VERSION ""

NS_ :

BS_:

BU_: IHU

BO_ 1177 IHU_26: 8 IHU
 SG_ IHU_26_RRWinCmd : 62|7@0+ (1,0) [0|127] "" Vector__XXX
 SG_ IHU_26_Reserved2 : 48|2@0+ (1,0) [0|0] "" Vector__XXX
 SG_ IHU_26_WiprSnvty : 51|3@0+ (1,0) [0|7] "" Vector__XXX
 SG_ IHU_26_SeatLegSpprtPosnCmd : 55|4@0+ (1,0) [0|15] "" Vector__XXX
 SG_ IHU_26_RLWinCmd : 46|7@0+ (1,0) [0|127] "" Vector__XXX
 SG_ IHU_26_FRWinCmd : 37|7@0+ (1,0) [0|127] "" Vector__XXX
 SG_ IHU_26_FLWinCmd : 28|7@0+ (1,0) [0|127] "" Vector__XXX
 SG_ IHU_26_Reserved1 : 29|1@0+ (1,0) [0|0] "" Vector__XXX
 SG_ IHU_26_CenterLockSwt : 31|2@0+ (1,0) [0|3] "" Vector__XXX
 SG_ IHU_26_SeatLvlPosnCmd : 23|4@0+ (1,0) [0|15] "" Vector__XXX
 SG_ IHU_26_SeatHdrestHeiAdjmtCmd : 19|4@0+ (1,0) [0|15] "" Vector__XXX
 SG_ IHU_26_WinInhbSwt : 15|1@0+ (1,0) [0|1] "" Vector__XXX
 SG_ IHU_26_ReWinDefrstSwt : 14|1@0+ (1,0) [0|1] "" Vector__XXX
 SG_ IHU_26_SteerWhlHeatgSwt : 13|1@0+ (1,0) [0|1] "" Vector__XXX
 SG_ IHU_26_BackrAgPosnCmd : 12|5@0+ (1,0) [0|31] "" Vector__XXX
 SG_ IHU_26_SeatCushPosnCmd : 7|4@0+ (1,0) [0|15] "" Vector__XXX
 SG_ IHU_26_SeatHeiPosnCmd : 3|4@0+ (1,0) [0|15] "" Vector__XXX

BO_ 643 IHU_25: 8 IHU
 SG_ IHU_25__Resd2 : 63|1@0+ (1,0) [0|0] "" Vector__XXX
 SG_ IHU_25_APPsts : 62|1@0+ (1,0) [0|1] "" Vector__XXX
 SG_ IHU_25_AmbLigFlngModSel : 58|3@0+ (1,0) [0|7] "" Vector__XXX
 SG_ IHU_25_AmbLig14FlngEna : 55|1@0+ (1,0) [0|1] "" Vector__XXX
 SG_ IHU_25_AmbLig13FlngEna : 47|1@0+ (1,0) [0|1] "" Vector__XXX
 SG_ IHU_25_AmbLig12FlngEna : 46|1@0+ (1,0) [0|1] "" Vector__XXX
 SG_ IHU_25_AmbLigFadeINOUTStepTi : 54|7@0+ (1,0) [0|127] "" Vector__XXX
 SG_ IHU_25_AmbLig14FadeEna : 45|1@0+ (1,0) [0|1] "" Vector__XXX
 SG_ IHU_25_AmbLig13FadeEna : 44|1@0+ (1,0) [0|1] "" Vector__XXX
 SG_ IHU_25_AmbLig12FadeEna : 43|1@0+ (1,0) [0|1] "" Vector__XXX
 SG_ IHU_25_AmbLig11FadeEna : 42|1@0+ (1,0) [0|1] "" Vector__XXX
 SG_ IHU_25_AmbLig10FadeEna : 41|1@0+ (1,0) [0|1] "" Vector__XXX
 SG_ IHU_25_AmbLig09FadeEna : 40|1@0+ (1,0) [0|1] "" Vector__XXX
 SG_ IHU_25_AmbLig08FadeEna : 39|1@0+ (1,0) [0|1] "" Vector__XXX
 SG_ IHU_25_AmbLig07FadeEna : 38|1@0+ (1,0) [0|1] "" Vector__XXX
 SG_ IHU_25_AmbLig06FadeEna : 37|1@0+ (1,0) [0|1] "" Vector__XXX
 SG_ IHU_25_AmbLig05FadeEna : 36|1@0+ (1,0) [0|1] "" Vector__XXX
 SG_ IHU_25_AmbLig04FadeEna : 35|1@0+ (1,0) [0|1] "" Vector__XXX
 SG_ IHU_25_AmbLig03FadeEna : 34|1@0+ (1,0) [0|1] "" Vector__XXX
 SG_ IHU_25_AmbLig02FadeEna : 33|1@0+ (1,0) [0|1] "" Vector__XXX
 SG_ IHU_25_AmbLig01FadeEna : 32|1@0+ (1,0) [0|1] "" Vector__XXX
 SG_ IHU_25_AmbLigColorAdj : 31|8@0+ (1,0) [0|255] "" Vector__XXX
 SG_ IHU_25_AmbLigBriAdj : 23|8@0+ (1,0) [0|100] "%" Vector__XXX
 SG_ IHU_25__Resd1 : 15|2@0+ (1,0) [0|0] "" Vector__XXX
 SG_ IHU_25_AmbLig14Authn : 13|1@0+ (1,0) [0|1] "" Vector__XXX
 SG_ IHU_25_AmbLig13Authn : 12|1@0+ (1,0) [0|1] "" Vector__XXX
 SG_ IHU_25_AmbLig12Authn : 11|1@0+ (1,0) [0|1] "" Vector__XXX
 SG_ IHU_25_AmbLig11Authn : 10|1@0+ (1,0) [0|1] "" Vector__XXX
 SG_ IHU_25_AmbLig10Authn : 9|1@0+ (1,0) [0|1] "" Vector__XXX
 SG_ IHU_25_AmbLig09Authn : 8|1@0+ (1,0) [0|1] "" Vector__XXX
 SG_ IHU_25_AmbLig08Authn : 7|1@0+ (1,0) [0|1] "" Vector__XXX
 SG_ IHU_25_AmbLig07Authn : 6|1@0+ (1,0) [0|1] "" Vector__XXX
 SG_ IHU_25_AmbLig06Authn : 5|1@0+ (1,0) [0|1] "" Vector__XXX
 SG_ IHU_25_AmbLig05Authn : 4|1@0+ (1,0) [0|1] "" Vector__XXX
 SG_ IHU_25_AmbLig04Authn : 3|1@0+ (1,0) [0|1] "" Vector__XXX
 SG_ IHU_25_AmbLig03Authn : 2|1@0+ (1,0) [0|1] "" Vector__XXX
 SG_ IHU_25_AmbLig02Authn : 1|1@0+ (1,0) [0|1] "" Vector__XXX
 SG_ IHU_25_AmbLig01Authn : 0|1@0+ (1,0) [0|1] "" Vector__XXX

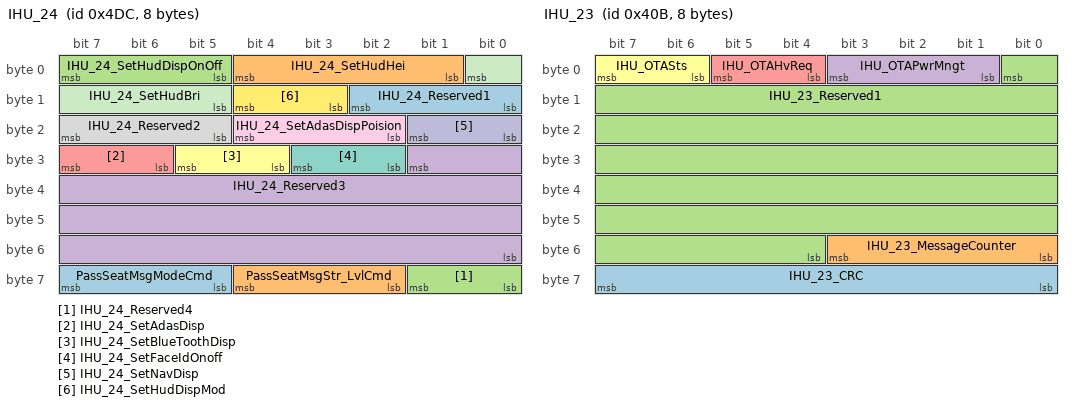
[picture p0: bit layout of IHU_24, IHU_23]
BO_ 1244 IHU_24: 8 IHU
 SG_ PassSeatMsgModeCmd : 63|3@0+ (1,0) [0|7] "" Vector__XXX
 SG_ PassSeatMsgStr_LvlCmd : 60|3@0+ (1,0) [0|7] "" Vector__XXX
 SG_ IHU_24_Reserved4 : 57|2@0+ (1,0) [0|0] "" Vector__XXX
 SG_ IHU_24_Reserved3 : 25|26@0+ (1,0) [0|0] "" Vector__XXX
 SG_ IHU_24_SetAdasDisp : 31|2@0+ (1,0) [0|3] "" Vector__XXX
 SG_ IHU_24_SetBlueToothDisp : 29|2@0+ (1,0) [0|3] "" Vector__XXX
 SG_ IHU_24_SetFaceIdOnoff : 27|2@0+ (1,0) [0|3] "" Vector__XXX
 SG_ IHU_24_Reserved2 : 23|3@0+ (1,0) [0|0] "" Vector__XXX
 SG_ IHU_24_SetAdasDispPoision : 20|3@0+ (1,0) [0|7] "" Vector__XXX
 SG_ IHU_24_SetNavDisp : 17|2@0+ (1,0) [0|3] "" Vector__XXX
 SG_ IHU_24_SetHudBri : 0|4@0+ (1,0) [0|15] "" Vector__XXX
 SG_ IHU_24_SetHudDispMod : 12|2@0+ (1,0) [0|3] "" Vector__XXX
 SG_ IHU_24_Reserved1 : 10|3@0+ (1,0) [0|0] "" Vector__XXX
 SG_ IHU_24_SetHudHei : 4|4@0+ (1,0) [0|15] "" Vector__XXX
 SG_ IHU_24_SetHudDispOnOff : 7|3@0+ (1,0) [0|7] "" Vector__XXX

BO_ 1035 IHU_23: 8 IHU
 SG_ IHU_23_CRC : 63|8@0+ (1,0) [0|255] "" Vector__XXX
 SG_ IHU_23_MessageCounter : 51|4@0+ (1,0) [0|15] "" Vector__XXX
 SG_ IHU_23_Reserved1 : 0|45@0+ (1,0) [0|0] "" Vector__XXX
 SG_ IHU_OTAPwrMngt : 3|3@0+ (1,0) [0|7] "" Vector__XXX
 SG_ IHU_OTAHvReq : 5|2@0+ (1,0) [0|3] "" Vector__XXX
 SG_ IHU_OTASts : 7|2@0+ (1,0) [0|3] "" Vector__XXX

BO_ 1278 IHU_22: 8 IHU
 SG_ IHU_22_Reserved1 : 53|14@0+ (1,0) [0|0] "" Vector__XXX
 SG_ IHU_SHU1RSeatAutVentnCmd : 55|2@0+ (1,0) [0|3] "" Vector__XXX
 SG_ IHU_SHU1LSeatAutVentnCmd : 41|2@0+ (1,0) [0|3] "" Vector__XXX
 SG_ IHU_SHU1RSeatAutHeatCmd : 45|2@0+ (1,0) [0|3] "" Vector__XXX
 SG_ IHU_SHU1LSeatAutHeatCmd : 43|2@0+ (1,0) [0|3] "" Vector__XXX
 SG_ SHU3RSeatVentilationCmd : 32|3@0+ (1,0) [0|7] "" Vector__XXX
 SG_ SHU3LSeatVentilationCmd : 35|3@0+ (1,0) [0|7] "" Vector__XXX
 SG_ SHU3RSeatHeatLevelCmd : 38|3@0+ (1,0) [0|7] "" Vector__XXX
 SG_ SHU3LSeatHeatLevelCmd : 25|3@0+ (1,0) [0|7] "" Vector__XXX
 SG_ SHU2RSeatVentilationCmd : 28|3@0+ (1,0) [0|7] "" Vector__XXX
 SG_ SHU2MSeatVentilationCmd : 31|3@0+ (1,0) [0|7] "" Vector__XXX
 SG_ SHU2LSeatVentilationCmd : 18|3@0+ (1,0) [0|7] "" Vector__XXX
 SG_ SHU2RSeatHeatLevelCmd : 21|3@0+ (1,0) [0|7] "" Vector__XXX
 SG_ SHU2MSeatHeatLevelCmd : 8|3@0+ (1,0) [0|7] "" Vector__XXX
 SG_ SHU2LSeatHeatLevelCmd : 11|3@0+ (1,0) [0|7] "" Vector__XXX
 SG_ SHU1RSeatVentilationCmd : 14|3@0+ (1,0) [0|7] "" Vector__XXX
 SG_ SHU1LSeatVentilationCmd : 1|3@0+ (1,0) [0|7] "" Vector__XXX
 SG_ SHU1RSeatHeatLevelCmd : 4|3@0+ (1,0) [0|7] "" Vector__XXX
 SG_ SHU1LSeatHeatLevelCmd : 7|3@0+ (1,0) [0|7] "" Vector__XXX

BO_ 1119 IHU_19: 8 IHU
 SG_ IHU_19_Reserved_1 : 53|14@0+ (1,0) [0|0] "" Vector__XXX
 SG_ IHU_19_Set_HdrestSpkrMod : 40|3@0+ (1,0) [0|7] "" Vector__XXX
 SG_ IHU_19_Set_AMPESEVol : 46|6@0+ (1,0) [0|63] "" Vector__XXX
 SG_ IHU_19_Set_AMPWelVol : 36|6@0+ (1,0) [0|63] "" Vector__XXX
 SG_ IHU_19_Set_AMPBTMediVol : 26|6@0+ (1,0) [0|63] "" Vector__XXX
 SG_ IHU_19_REQ_AMPA2BMediSound : 29|3@0+ (1,0) [0|7] "" Vector__XXX
 SG_ IHU_19_REQ_AMPA2BESESound : 31|2@0+ (1,0) [0|3] "" Vector__XXX
 SG_ IHU_19_PABSetCmd : 17|2@0+ (1,0) [0|3] "" Vector__XXX
 SG_ IHU_19_HwSet : 19|2@0+ (1,0) [0|3] "" Vector__XXX
 SG_ IHU_19_BSRBPASet : 21|2@0+ (1,0) [0|3] "" Vector__XXX
 SG_ REQ_AMPA2BKeyTone : 23|2@0+ (1,0) [0|3] "" Vector__XXX
 SG_ REQ_AMPA2BTTSSound : 15|2@0+ (1,0) [0|3] "" Vector__XXX
 SG_ REQ_AMPA2BVRSound : 13|2@0+ (1,0) [0|3] "" Vector__XXX
 SG_ REQ_AMPA2BNaviSound : 11|2@0+ (1,0) [0|3] "" Vector__XXX
 SG_ IHU_19_Reserved_2 : 9|2@0+ (1,0) [0|3] "" Vector__XXX
 SG_ Set_AMPMute : 7|2@0+ (1,0) [0|3] "" Vector__XXX
 SG_ Set_AMPSpeedVolume : 5|3@0+ (1,0) [0|7] "" Vector__XXX
 SG_ REQ_AMPA2BPhoneSound : 2|3@0+ (1,0) [0|7] "" Vector__XXX

BO_ 1100 IHU_18: 8 IHU
 SG_ Set_AMPAlarmVolume : 63|4@0+ (1,0) [1|15] "" Vector__XXX
 SG_ Set_AMPLoudness : 59|2@0+ (1,0) [0|3] "" Vector__XXX
 SG_ Set_AMPLiveAcoustics : 57|2@0+ (1,0) [0|3] "" Vector__XXX
 SG_ Set_AMPSoundFieldFader : 55|4@0+ (1,0) [0|15] "" Vector__XXX
 SG_ Set_AMPSoundFieldBalance : 51|4@0+ (1,0) [0|15] "" Vector__XXX
 SG_ Set_AMPSoundEffectTreble : 47|4@0+ (1,0) [0|15] "" Vector__XXX
 SG_ Set_AMPSoundEffectMidrange : 43|4@0+ (1,0) [0|15] "" Vector__XXX
 SG_ Set_AMPSoundEffectBass : 39|4@0+ (1,0) [0|15] "" Vector__XXX
 SG_ Set_AMPSoundEffect : 35|4@0+ (1,0) [0|15] "" Vector__XXX
 SG_ Set_AMPRestoreDefaults : 31|2@0+ (1,0) [0|3] "" Vector__XXX
 SG_ Set_AMPDefaultVolume : 29|6@0+ (1,0) [0|63] "" Vector__XXX
 SG_ Set_AMPSoundFocus : 23|3@0+ (1,0) [0|7] "" Vector__XXX
 SG_ Set_AMPPhoneVolume : 20|5@0+ (1,0) [0|31] "" Vector__XXX
 SG_ Set_AMPMediaVolume : 15|6@0+ (1,0) [0|63] "" Vector__XXX
 SG_ Set_AMPKeyTone : 9|2@0+ (1,0) [0|3] "" Vector__XXX
 SG_ Set_AMPVRVolume : 7|4@0+ (1,0) [0|15] "" Vector__XXX
 SG_ Set_AMPNaviVolume : 3|4@0+ (1,0) [0|15] "" Vector__XXX

BO_ 1065 IHU_16: 8 IHU
 SG_ IHU_16_Reserved3 : 42|19@0+ (1,0) [0|0] "" Vector__XXX
 SG_ IHU_16_SetReRowPwrKeyCmd : 43|1@0+ (1,0) [0|1] "" Vector__XXX
 SG_ IHU_16_SetReRowBlowSpdLvlCmd : 46|3@0+ (1,0) [0|7] "" Vector__XXX
 SG_ IHU_16_SetReRowWorkCmd : 47|1@0+ (1,0) [0|1] "" Vector__XXX
 SG_ IHU_FragranceDisplayReq : 33|2@0+ (1,0) [0|3] "" Vector__XXX
 SG_ IHU_PM2_5AutoRunSet : 35|2@0+ (1,0) [0|3] "" Vector__XXX
 SG_ IHU_ANIONSwitch : 37|2@0+ (1,0) [0|3] "" Vector__XXX
 SG_ IHU_RefreshFunction : 39|2@0+ (1,0) [0|3] "" Vector__XXX
 SG_ IHU_ACModeCustom : 31|3@0+ (1,0) [0|7] "" Vector__XXX
 SG_ IHU_FragranCeconsistenceLevel : 28|3@0+ (1,0) [0|7] "" Vector__XXX
 SG_ IHU_FragranceSW : 25|2@0+ (1,0) [0|3] "" Vector__XXX
 SG_ IHU_16_Reserved2 : 18|3@0+ (1,0) [0|0] "" Vector__XXX
 SG_ IHU_16_SetSeBlowSpdLvlDisp : 23|3@0+ (1,0) [0|7] "" Vector__XXX
 SG_ IHU_16_SetSeWorking : 20|1@0+ (1,0) [0|1] "" Vector__XXX
 SG_ IHU_16_SeIntelligentCustom : 19|1@0+ (1,0) [0|1] "" Vector__XXX
 SG_ IHU_16_SetPtcHeatg : 13|1@0+ (1,0) [0|1] "" Vector__XXX
 SG_ IHU_FragranceWelcomeMode : 15|2@0+ (1,0) [0|3] "" Vector__XXX
 SG_ IHU_FragrancePosition : 12|3@0+ (1,0) [0|7] "" Vector__XXX
 SG_ IHU_16_Reserved4 : 9|2@0+ (1,0) [0|0] "" Vector__XXX
 SG_ IHU_AutoBlueCallBlowSpeed : 7|2@0+ (1,0) [0|3] "" Vector__XXX
 SG_ IHU_AutoParkInnerCirculation : 5|2@0+ (1,0) [0|3] "" Vector__XXX
 SG_ IHU_16_Reserved1 : 3|4@0+ (1,0) [0|0] "" Vector__XXX

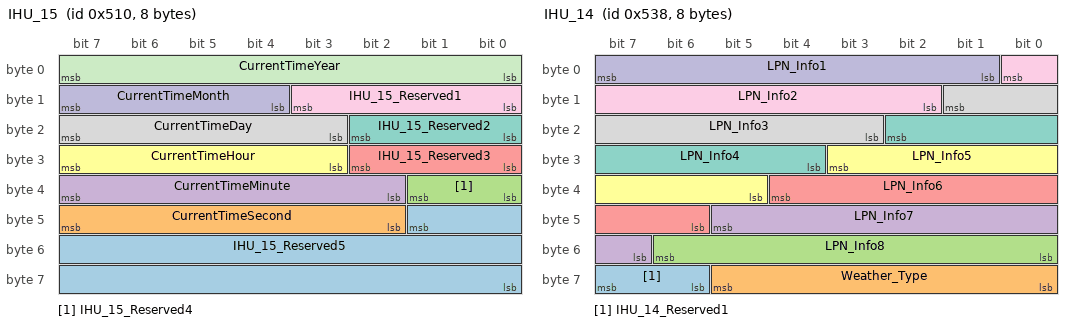
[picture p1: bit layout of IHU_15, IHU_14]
BO_ 1296 IHU_15: 8 IHU
 SG_ IHU_15_Reserved5 : 41|18@0+ (1,0) [0|0] "" Vector__XXX
 SG_ CurrentTimeSecond : 47|6@0+ (1,0) [0|59] "" Vector__XXX
 SG_ IHU_15_Reserved4 : 33|2@0+ (1,0) [0|0] "" Vector__XXX
 SG_ CurrentTimeMinute : 39|6@0+ (1,0) [0|59] "" Vector__XXX
 SG_ IHU_15_Reserved3 : 26|3@0+ (1,0) [0|0] "" Vector__XXX
 SG_ CurrentTimeHour : 31|5@0+ (1,0) [0|23] "" Vector__XXX
 SG_ IHU_15_Reserved2 : 18|3@0+ (1,0) [0|0] "" Vector__XXX
 SG_ CurrentTimeDay : 23|5@0+ (1,0) [1|31] "" Vector__XXX
 SG_ IHU_15_Reserved1 : 11|4@0+ (1,0) [0|0] "" Vector__XXX
 SG_ CurrentTimeMonth : 15|4@0+ (1,0) [1|12] "" Vector__XXX
 SG_ CurrentTimeYear : 7|8@0+ (1,2000) [2000|2255] "" Vector__XXX

BO_ 1336 IHU_14: 8 IHU
 SG_ IHU_14_Reserved1 : 63|2@0+ (1,0) [0|0] "" Vector__XXX
 SG_ Weather_Type : 61|6@0+ (1,0) [0|63] "" Vector__XXX
 SG_ LPN_Info8 : 54|7@0+ (1,0) [0|127] "" Vector__XXX
 SG_ LPN_Info7 : 45|7@0+ (1,0) [0|127] "" Vector__XXX
 SG_ LPN_Info6 : 36|7@0+ (1,0) [0|127] "" Vector__XXX
 SG_ LPN_Info5 : 27|7@0+ (1,0) [0|127] "" Vector__XXX
 SG_ LPN_Info4 : 18|7@0+ (1,0) [0|127] "" Vector__XXX
 SG_ LPN_Info3 : 9|7@0+ (1,0) [0|127] "" Vector__XXX
 SG_ LPN_Info2 : 0|7@0+ (1,0) [0|127] "" Vector__XXX
 SG_ LPN_Info1 : 7|7@0+ (1,0) [0|127] "" Vector__XXX

BO_ 1112 IHU_13: 8 IHU
 SG_ HU_13_Reserved8 : 63|8@0+ (1,0) [0|0] "" Vector__XXX
 SG_ IHU_13_Reserved7 : 55|3@0+ (1,0) [0|0] "" Vector__XXX
 SG_ MusicLoudness_6000HZ : 52|5@0+ (1,0) [0|31] "" Vector__XXX
 SG_ IHU_13_Reserved6 : 47|3@0+ (1,0) [0|0] "" Vector__XXX
 SG_ MusicLoudness_2000HZ : 44|5@0+ (1,0) [0|31] "" Vector__XXX
 SG_ IHU_13_Reserved5 : 39|3@0+ (1,0) [0|0] "" Vector__XXX
 SG_ MusicLoudness_1500HZ : 36|5@0+ (1,0) [0|31] "" Vector__XXX
 SG_ IHU_13_Reserved4 : 31|2@0+ (1,0) [0|0] "" Vector__XXX
 SG_ MusicShowCMD : 29|1@0+ (1,0) [0|1] "" Vector__XXX
 SG_ MusicLoudness_1000HZ : 28|5@0+ (1,0) [0|31] "" Vector__XXX
 SG_ IHU_13_Reserved3 : 23|3@0+ (1,0) [0|0] "" Vector__XXX
 SG_ MusicLoudness_500HZ : 20|5@0+ (1,0) [0|31] "" Vector__XXX
 SG_ LiShowMod : 15|3@0+ (1,0) [0|7] "" Vector__XXX
 SG_ MusicLoudness_250HZ : 12|5@0+ (1,0) [0|31] "" Vector__XXX
 SG_ ADBenable : 7|2@0+ (1,0) [0|3] "" Vector__XXX
 SG_ DVD_StandbyModeSts : 5|1@0+ (1,0) [0|1] "" Vector__XXX
 SG_ MusicLoudness_120HZ : 4|5@0+ (1,0) [0|31] "" Vector__XXX

BO_ 1114 IHU_12: 8 IHU
 SG_ MusicShowCMD : 57|2@0+ (1,0) [0|3] "" Vector__XXX
 SG_ IHU_12_Reserved8 : 63|3@0+ (1,0) [0|0] "" Vector__XXX
 SG_ LightShowCmd : 60|3@0+ (1,0) [0|7] "" Vector__XXX
 SG_ DVRSnapshot : 51|1@0+ (1,0) [0|1] "" Vector__XXX
 SG_ AVMSwt : 50|1@0+ (1,0) [0|1] "" Vector__XXX
 SG_ IHU_12_Reserved6 : 49|2@0+ (1,0) [0|0] "" Vector__XXX
 SG_ TouchEvt : 53|2@0+ (1,0) [0|3] "" Vector__XXX
 SG_ LDWSensitivitySetting : 55|2@0+ (1,0) [0|3] "" Vector__XXX
 SG_ IHU_APAKeySts : 40|1@0+ (1,0) [0|1] "" Vector__XXX
 SG_ IHU_12_Reserved4 : 43|3@0+ (1,0) [0|0] "" Vector__XXX
 SG_ LDWSwitchSts : 45|2@0+ (1,0) [0|3] "" Vector__XXX
 SG_ IHU_12_Reserved3 : 47|2@0+ (1,0) [0|0] "" Vector__XXX
 SG_ IHU_12_DMSSwtSet : 39|2@0+ (1,0) [0|3] "" Vector__XXX
 SG_ IHU_12_CarMdlSetColor : 37|4@0+ (1,0) [0|15] "" Vector__XXX
 SG_ CalibrationReq : 33|1@0+ (1,0) [0|1] "" Vector__XXX
 SG_ RRMDisplayAVMOff : 32|1@0+ (1,0) [0|1] "" Vector__XXX
 SG_ NaviBtnPressInputValueY : 23|16@0+ (1,0) [0|65534] "Pixel" Vector__XXX
 SG_ NaviBtnPressInputValueX : 7|16@0+ (1,0) [0|65534] "Pixel" Vector__XXX

BO_ 1276 IHU_11: 8 IHU
 SG_ IHU_11_Reserved3 : 59|4@0+ (1,0) [0|0] "" Vector__XXX
 SG_ IHU_11_ASUStyleSet : 61|2@0+ (1,0) [0|3] "" Vector__XXX
 SG_ IHU_11_ASUAssocWithDrvrModSet : 63|2@0+ (1,0) [0|3] "" Vector__XXX
 SG_ DVD_SET_EPS_Assistance_Style : 49|2@0+ (1,0) [0|3] "" Vector__XXX
 SG_ DVD_SET_EPS_AssociWithDriverMode : 51|2@0+ (1,0) [0|3] "" Vector__XXX
 SG_ IHU_11_ELKSwtSet : 53|2@0+ (1,0) [0|3] "" Vector__XXX
 SG_ IHU_11_LDWLDPSnvtySet : 55|2@0+ (1,0) [0|3] "" Vector__XXX
 SG_ IHU_11_LDPSwtSet : 41|2@0+ (1,0) [0|3] "" Vector__XXX
 SG_ IHU_11_WarnModSwtSet : 43|2@0+ (1,0) [0|3] "" Vector__XXX
 SG_ IHU_11_LDWSwtSet : 45|2@0+ (1,0) [0|3] "" Vector__XXX
 SG_ IHU_11_TLISwtSet : 47|2@0+ (1,0) [0|3] "" Vector__XXX
 SG_ IHU_11_TSISwtSet : 33|2@0+ (1,0) [0|3] "" Vector__XXX
 SG_ IHU_11_HMASwtSet : 35|2@0+ (1,0) [0|3] "" Vector__XXX
 SG_ IHU_11_IESSwtSet : 37|2@0+ (1,0) [0|3] "" Vector__XXX
 SG_ IHU_11_DAISwtSet : 39|2@0+ (1,0) [0|3] "" Vector__XXX
 SG_ IHU_11_Resd2 : 25|2@0+ (1,0) [0|3] "" Vector__XXX
 SG_ IHU_11_SCFSwtSet : 27|2@0+ (1,0) [0|3] "" Vector__XXX
 SG_ IHU_11_SLASwtSet : 29|2@0+ (1,0) [0|3] "" Vector__XXX
 SG_ IHU_11_TJAICAExitTextInfoSwtSet : 31|2@0+ (1,0) [0|3] "" Vector__XXX
 SG_ IHU_11_FCWSwtSet : 17|2@0+ (1,0) [0|3] "" Vector__XXX
 SG_ IHU_11_FCWSnvtySet : 19|2@0+ (1,0) [0|3] "" Vector__XXX
 SG_ IHU_11_AEBSwtSet : 21|2@0+ (1,0) [0|3] "" Vector__XXX
 SG_ IHU_11_RCTBSwtSet : 23|2@0+ (1,0) [0|3] "" Vector__XXX
 SG_ IHU_11_RAEBSwtSet : 9|2@0+ (1,0) [0|3] "" Vector__XXX
 SG_ IHU_11_BSDSwitchSts : 11|2@0+ (1,0) [0|3] "" Vector__XXX
 SG_ DVD_SET_RCW : 13|2@0+ (1,0) [0|3] "" Vector__XXX
 SG_ DVD_SET_DOW : 15|2@0+ (1,0) [0|3] "" Vector__XXX
 SG_ IHU_11_Reserved1 : 0|1@0+ (1,0) [0|0] "" Vector__XXX
 SG_ DVD_SET_CWC_PhoneforgottenFunSts : 2|2@0+ (1,0) [0|3] "" Vector__XXX
 SG_ ModeKeySts : 3|1@0+ (1,0) [0|1] "" Vector__XXX
 SG_ DVD_SET_ModeKeyFunctionType : 5|2@0+ (1,0) [0|3] "" Vector__XXX
 SG_ DVD_SET_CWC_WorkingSts : 7|2@0+ (1,0) [0|3] "" Vector__XXX

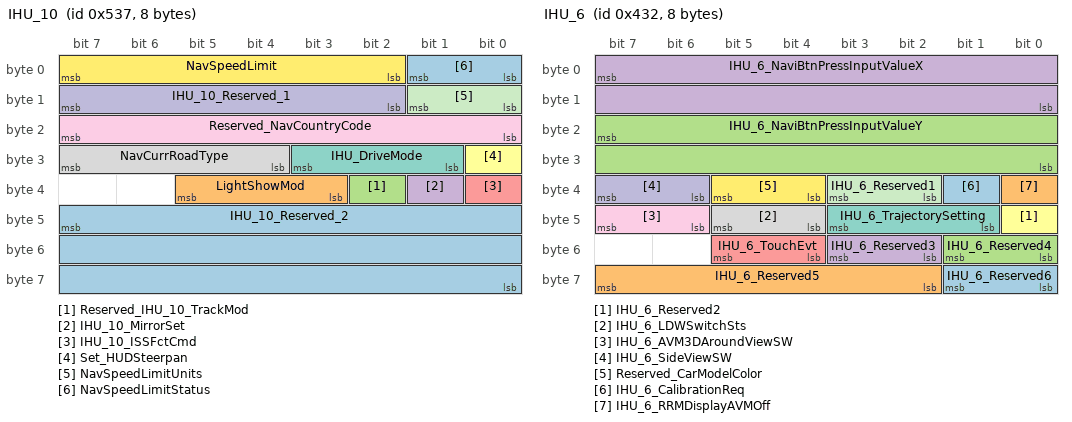
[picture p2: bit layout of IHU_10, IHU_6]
BO_ 1335 IHU_10: 8 IHU
 SG_ IHU_10_Reserved_2 : 47|24@0+ (1,0) [0|0] "" Vector__XXX
 SG_ LightShowMod : 37|3@0+ (1,0) [0|7] "" Vector__XXX
 SG_ Reserved_IHU_10_TrackMod : 34|1@0+ (1,0) [0|1] "" Vector__XXX
 SG_ IHU_10_MirrorSet : 33|1@0+ (1,0) [0|1] "" Vector__XXX
 SG_ IHU_10_ISSFctCmd : 32|1@0+ (1,0) [0|1] "" Vector__XXX
 SG_ Set_HUDSteerpan : 24|1@0+ (1,0) [0|1] "" Vector__XXX
 SG_ IHU_DriveMode : 27|3@0+ (1,0) [0|7] "" Vector__XXX
 SG_ NavCurrRoadType : 31|4@0+ (1,0) [0|15] "" Vector__XXX
 SG_ Reserved_NavCountryCode : 23|8@0+ (1,0) [0|255] "" Vector__XXX
 SG_ IHU_10_Reserved_1 : 15|6@0+ (1,0) [0|0] "" Vector__XXX
 SG_ NavSpeedLimitUnits : 9|2@0+ (1,0) [0|3] "" Vector__XXX
 SG_ NavSpeedLimit : 7|6@0+ (1,0) [0|59] "" Vector__XXX
 SG_ NavSpeedLimitStatus : 1|2@0+ (1,0) [0|3] "" Vector__XXX

BO_ 1273 IHU_9: 8 IHU
 SG_ IHU_SET_AIPMBrightnessLevel : 55|4@0+ (1,0) [0|15] "" Vector__XXX
 SG_ DVD_SetLightedRoofRackStatus : 47|2@0+ (1,0) [0|3] "" Vector__XXX
 SG_ DrvrDoorUnlckOnlyStsSet : 45|2@0+ (1,0) [0|3] "" Vector__XXX
 SG_ BlowSpeedLevelKeySts : 43|4@0+ (1,0) [0|15] "" Vector__XXX
 SG_ IHU_SetTheaterDimmingColor_64 : 39|8@0+ (1,0) [0|255] "" Vector__XXX
 SG_ IHU_9_FrntRadarSwt : 24|1@0+ (1,0) [0|1] "" Vector__XXX
 SG_ IHU_DriverSeatHeatLevelCmd : 63|2@0+ (1,0) [0|3] "" Vector__XXX
 SG_ DVD_SET_BLTKey_PESts : 61|2@0+ (1,0) [0|3] "" Vector__XXX
 SG_ FaceID : 29|3@0+ (1,0) [0|7] "" Vector__XXX
 SG_ Delete_ID_Info : 16|3@0+ (1,0) [0|7] "" Vector__XXX
 SG_ DVD_SET_AutoFoldSts : 59|2@0+ (1,0) [0|3] "" Vector__XXX
 SG_ IHU_DriverSeatVentilationKeySts : 57|2@0+ (1,0) [0|3] "" Vector__XXX
 SG_ DVD_SET_HeadlampHeightSts : 19|3@0+ (1,0) [0|7] "" Vector__XXX
 SG_ Reserved_SASSwitchStatus : 23|2@0+ (1,0) [0|3] "" Vector__XXX
 SG_ Reserved_DVD_SET_RemoteTrunkOnly : 21|2@0+ (1,0) [0|3] "" Vector__XXX
 SG_ Reserved_DVD_SET_UrgeBrakemode : 15|2@0+ (1,0) [0|3] "" Vector__XXX
 SG_ Reserved_DVD_SET_AidTurnIlumin : 13|2@0+ (1,0) [0|3] "" Vector__XXX
 SG_ DVD_SET_DRLModeSts : 11|2@0+ (1,0) [0|3] "" Vector__XXX
 SG_ DVD_SET_HeadlampDelayLightSts : 9|2@0+ (1,0) [0|3] "" Vector__XXX
 SG_ DVD_SET_RemoteLockFeedback : 7|3@0+ (1,0) [0|7] "" Vector__XXX
 SG_ IHU_ISS_Switch : 4|1@0+ (1,0) [0|1] "" Vector__XXX
 SG_ DVD_SET_AutolockSts : 3|2@0+ (1,0) [0|3] "" Vector__XXX
 SG_ Reserved_DVD_SET_AutoUnlockSts : 1|2@0+ (1,0) [0|3] "" Vector__XXX

BO_ 1272 IHU_8: 8 IHU
 SG_ DVD_Set_FGHeatSts : 57|2@0+ (1,0) [0|3] "" Vector__XXX
 SG_ IHU_WindowCmd : 62|5@0+ (1,0) [0|31] "" Vector__XXX
 SG_ IHU_8_Reserved_2 : 48|2@0+ (1,0) [0|0] "" Vector__XXX
 SG_ Set_Default : 44|3@0+ (1,0) [0|7] "" Vector__XXX
 SG_ Seat_ExtMirror_PosStoreReq_ID : 33|5@0+ (1,0) [0|31] "" Vector__XXX
 SG_ Seat_ExtMirror_PosRecall_ID : 38|5@0+ (1,0) [0|31] "" Vector__XXX
 SG_ DVD_Set_ReverseExtMirrorSts : 25|3@0+ (1,0) [0|7] "" Vector__XXX
 SG_ DVD_Set_EasyEntrySts : 27|2@0+ (1,0) [0|3] "" Vector__XXX
 SG_ DVD_SetSCURelateKeyOrFaceID : 41|2@0+ (1,0) [0|3] "" Vector__XXX
 SG_ DVD_SetAssociatedWithMusicMode : 29|2@0+ (1,0) [0|3] "" Vector__XXX
 SG_ DVD_SetAssociatedWithDriverMode : 31|2@0+ (1,0) [0|3] "" Vector__XXX
 SG_ DVD_SetTheaterDimmingBrightness : 18|3@0+ (1,0) [0|7] "" Vector__XXX
 SG_ SetTheaterDimmingColor : 21|3@0+ (1,0) [0|7] "" Vector__XXX
 SG_ DVD_SetTheaterDimmingStatus : 23|2@0+ (1,0) [0|3] "" Vector__XXX
 SG_ Reserved_Set_MFS_Stuck_Duration : 55|3@0+ (1,0) [0|7] "" Vector__XXX
 SG_ Set_WelLightPolling : 9|2@0+ (1,0) [0|3] "" Vector__XXX
 SG_ Set_PEPS_IntelligentOpen : 11|2@0+ (1,0) [0|3] "" Vector__XXX
 SG_ Set_PEPS_Polling : 13|2@0+ (1,0) [0|3] "" Vector__XXX
 SG_ IHU_8_Reserved_1 : 7|1@0+ (1,0) [0|0] "" Vector__XXX
 SG_ IHU_8_SunshadeCmd : 15|2@0+ (1,0) [0|3] "" Vector__XXX
 SG_ IHU_PSRFCmd : 6|4@0+ (1,0) [0|15] "" Vector__XXX
 SG_ IHU_SRFCmd : 2|3@0+ (1,0) [0|7] "" Vector__XXX

BO_ 1309 IHU_7: 8 IHU
 SG_ LDWOnOffReq : 54|2@0+ (1,0) [0|3] "" Vector__XXX
 SG_ IHU_7_Reserved_6 : 63|8@0+ (1,0) [0|0] "" Vector__XXX
 SG_ TimeGapLastSetReq : 49|2@0+ (1,0) [0|3] "" Vector__XXX
 SG_ IHU_7_Reserved_5 : 55|1@0+ (1,0) [0|0] "" Vector__XXX
 SG_ IHU_7_Reserved_4 : 52|1@0+ (1,0) [0|0] "" Vector__XXX
 SG_ LDW_LKA_SensitivityReq : 51|2@0+ (1,0) [0|3] "" Vector__XXX
 SG_ IHU_7_Reserved_3 : 47|2@0+ (1,0) [0|0] "" Vector__XXX
 SG_ IHU_7_DrvAssiStyle : 45|2@0+ (1,0) [0|3] "" Vector__XXX
 SG_ IHU_7_DCLCONOFF : 43|2@0+ (1,0) [0|3] "" Vector__XXX
 SG_ HMAOnOffReq : 41|2@0+ (1,0) [0|3] "" Vector__XXX
 SG_ IHU_AutHldSet : 39|2@0+ (1,0) [0|3] "" Vector__XXX
 SG_ IHU_7_Reserved_8 : 37|2@0+ (1,0) [0|0] "" Vector__XXX
 SG_ SCF_ON_OFF : 33|2@0+ (1,0) [0|3] "" Vector__XXX
 SG_ SLAOnOffReq : 35|2@0+ (1,0) [0|3] "" Vector__XXX
 SG_ IHU_7_Reserved_1 : 8|5@0+ (1,0) [0|0] "" Vector__XXX
 SG_ IHU_7_Reserved_7 : 19|2@0+ (1,0) [0|0] "" Vector__XXX
 SG_ Set_ESPFunctionSts : 17|2@0+ (1,0) [0|3] "" Vector__XXX
 SG_ TIHU_SetHDCOnOff : 31|2@0+ (1,0) [0|3] "" Vector__XXX
 SG_ CST_SensitivityReq : 29|2@0+ (1,0) [0|3] "" Vector__XXX
 SG_ BrakepedalfeelModeSetReq : 27|2@0+ (1,0) [0|3] "" Vector__XXX
 SG_ IHU_AssociateDriveModeSet : 25|2@0+ (1,0) [0|3] "" Vector__XXX
 SG_ Set_CSTFunctionSts : 10|2@0+ (1,0) [0|3] "" Vector__XXX
 SG_ DistanceWarning_on_off : 12|2@0+ (1,0) [0|3] "" Vector__XXX
 SG_ TJA_ICA_ON_OFF : 14|2@0+ (1,0) [0|3] "" Vector__XXX
 SG_ AEB_ON_OFF : 0|2@0+ (1,0) [0|3] "" Vector__XXX
 SG_ FCW_OPTION : 7|2@0+ (1,0) [0|3] "" Vector__XXX
 SG_ FCW_ON_OFF : 5|2@0+ (1,0) [0|3] "" Vector__XXX
 SG_ TimeGapSet1Req : 3|3@0+ (1,0) [0|7] "" Vector__XXX

BO_ 1074 IHU_6: 8 IHU
 SG_ IHU_6_Reserved6 : 57|2@0+ (1,0) [0|0] "" Vector__XXX
 SG_ IHU_6_Reserved5 : 63|6@0+ (1,0) [0|0] "" Vector__XXX
 SG_ IHU_6_Reserved4 : 49|2@0+ (1,0) [0|0] "" Vector__XXX
 SG_ IHU_6_Reserved3 : 51|2@0+ (1,0) [0|0] "" Vector__XXX
 SG_ IHU_6_TouchEvt : 53|2@0+ (1,0) [0|3] "" Vector__XXX
 SG_ IHU_6_Reserved2 : 40|1@0+ (1,0) [0|0] "" Vector__XXX
 SG_ IHU_6_TrajectorySetting : 43|3@0+ (1,0) [0|7] "" Vector__XXX
 SG_ IHU_6_LDWSwitchSts : 45|2@0+ (1,0) [0|3] "" Vector__XXX
 SG_ IHU_6_AVM3DAroundViewSW : 47|2@0+ (1,0) [0|3] "" Vector__XXX
 SG_ IHU_6_SideViewSW : 39|2@0+ (1,0) [0|3] "" Vector__XXX
 SG_ IHU_6_Reserved1 : 35|2@0+ (1,0) [0|0] "" Vector__XXX
 SG_ Reserved_CarModelColor : 37|2@0+ (1,0) [0|0] "" Vector__XXX
 SG_ IHU_6_CalibrationReq : 33|1@0+ (1,0) [0|1] "" Vector__XXX
 SG_ IHU_6_RRMDisplayAVMOff : 32|1@0+ (1,0) [0|1] "" Vector__XXX
 SG_ IHU_6_NaviBtnPressInputValueY : 23|16@0+ (1,0) [0|65534] "Pixel" Vector__XXX
 SG_ IHU_6_NaviBtnPressInputValueX : 7|16@0+ (1,0) [0|65534] "Pixel" Vector__XXX

BO_ 1305 IHU_4: 8 IHU
 SG_ AUTODefrostOnKeySts : 61|2@0+ (1,0) [0|3] "" Vector__XXX
 SG_ PM2_5DisplayReq : 57|2@0+ (1,0) [0|3] "" Vector__XXX
 SG_ DVD_SET_PM2_5Sts : 55|2@0+ (1,0) [0|3] "" Vector__XXX
 SG_ BlowDelayOffKeySts : 47|2@0+ (1,0) [0|3] "" Vector__XXX
 SG_ BlowAdvanceOnKeySts : 45|2@0+ (1,0) [0|3] "" Vector__XXX
 SG_ IHU_4_Reserved1 : 37|1@0+ (1,0) [0|0] "" Vector__XXX
 SG_ ElecClimateSetTemp : 36|5@0+ (1,0) [0|31] "" Vector__XXX
 SG_ SetTemperature_R_F : 26|5@0+ (2,58) [58|90] "℉" Vector__XXX
 SG_ SetTemperature_L_F : 31|5@0+ (2,58) [58|90] "℉" Vector__XXX
 SG_ DVD_ZoneSelectionKeySts : 53|2@0+ (1,0) [0|3] "" Vector__XXX
 SG_ DVD_SetCirculationModeKeySts : 51|2@0+ (1,0) [0|3] "" Vector__XXX
 SG_ SetTemperature_R_C : 22|5@0+ (1,15) [15|31] "℃" Vector__XXX
 SG_ SetTemperature_L_C : 11|5@0+ (1,15) [15|31] "℃" Vector__XXX
 SG_ Set_TimeAMPM : 17|2@0+ (1,0) [0|3] "" Vector__XXX
 SG_ IHU_4_Reserved4 : 12|1@0+ (1,0) [0|0] "" Vector__XXX
 SG_ ModeAdjustKeySts : 15|3@0+ (1,0) [0|7] "" Vector__XXX
 SG_ Reserved_DVD_SetAC_MaxKeySts : 49|2@0+ (1,0) [0|3] "" Vector__XXX
 SG_ DVD_SetTemperatureUnit : 59|2@0+ (1,0) [0|3] "" Vector__XXX
 SG_ DVD_SetMaxFrontDeforestSts : 7|2@0+ (1,0) [0|3] "" Vector__XXX
 SG_ BlowSpeedLevelKeySts : 5|3@0+ (1,0) [0|7] "" Vector__XXX
 SG_ DVD_SetAutoKeySts : 63|2@0+ (1,0) [0|3] "" Vector__XXX
 SG_ DVD_SetACRequestKeySts : 43|2@0+ (1,0) [0|3] "" Vector__XXX
 SG_ DVD_SetCLMOn : 41|2@0+ (1,0) [0|3] "" Vector__XXX
 SG_ Set_Time24H12H : 2|2@0+ (1,0) [0|3] "" Vector__XXX
 SG_ IHU_4_CVBOXRstReq : 0|1@0+ (1,0) [0|1] "" Vector__XXX

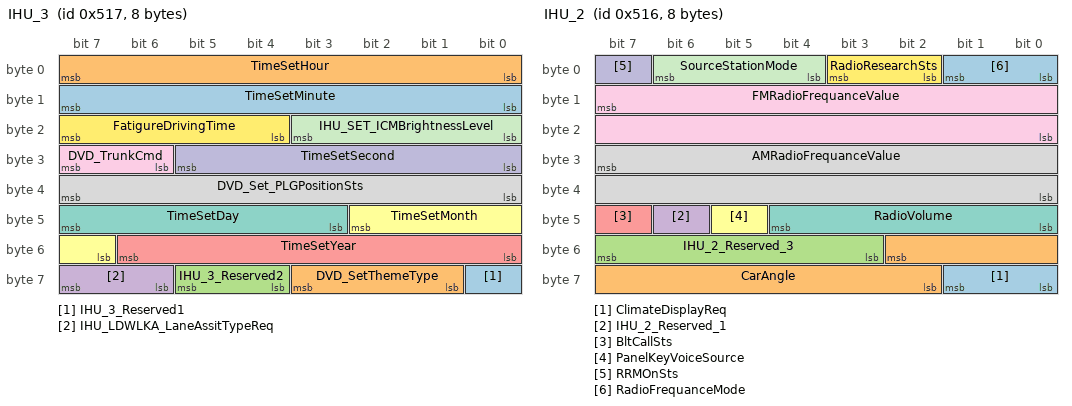
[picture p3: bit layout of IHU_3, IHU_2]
BO_ 1303 IHU_3: 8 IHU
 SG_ IHU_3_Reserved1 : 56|1@0+ (1,0) [0|0] "" Vector__XXX
 SG_ DVD_SetThemeType : 59|3@0+ (1,0) [0|7] "" Vector__XXX
 SG_ IHU_3_Reserved2 : 61|2@0+ (1,0) [0|0] "" Vector__XXX
 SG_ IHU_LDWLKA_LaneAssitTypeReq : 63|2@0+ (1,0) [0|3] "" Vector__XXX
 SG_ TimeSetYear : 54|7@0+ (1,2000) [2000|2127] "" Vector__XXX
 SG_ TimeSetMonth : 42|4@0+ (1,0) [1|12] "" Vector__XXX
 SG_ TimeSetDay : 47|5@0+ (1,0) [1|31] "" Vector__XXX
 SG_ DVD_Set_PLGPositionSts : 39|8@0+ (1,0) [0|100] "%" Vector__XXX
 SG_ DVD_TrunkCmd : 31|2@0+ (1,0) [0|3] "" Vector__XXX
 SG_ TimeSetSecond : 29|6@0+ (1,0) [0|59] "" Vector__XXX
 SG_ IHU_SET_ICMBrightnessLevel : 19|4@0+ (1,0) [0|15] "" Vector__XXX
 SG_ FatigureDrivingTime : 23|4@0+ (1,0) [0|15] "" Vector__XXX
 SG_ TimeSetMinute : 15|8@0+ (1,0) [0|59] "" Vector__XXX
 SG_ TimeSetHour : 7|8@0+ (1,0) [0|23] "" Vector__XXX

BO_ 1302 IHU_2: 8 IHU
 SG_ ClimateDisplayReq : 57|2@0+ (1,0) [0|3] "" Vector__XXX
 SG_ CarAngle : 50|9@0+ (1,0) [1|360] "deg" Vector__XXX
 SG_ IHU_2_Reserved_3 : 55|5@0+ (1,0) [0|0] "" Vector__XXX
 SG_ IHU_2_Reserved_1 : 46|1@0+ (1,0) [0|0] "" Vector__XXX
 SG_ BltCallSts : 47|1@0+ (1,0) [0|1] "" Vector__XXX
 SG_ PanelKeyVoiceSource : 45|1@0+ (1,0) [0|1] "" Vector__XXX
 SG_ RadioVolume : 44|5@0+ (1,0) [0|31] "" Vector__XXX
 SG_ AMRadioFrequanceValue : 31|16@0+ (1,0) [530|1710] "KHz" Vector__XXX
 SG_ FMRadioFrequanceValue : 15|16@0+ (0.005,0) [87.5|108] "MHz" Vector__XXX
 SG_ RRMOnSts : 7|1@0+ (1,0) [0|1] "" Vector__XXX
 SG_ SourceStationMode : 6|3@0+ (1,0) [0|7] "" Vector__XXX
 SG_ RadioResearchSts : 3|2@0+ (1,0) [0|3] "" Vector__XXX
 SG_ RadioFrequanceMode : 1|2@0+ (1,0) [0|3] "" Vector__XXX

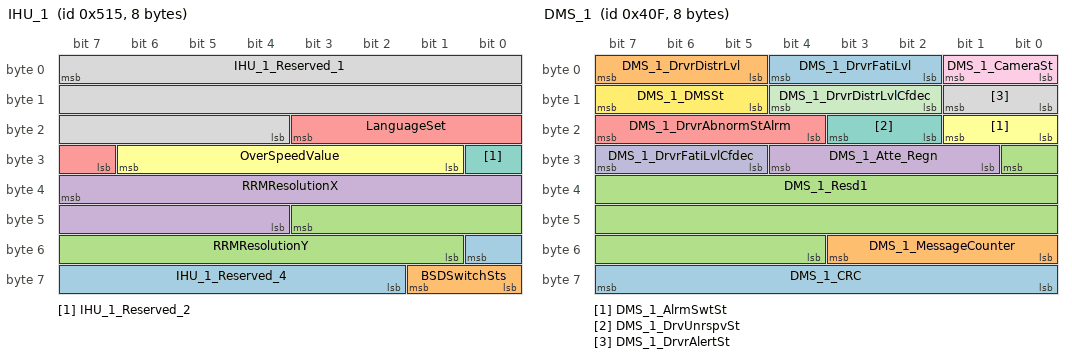
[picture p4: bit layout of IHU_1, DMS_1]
BO_ 1301 IHU_1: 8 IHU
 SG_ IHU_1_Reserved_4 : 48|7@0+ (1,0) [0|0] "" Vector__XXX
 SG_ BSDSwitchSts : 57|2@0+ (1,0) [0|3] "" Vector__XXX
 SG_ RRMResolutionY : 43|11@0+ (1,0) [0|1559] "Pixel" Vector__XXX
 SG_ RRMResolutionX : 39|12@0+ (1,0) [0|2559] "Pixel" Vector__XXX
 SG_ LanguageSet : 19|5@0+ (1,0) [0|31] "" Vector__XXX
 SG_ OverSpeedValue : 30|6@0+ (1,0) [0|63] "" Vector__XXX
 SG_ IHU_1_Reserved_2 : 24|1@0+ (1,0) [0|0] "" Vector__XXX
 SG_ IHU_1_Reserved_1 : 7|20@0+ (1,0) [0|0] "" Vector__XXX

BO_ 1039 DMS_1: 8 IHU
 SG_ DMS_1_CRC : 63|8@0+ (1,0) [0|255] "" Vector__XXX
 SG_ DMS_1_MessageCounter : 51|4@0+ (1,0) [0|15] "" Vector__XXX
 SG_ DMS_1_Resd1 : 24|21@0+ (1,0) [0|0] "" Vector__XXX
 SG_ DMS_1_Atte_Regn : 28|4@0+ (1,0) [0|15] "" Vector__XXX
 SG_ DMS_1_DrvrAbnormStAlrm : 23|4@0+ (1,0) [0|15] "" Vector__XXX
 SG_ DMS_1_AlrmSwtSt : 17|2@0+ (1,0) [0|3] "" Vector__XXX
 SG_ DMS_1_DrvUnrspvSt : 19|2@0+ (1,0) [0|3] "" Vector__XXX
 SG_ DMS_1_DrvrAlertSt : 9|2@0+ (1,0) [0|3] "" Vector__XXX
 SG_ DMS_1_CameraSt : 1|2@0+ (1,0) [0|3] "" Vector__XXX
 SG_ DMS_1_DrvrFatiLvlCfdec : 31|3@0+ (1,0) [0|7] "" Vector__XXX
 SG_ DMS_1_DrvrDistrLvlCfdec : 12|3@0+ (1,0) [0|7] "" Vector__XXX
 SG_ DMS_1_DMSSt : 15|3@0+ (1,0) [0|7] "" Vector__XXX
 SG_ DMS_1_DrvrFatiLvl : 4|3@0+ (1,0) [0|7] "" Vector__XXX
 SG_ DMS_1_DrvrDistrLvl : 7|3@0+ (1,0) [0|7] "" Vector__XXX

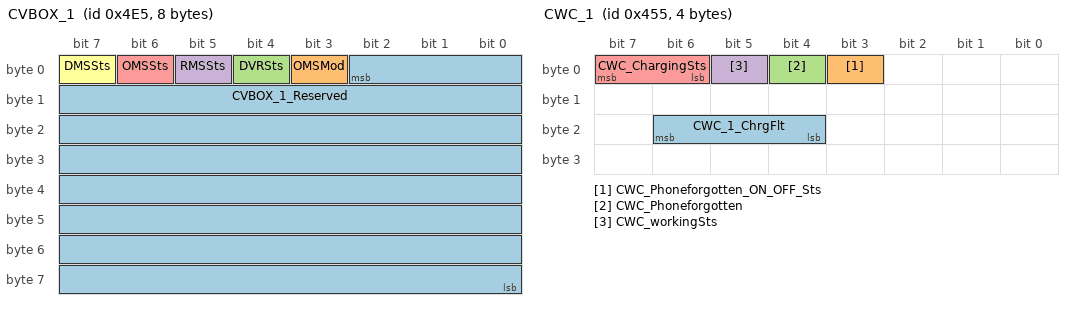
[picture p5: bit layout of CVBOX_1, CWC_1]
BO_ 1253 CVBOX_1: 8 Vector__XXX
 SG_ CVBOX_1_Reserved : 2|59@0+ (1,0) [0|0] ""  IHU
 SG_ OMSMod : 3|1@0+ (1,0) [0|1] ""  IHU
 SG_ DVRSts : 4|1@0+ (1,0) [0|1] ""  IHU
 SG_ RMSSts : 5|1@0+ (1,0) [0|1] ""  IHU
 SG_ OMSSts : 6|1@0+ (1,0) [0|1] ""  IHU
 SG_ DMSSts : 7|1@0+ (1,0) [0|1] ""  IHU

BO_ 1109 CWC_1: 4 Vector__XXX
 SG_ CWC_1_ChrgFlt : 22|3@0+ (1,0) [0|7] ""  IHU
 SG_ CWC_Phoneforgotten_ON_OFF_Sts : 3|1@0+ (1,0) [0|1] ""  IHU
 SG_ CWC_Phoneforgotten : 4|1@0+ (1,0) [0|1] ""  IHU
 SG_ CWC_workingSts : 5|1@0+ (1,0) [0|1] ""  IHU
 SG_ CWC_ChargingSts : 7|2@0+ (1,0) [0|3] ""  IHU

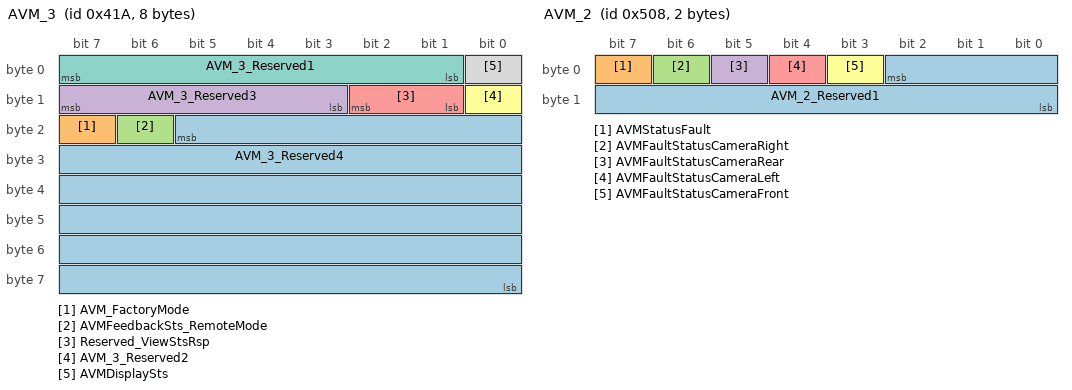
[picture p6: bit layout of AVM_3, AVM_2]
BO_ 1050 AVM_3: 8 IHU
 SG_ AVM_3_Reserved4 : 21|46@0+ (1,0) [0|0] "" Vector__XXX
 SG_ AVM_FactoryMode : 23|1@0+ (1,0) [0|1] "" Vector__XXX
 SG_ AVMFeedbackSts_RemoteMode : 22|1@0+ (1,0) [0|1] "" Vector__XXX
 SG_ AVM_3_Reserved3 : 15|5@0+ (1,0) [0|0] "" Vector__XXX
 SG_ Reserved_ViewStsRsp : 10|2@0+ (1,0) [0|3] "" Vector__XXX
 SG_ AVM_3_Reserved2 : 8|1@0+ (1,0) [0|0] "" Vector__XXX
 SG_ AVM_3_Reserved1 : 7|7@0+ (1,0) [0|0] "" Vector__XXX
 SG_ AVMDisplaySts : 0|1@0+ (1,0) [0|1] "" Vector__XXX

BO_ 1288 AVM_2: 2 IHU
 SG_ AVM_2_Reserved1 : 2|11@0+ (1,0) [0|0] "" Vector__XXX
 SG_ AVMStatusFault : 7|1@0+ (1,0) [0|1] "" Vector__XXX
 SG_ AVMFaultStatusCameraRight : 6|1@0+ (1,0) [0|1] "" Vector__XXX
 SG_ AVMFaultStatusCameraRear : 5|1@0+ (1,0) [0|1] "" Vector__XXX
 SG_ AVMFaultStatusCameraLeft : 4|1@0+ (1,0) [0|1] "" Vector__XXX
 SG_ AVMFaultStatusCameraFront : 3|1@0+ (1,0) [0|1] "" Vector__XXX

CM_ SG_ 1177 IHU_26_RRWinCmd "???????????У????、????????";
CM_ SG_ 1177 IHU_26_WiprSnvty "WiperSensitivity????????";
CM_ SG_ 1177 IHU_26_SeatLegSpprtPosnCmd "Seat leg support position command";
CM_ SG_ 1177 IHU_26_RLWinCmd "???????????У????、????????";
CM_ SG_ 1177 IHU_26_FRWinCmd "???????????У????、??????????";
CM_ SG_ 1177 IHU_26_FLWinCmd "???????????У????、??????????";
CM_ SG_ 1177 IHU_26_CenterLockSwt "CenterLock?п???????";
CM_ SG_ 1177 IHU_26_SeatLvlPosnCmd "Seat level position command";
CM_ SG_ 1177 IHU_26_SeatHdrestHeiAdjmtCmd "Seat headrest height adjustment command";
CM_ SG_ 1177 IHU_26_WinInhbSwt "Window Inhibit ???????????";
CM_ SG_ 1177 IHU_26_ReWinDefrstSwt "Rear window defrost??細????";
CM_ SG_ 1177 IHU_26_SteerWhlHeatgSwt "Steering Wheel heating?????????";
CM_ SG_ 1177 IHU_26_BackrAgPosnCmd "Seat back angle position command";
CM_ SG_ 1177 IHU_26_SeatCushPosnCmd "Seat cushion position command";
CM_ SG_ 1177 IHU_26_SeatHeiPosnCmd "Seat height position command";
CM_ SG_ 643 IHU_25_AmbLigFlngModSel "Ambient Lighting_Flowing_mode_select";
CM_ SG_ 643 IHU_25_AmbLig14FlngEna "Ambient Lighting14_Flowing_ENABLE";
CM_ SG_ 643 IHU_25_AmbLig13FlngEna "Ambient Lighting13_Flowing_ENABLE";
CM_ SG_ 643 IHU_25_AmbLig12FlngEna "Ambient Lighting12_Flowing_ENABLE";
CM_ SG_ 643 IHU_25_AmbLigFadeINOUTStepTi "Ambient Lighting_FADE_IN/OUT_STEP_TIME
T on = IHU_25_AmbLigFadeIN/OUTStepTi*50ms";
CM_ SG_ 643 IHU_25_AmbLig14FadeEna "Ambient Lighting14_FADE_ENABLE";
CM_ SG_ 643 IHU_25_AmbLig13FadeEna "Ambient Lighting13_FADE_ENABLE";
CM_ SG_ 643 IHU_25_AmbLig12FadeEna "Ambient Lighting12_FADE_ENABLE";
CM_ SG_ 643 IHU_25_AmbLig11FadeEna "Ambient Lighting11_FADE_ENABLE";
CM_ SG_ 643 IHU_25_AmbLig10FadeEna "Ambient Lighting10_FADE_ENABLE";
CM_ SG_ 643 IHU_25_AmbLig09FadeEna "Ambient Lighting9_FADE_ENABLE";
CM_ SG_ 643 IHU_25_AmbLig08FadeEna "Ambient Lighting8_FADE_ENABLE";
CM_ SG_ 643 IHU_25_AmbLig07FadeEna "Ambient Lighting7_FADE_ENABLE";
CM_ SG_ 643 IHU_25_AmbLig06FadeEna "Ambient Lighting6_FADE_ENABLE";
CM_ SG_ 643 IHU_25_AmbLig05FadeEna "Ambient Lighting5_FADE_ENABLE";
CM_ SG_ 643 IHU_25_AmbLig04FadeEna "Ambient Lighting4_FADE_ENABLE";
CM_ SG_ 643 IHU_25_AmbLig03FadeEna "Ambient Lighting3_FADE_ENABLE";
CM_ SG_ 643 IHU_25_AmbLig02FadeEna "Ambient Lighting2_FADE_ENABLE";
CM_ SG_ 643 IHU_25_AmbLig01FadeEna "Ambient Lighting1_FADE_ENABLE";
CM_ SG_ 643 IHU_25_AmbLigColorAdj "Ambient Lighting_Color_ADJUST";
CM_ SG_ 643 IHU_25_AmbLigBriAdj "Ambient Lighting_Brightness_ADJUST";
CM_ SG_ 643 IHU_25_AmbLig14Authn "Ambient Lighting14_Authorization";
CM_ SG_ 643 IHU_25_AmbLig13Authn "Ambient Lighting13_Authorization";
CM_ SG_ 643 IHU_25_AmbLig12Authn "Ambient Lighting12_Authorization";
CM_ SG_ 643 IHU_25_AmbLig11Authn "Ambient Lighting11_Authorization";
CM_ SG_ 643 IHU_25_AmbLig10Authn "Ambient Lighting10_Authorization";
CM_ SG_ 643 IHU_25_AmbLig09Authn "Ambient Lighting09_Authorization";
CM_ SG_ 643 IHU_25_AmbLig08Authn "Ambient Lighting08_Authorization";
CM_ SG_ 643 IHU_25_AmbLig07Authn "Ambient Lighting07_Authorization";
CM_ SG_ 643 IHU_25_AmbLig06Authn "Ambient Lighting06_Authorization";
CM_ SG_ 643 IHU_25_AmbLig05Authn "Ambient Lighting05_Authorization";
CM_ SG_ 643 IHU_25_AmbLig04Authn "Ambient Lighting04_Authorization";
CM_ SG_ 643 IHU_25_AmbLig03Authn "Ambient Lighting03_Authorization";
CM_ SG_ 643 IHU_25_AmbLig02Authn "Ambient Lighting02_Authorization";
CM_ SG_ 643 IHU_25_AmbLig01Authn "Ambient Lighting01_Authorization";
CM_ BO_ 1244 "????DVD?????????????????????Σ????????????????????Not Active.";
CM_ SG_ 1244 IHU_24_SetAdasDisp "Set_ADASDisplay";
CM_ SG_ 1244 IHU_24_SetBlueToothDisp "Set_BluetoothDisplay";
CM_ SG_ 1244 IHU_24_SetFaceIdOnoff "Set_FaceIDOnOFF";
CM_ SG_ 1244 IHU_24_SetAdasDispPoision "Set_ADASDisplayPoision";
CM_ SG_ 1244 IHU_24_SetNavDisp "Set_NavigationDisplay";
CM_ SG_ 1244 IHU_24_SetHudBri "Set_HUDBrightness";
CM_ SG_ 1244 IHU_24_SetHudDispMod "Set_HUDDisplayMode";
CM_ SG_ 1244 IHU_24_SetHudHei "Set_HUDHeight";
CM_ SG_ 1244 IHU_24_SetHudDispOnOff "Set_HUDDisplayOnOff";
CM_ SG_ 1035 IHU_23_CRC "SAE J1850 CRC-8";
CM_ SG_ 1035 IHU_23_MessageCounter "Alivecounter";
CM_ SG_ 1035 IHU_OTAPwrMngt "Power Management";
CM_ SG_ 1035 IHU_OTAHvReq "OTA high voltage power down request";
CM_ SG_ 1035 IHU_OTASts "OTA status";
CM_ SG_ 1278 IHU_22_Reserved1 "IHU_Backrest Angle adjustment";
CM_ SG_ 1278 IHU_SHU1RSeatAutVentnCmd "Passenger Seat Automatic Ventilation Command";
CM_ SG_ 1278 IHU_SHU1LSeatAutVentnCmd "Driver Seat Automatic Ventilation Command";
CM_ SG_ 1278 IHU_SHU1RSeatAutHeatCmd "Passenger Seat Automatic Heat Command";
CM_ SG_ 1278 IHU_SHU1LSeatAutHeatCmd "Driver Seat Automatic Heat Command";
CM_ SG_ 1278 SHU3RSeatVentilationCmd "?????????????????????";
CM_ SG_ 1278 SHU3LSeatVentilationCmd "?????????????????????";
CM_ SG_ 1278 SHU3RSeatHeatLevelCmd "??????????????μ??????";
CM_ SG_ 1278 SHU3LSeatHeatLevelCmd "??????????????μ??????";
CM_ SG_ 1278 SHU2RSeatVentilationCmd "?????????????????????";
CM_ SG_ 1278 SHU2MSeatVentilationCmd "?????????м???????????";
CM_ SG_ 1278 SHU2LSeatVentilationCmd "?????????????????????";
CM_ SG_ 1278 SHU2RSeatHeatLevelCmd "??????????????μ??????";
CM_ SG_ 1278 SHU2MSeatHeatLevelCmd "?????????м????μ??????";
CM_ SG_ 1278 SHU2LSeatHeatLevelCmd "??????????????μ??????";
CM_ SG_ 1278 SHU1RSeatVentilationCmd "????????????????????";
CM_ SG_ 1278 SHU1LSeatVentilationCmd "?????????????????????";
CM_ SG_ 1278 SHU1RSeatHeatLevelCmd "?????????????μ??????";
CM_ SG_ 1278 SHU1LSeatHeatLevelCmd "??????????????μ??????";
CM_ BO_ 1119 "??????????Σ???3?ε???";
CM_ SG_ 1119 IHU_19_Set_HdrestSpkrMod "Set the headrest speaker mode using the host softkey
???????????????????????????????
0x0!mao!??????
0x1: ??????
0x2: ??????
0x3:?????
0x4:???
0x5:???
0x6:???
0x8:???";
CM_ SG_ 1119 IHU_19_Set_AMPESEVol "Volume
????,???31??0-31??";
CM_ SG_ 1119 IHU_19_Set_AMPWelVol "Welcome Volume
??????,???31??0-31??";
CM_ SG_ 1119 IHU_19_Set_AMPBTMediVol "Media Volume
e????????,???31??0-31??";
CM_ SG_ 1119 IHU_19_REQ_AMPA2BMediSound "Type of multimedia playback
??y?岥???????";
CM_ SG_ 1119 IHU_19_PABSetCmd "IHU_19_PAB Set Command";
CM_ SG_ 1119 IHU_19_HwSet "Haptic Warning(HWA) /  ??????????";
CM_ SG_ 1119 IHU_19_BSRBPASet "Belt slack reduction(BSR) / ??????????
Belt parking assist(BPA) / ???????????";
CM_ SG_ 1119 Set_AMPMute "????????????????
????????????lin??????????DVD!dou!DVD???CAN????
????";
CM_ SG_ 1119 Set_AMPSpeedVolume "????????
????????????!mao!???!dun!??!dun!??!dun!??.
?????????????????!dou!??y???????Entertainment???????????????????????????????????????";
CM_ BO_ 1100 "??????????Σ???3?ε???";
CM_ SG_ 1100 Set_AMPAlarmVolume "??????，?????Χ?1~10";
CM_ SG_ 1100 Set_AMPLoudness "???：???????????????y???????Entertainment?????，??????????????????????";
CM_ SG_ 1100 Set_AMPLiveAcoustics "?????Ч?????????
EQ:equalizer";
CM_ SG_ 1100 Set_AMPSoundFieldFader "???????/???????????Y_axis??";
CM_ SG_ 1100 Set_AMPSoundFieldBalance "???????/??????????：???????????????????????X_axis??
?????????Χ?-7~+7";
CM_ SG_ 1100 Set_AMPSoundEffectTreble "??Ч?????????????????????????";
CM_ SG_ 1100 Set_AMPSoundEffectMidrange "??Ч??????????????????????????";
CM_ SG_ 1100 Set_AMPSoundEffectBass "??Ч?????????????????????????'-7~+7，";
CM_ SG_ 1100 Set_AMPSoundEffect "??Ч????
????!mao!?????!dun!???!dun!????!dun!???!dun!???!dun!???!dun!????!dun!???

0x1: Customer-defined mode?????
0x2: Standard mode ?????
0x3: Popular mode ??????
0x4: Jazz mode ?????
0x5: Classic mode ?????
0x6: Rock mode ?????
0x7: Vocals mode??????
0x8: Rural model(?????)";
CM_ SG_ 1100 Set_AMPRestoreDefaults "??????????，????：????、??Ч、?????????????";
CM_ SG_ 1100 Set_AMPDefaultVolume "???????????
0~ 31!dou!
?????y???????Entertainment???????????????????????!dou!
? ????????????????????A?!dou!??????y?????????С??A!dou!?????????????????????????????????????????y?????????????A!dou!??????????????????????A";
CM_ SG_ 1100 Set_AMPSoundFocus "???????
0x1!mao!Customized(???Balance/Fader)
0x2!mao!All(Passenger)
0x3!mao!Driver
0x4!mao!Front
0x5!mao!Rear
0x6!mao!Sleep(Baby Mode)
0x7!mao!VIP(Boss)";
CM_ SG_ 1100 Set_AMPPhoneVolume "?绰????,?????Χ?0~25";
CM_ SG_ 1100 Set_AMPMediaVolume "y????,???31??0-31??";
CM_ SG_ 1100 Set_AMPKeyTone "?????????";
CM_ SG_ 1100 Set_AMPVRVolume "???????????，0~10，
VR!dou!????!mao!С?????!dou!EAMP?????????????";
CM_ SG_ 1100 Set_AMPNaviVolume "??????,0~10";
CM_ BO_ 1065 "????DVD?????????????????????Σ????????????????????Not Active.";
CM_ SG_ 1065 IHU_16_SetReRowPwrKeyCmd "Set RearRowPowerKeyCommand";
CM_ SG_ 1065 IHU_16_SetReRowBlowSpdLvlCmd "Set Rear RowBlow speed level Command";
CM_ SG_ 1065 IHU_16_SetReRowWorkCmd "Set Rear Row Work Command";
CM_ SG_ 1065 IHU_PM2_5AutoRunSet "??????????????????????";
CM_ SG_ 1065 IHU_ANIONSwitch "??????????????????";
CM_ SG_ 1065 IHU_RefreshFunction "?????????????????
???ù?????!dou!?????????????????????????";
CM_ SG_ 1065 IHU_ACModeCustom "??????????
01??????
02??????
03?????
??AIPM!dou!??????????";
CM_ SG_ 1065 IHU_FragranCeconsistenceLevel "????????
??AIPM!dou!??????????";
CM_ SG_ 1065 IHU_FragranceSW "????????????
??AIPM!dou!??????????";
CM_ SG_ 1065 IHU_16_SetSeBlowSpdLvlDisp "SecondBlow speed level display status
?????????λ";
CM_ SG_ 1065 IHU_16_SetSeWorking "Second Working 
?????????";
CM_ SG_ 1065 IHU_16_SeIntelligentCustom "ON:?????????????
OFF!mao!????????????";
CM_ SG_ 1065 IHU_16_SetPtcHeatg "Ptc Heating Status
ON:??????????????
OFF!mao!?????????????";
CM_ SG_ 1065 IHU_FragranceWelcomeMode "????????";
CM_ SG_ 1065 IHU_FragrancePosition "???λ?????";
CM_ SG_ 1065 IHU_AutoBlueCallBlowSpeed "DVD?????????????????????
??AIPM!dou!??????????";
CM_ SG_ 1065 IHU_AutoParkInnerCirculation "DVD??????????????
??AIPM!dou!??????????";
CM_ BO_ 1296 "??GPS??????????????GPS????????????";
CM_ SG_ 1296 CurrentTimeSecond "GPS?????";
CM_ SG_ 1296 CurrentTimeMinute "GPS??????";
CM_ SG_ 1296 CurrentTimeHour "GPS??????";
CM_ SG_ 1296 CurrentTimeDay "GPS??????";
CM_ SG_ 1296 CurrentTimeMonth "GPS????￡?";
CM_ SG_ 1296 CurrentTimeYear "GPS?????";
CM_ SG_ 1336 Weather_Type "????????
0x1!mao!????
0x2!mao!????
0x3!mao!????
0x4!mao!????
0x5!mao!??????
0x6!mao!??????б???
0x7!mao!????
0x8!mao!С??
0x9!mao!????
0xA!mao!????
0xB!mao!??????
0xF!mao!С?
0x10!mao!???
0x11!mao!???
0x12!mao!?????
0x13!mao!????
0x15!mao!????
0x1E!mao!????
0x1F!mao!???
0x21!mao!????";
CM_ SG_ 1336 LPN_Info8 "???????λ???";
CM_ SG_ 1336 LPN_Info7 "????????λ???";
CM_ SG_ 1336 LPN_Info6 "????????λ???";
CM_ SG_ 1336 LPN_Info5 "????????λ???";
CM_ SG_ 1336 LPN_Info4 "????????λ???";
CM_ SG_ 1336 LPN_Info3 "????????λ???";
CM_ SG_ 1336 LPN_Info2 "???????λ???";
CM_ SG_ 1336 LPN_Info1 "???????λ???";
CM_ SG_ 1112 MusicLoudness_6000HZ "The corresponding audio loudness when the sampling point music frequency is 6000HZ
Note:
      1.When DVD don't display music , DVD send this signal value \"0x1F\"
       2.Within a cycle time, If DVD don't acquire this frequency, DVD send this signal value \"0x1F\"";
CM_ SG_ 1112 MusicLoudness_2000HZ "The corresponding audio loudness when the sampling point music frequency is 2000HZ
Note:
      1.When DVD don't display music , DVD send this signal value \"0x1F\"
       2.Within a cycle time, If DVD don't acquire this frequency, DVD send this signal value \"0x1F\"";
CM_ SG_ 1112 MusicLoudness_1500HZ "The corresponding audio loudness when the sampling point music frequency is 1500HZ
Note:
      1.When DVD don't display music , DVD send this signal value \"0x1F\"
       2.Within a cycle time, If DVD don't acquire this frequency, DVD send this signal value \"0x1F\"";
CM_ SG_ 1112 MusicLoudness_1000HZ "The corresponding audio loudness when the sampling point music frequency is 1000HZ
Note:
      1.When DVD don't display music , DVD send this signal value \"0x1F\"
       2.Within a cycle time, If DVD don't acquire this frequency, DVD send this signal value \"0x1F\"";
CM_ SG_ 1112 MusicLoudness_500HZ "The corresponding audio loudness when the sampling point music frequency is 500HZ
Note:
      1.When DVD don't display music , DVD send this signal value \"0x1F\"
       2.Within a cycle time, If DVD don't acquire this frequency, DVD send this signal value \"0x1F\"";
CM_ SG_ 1112 LiShowMod "LightShowMode";
CM_ SG_ 1112 MusicLoudness_250HZ "The corresponding audio loudness when the sampling point music frequency is 250HZ
Note:
      1.When DVD don't display music , DVD send this signal value \"0x1F\"
       2.Within a cycle time, If DVD don't acquire this frequency, DVD send this signal value \"0x1F\"";
CM_ SG_ 1112 DVD_StandbyModeSts "DVD????????????";
CM_ SG_ 1112 MusicLoudness_120HZ "The corresponding audio loudness when the sampling point music frequency is 120HZ
Note:
      1.When DVD don't display music , DVD send this signal value \"0x1F\"
       2.Within a cycle time, If DVD don't acquire this frequency, DVD send this signal value \"0x1F\"";
CM_ BO_ 1114 "???????????????????????Σ????????????????????Not Active.????AVM??";
CM_ SG_ 1114 MusicShowCMD "Music Show Command";
CM_ SG_ 1114 LightShowCmd "Light Show Cmmand";
CM_ SG_ 1114 DVRSnapshot "DVRSnapshot";
CM_ SG_ 1114 AVMSwt "AVMSwitch";
CM_ SG_ 1114 TouchEvt "??????
Not active!mao!??DVDδ???д????????????????
?????????·?1??01??00???????????2??????????????10?????????????1??11??00??";
CM_ SG_ 1114 LDWSensitivitySetting "LDW?????????
??????????!dou!???????????????not active";
CM_ SG_ 1114 IHU_APAKeySts "APA?????????";
CM_ SG_ 1114 LDWSwitchSts "LDW?????????
On!mao!??
Off!mao!???
??????????!dou!???????????????not active";
CM_ SG_ 1114 IHU_12_DMSSwtSet "DMS switch set";
CM_ SG_ 1114 IHU_12_CarMdlSetColor "Car Model Set Color";
CM_ SG_ 1114 CalibrationReq "???????????
???????????1-Active!dou!
??????????!dou!???????????????not active";
CM_ SG_ 1114 RRMDisplayAVMOff "IHU????AVM??????
????????????1-Active!dou!
??????????!dou!???????????????not active";
CM_ SG_ 1114 NaviBtnPressInputValueY "????Y??
Not active!mao!??IHUδ?????κ???????????????????????!dou!???????????????????";
CM_ SG_ 1114 NaviBtnPressInputValueX "????X??
Not active!mao!??IHUδ?????κ???????????????????????!dou!???????????????????";
CM_ SG_ 1276 IHU_11_ASUAssocWithDrvrModSet "???DVD????ASU?????????,??????????????????
0x0!mao!??????
0x1!mao!????????????
0x2!mao!???????????";
CM_ SG_ 1276 DVD_SET_EPS_AssociWithDriverMode "???DVD????EPS?????????
0x0!mao!??????
0x1!mao!????????????
0x2!mao!???????????";
CM_ SG_ 1276 IHU_11_ELKSwtSet "ELK switch set";
CM_ SG_ 1276 IHU_11_LDWLDPSnvtySet "LDWLDP Senstitivity set";
CM_ SG_ 1276 IHU_11_LDPSwtSet "LDP switch set";
CM_ SG_ 1276 IHU_11_WarnModSwtSet "warning mode switch set";
CM_ SG_ 1276 IHU_11_LDWSwtSet "LDW switch set";
CM_ SG_ 1276 IHU_11_TLISwtSet "TLI  switch set";
CM_ SG_ 1276 IHU_11_TSISwtSet "TSI  switch set";
CM_ SG_ 1276 IHU_11_HMASwtSet "HMA switch set";
CM_ SG_ 1276 IHU_11_IESSwtSet "IES switch set";
CM_ SG_ 1276 IHU_11_DAISwtSet "DAI switch set";
CM_ SG_ 1276 IHU_11_SCFSwtSet "SCF switch set";
CM_ SG_ 1276 IHU_11_SLASwtSet "SLA switch set";
CM_ SG_ 1276 IHU_11_TJAICAExitTextInfoSwtSet "TJAICA Exit Text Information switch set";
CM_ SG_ 1276 IHU_11_FCWSwtSet "FCW switch set";
CM_ SG_ 1276 IHU_11_FCWSnvtySet "FCW_Sensitivity_Set";
CM_ SG_ 1276 IHU_11_AEBSwtSet "AEB switch set";
CM_ SG_ 1276 IHU_11_RCTBSwtSet "RCTB switch set";
CM_ SG_ 1276 IHU_11_RAEBSwtSet "RAEB switch set";
CM_ SG_ 1276 IHU_11_BSDSwitchSts "???DVD????BSD???????";
CM_ SG_ 1276 DVD_SET_RCW "???DVD????RCW???????";
CM_ SG_ 1276 DVD_SET_CWC_PhoneforgottenFunSts "???DVD???????????????????????????????????
0x0!mao!??????
0x1: ????????????????
0x2: ???????????????
0x3!mao!??Ч
CWC???DVD??0x0!dun!0x3?????CWC??????????????????????";
CM_ SG_ 1276 DVD_SET_ModeKeyFunctionType "DVD????Mode????????????
0x0!mao!?????????
0x1: ????л?
0x2: ??????";
CM_ SG_ 1276 DVD_SET_CWC_WorkingSts "???DVD???????????????????????
0x0!mao!??????
0x1: ???????????
0x2: ??????????
0x3!mao!??Ч
CWC???DVD??0x0!dun!0x3?????CWC?????????";
CM_ SG_ 1335 LightShowMod "Light Show Mode";
CM_ SG_ 1335 Reserved_IHU_10_TrackMod "????T19C?????????????????????";
CM_ SG_ 1335 IHU_10_MirrorSet "????????????????
Steering wheel switches adjust the rearview mirror";
CM_ SG_ 1335 IHU_10_ISSFctCmd "Idle start stop shielding switch";
CM_ SG_ 1335 Set_HUDSteerpan "Set_HUDSteeringpanel";
CM_ SG_ 1335 NavSpeedLimitUnits "NavSpeedLimitUnits";
CM_ SG_ 1335 NavSpeedLimit "NavSpeedLimit";
CM_ SG_ 1335 NavSpeedLimitStatus "NavSpeedLimitStatus
0x0\"SL_UNKNOWN\";??????????
0x1\"SL_EXISTS\";??????
0x2\"SL_NOLIMIT\";??????
0x3\"SL_PLURAL\".?????";
CM_ SG_ 1273 IHU_SET_AIPMBrightnessLevel "IHU?????????????????";
CM_ SG_ 1273 DrvrDoorUnlckOnlyStsSet "???????????????????";
CM_ SG_ 1273 BlowSpeedLevelKeySts "??IHU?????????????????????
?綯IPM??!dou!???IPM????";
CM_ SG_ 1273 IHU_SetTheaterDimmingColor_64 "64???Χ?????????";
CM_ SG_ 1273 IHU_DriverSeatHeatLevelCmd "???????????μ??????
???!mao!????????!dou!?????0x4FE?е??????";
CM_ SG_ 1273 DVD_SET_BLTKey_PESts "???：????????????PE????ON/OFF??
0x0!mao!??????
0x1!mao!PE?????
0x2!mao!PE??????";
CM_ SG_ 1273 FaceID "????ID";
CM_ SG_ 1273 Delete_ID_Info "??????ID?μ???????????";
CM_ SG_ 1273 IHU_DriverSeatVentilationKeySts "??????????????????
???!mao!????????!dou!?????0x4FE?е??????";
CM_ SG_ 1273 DVD_SET_HeadlampHeightSts "???????????????";
CM_ SG_ 1273 Reserved_SASSwitchStatus "MSA??ISA???IHU???????";
CM_ SG_ 1273 Reserved_DVD_SET_RemoteTrunkOnly "???y?????????????????";
CM_ SG_ 1273 Reserved_DVD_SET_UrgeBrakemode "???y????????????????????";
CM_ SG_ 1273 Reserved_DVD_SET_AidTurnIlumin "Reserved_DVD_SET_AidTurnIluminate";
CM_ SG_ 1273 DVD_SET_DRLModeSts "????г????????";
CM_ SG_ 1273 DVD_SET_HeadlampDelayLightSts "?????????????????????????????????，???????";
CM_ SG_ 1273 DVD_SET_RemoteLockFeedback "?????????";
CM_ SG_ 1273 IHU_ISS_Switch "???????，???????????????????Not Active.";
CM_ SG_ 1273 DVD_SET_AutolockSts "?????????????";
CM_ SG_ 1273 Reserved_DVD_SET_AutoUnlockSts "?????????????";
CM_ BO_ 1272 "???????????????????????Σ????????????????????Not Active.";
CM_ SG_ 1272 DVD_Set_FGHeatSts "????????????";
CM_ SG_ 1272 IHU_WindowCmd "?????????????：
1!dun!?????????????!dun!???????!dun!?????!dun!?????!dun!??????!dun!???????!dun!????????????????
2!dun!???open??????!dun!close??????!dun!comfort????磩??????????!dou!?????????????????????comfort??䶮
3!dun!??д????!dou!?????????????????????!dou!????????Not active????";
CM_ SG_ 1272 Set_Default "????????
0x1:???????????????????
0x2!mao!????????й???
0x3!mao!?????HUD????";
CM_ SG_ 1272 Seat_ExtMirror_PosStoreReq_ID "????/??????λ??洢Request ID";
CM_ SG_ 1272 Seat_ExtMirror_PosRecall_ID "????/??????λ????Recall ID";
CM_ SG_ 1272 DVD_Set_ReverseExtMirrorSts "DVD??????????????·????????";
CM_ SG_ 1272 DVD_Set_EasyEntrySts "DVD????EasyEntry???????";
CM_ SG_ 1272 DVD_SetSCURelateKeyOrFaceID "DVD???????μ??书???????????ID??????
1.??????????????!mao!??????DVD???????μ??书??????????????
2.????????????????!mao!??????DVD???????μ??书???????????ID??";
CM_ SG_ 1272 DVD_SetAssociatedWithMusicMode "DVD Set Theater Dimming ON (Associated With Music Mode)";
CM_ SG_ 1272 DVD_SetAssociatedWithDriverMode "DVD Set Theater Dimming ON (Associated With Driver Mode)";
CM_ SG_ 1272 DVD_SetTheaterDimmingBrightness "DVD Set Theater Dimming Brightness";
CM_ SG_ 1272 SetTheaterDimmingColor "DVD Set Theater Dimming Color";
CM_ SG_ 1272 DVD_SetTheaterDimmingStatus "DVD Set Theater Dimming Status";
CM_ SG_ 1272 Set_WelLightPolling "?????????";
CM_ SG_ 1272 Set_PEPS_IntelligentOpen "????PEPS???????β??";
CM_ SG_ 1272 Set_PEPS_Polling "?????????????????";
CM_ SG_ 1272 IHU_PSRFCmd "????????????，??????綯??
?????????!dou!IHU??BCM??????忪??????????IHU_PSRFCmd(0/10%/20%....100%)??!dou! BCM???LIN??????????????!dou!?????????????ж??????????????????!dou!??????????????С?
NotActive!mao!??????
StartUp!mao!??????";
CM_ SG_ 1272 IHU_SRFCmd "??????????、?綯??
???????????????ON????IHU???????!dou!??????????????????????!dou!
??IHU????????????????!dou!IHU??BCM???????IHU_SRFCmd(open/close/tilt) ??
Open!mao!?????close!mao!????tilt!mao!?????
NotActive!mao!??????
StartUp!mao!??????";
CM_ SG_ 1309 LDW_LKA_SensitivityReq "LDW?????，????Needed for different operation modes for LDW and LKA functions, e.g. early and late";
CM_ SG_ 1309 IHU_7_DrvAssiStyle "DriveAsistStyle??????????????";
CM_ SG_ 1309 IHU_7_DCLCONOFF "Paddle controlled lane change?????????";
CM_ SG_ 1309 HMAOnOffReq "DVD???????HMA funtion switch signal";
CM_ SG_ 1309 IHU_AutHldSet "automatic hold set";
CM_ SG_ 1309 SCF_ON_OFF "SCF??????(For FRM FCM)

SCF??????????";
CM_ SG_ 1309 TIHU_SetHDCOnOff "???DVD????HDC???????";
CM_ SG_ 1309 IHU_AssociateDriveModeSet "???DVD????IPB?????????
0x0!mao!??????
0x1!mao!???????????
0x2!mao!????????????";
CM_ SG_ 1309 Set_CSTFunctionSts "CST:Comfortable stop
To switch on or off CST function.";
CM_ SG_ 1309 DistanceWarning_on_off "??????，??FCM?????";
CM_ SG_ 1309 AEB_ON_OFF "To switch on or off AEB braking function.";
CM_ SG_ 1309 FCW_OPTION "far/standard/near";
CM_ SG_ 1309 FCW_ON_OFF "To switch on or off AEB warning function.";
CM_ SG_ 1309 TimeGapSet1Req "????趨";
CM_ BO_ 1074 "????AVM??";
CM_ SG_ 1074 IHU_6_TouchEvt "??????
Not active!mao!??DVDδ???д????????????????
?????????·?1??01??00???????????2??????????????10?????????????1??11??00??";
CM_ SG_ 1074 IHU_6_TrajectorySetting "??????????????
Not active!mao!??IHU???????????????????????";
CM_ SG_ 1074 IHU_6_LDWSwitchSts "LDW?????????
Not active!mao!??IHU???????????????????????
On!mao!??
Off!mao!???";
CM_ SG_ 1074 IHU_6_AVM3DAroundViewSW "AVM3D????Ч??????
Not active!mao!??IHU???????????????????????
On!mao!??Ч??
Off!mao!???Ч??";
CM_ SG_ 1074 IHU_6_SideViewSW "???????AVM??????????
Not active!mao!??IHU??????????????????????? 
On!mao!?????
Off!mao!??????";
CM_ SG_ 1074 IHU_6_CalibrationReq "???????????
?????????0-Not Active;
???????????1-Active!dou!???δ???????0-Not Active;";
CM_ SG_ 1074 IHU_6_RRMDisplayAVMOff "HU????AVM??????
?????????0-Not Active;
????????????1-Active!dou!???δ???????0-Not Active;";
CM_ SG_ 1074 IHU_6_NaviBtnPressInputValueY "????Y??
Not active!mao!??IHUδ?????κ???????????????????????!dou!???????????????????";
CM_ SG_ 1074 IHU_6_NaviBtnPressInputValueX "????X??
Not active!mao!??IHUδ?????κ???????????????????????!dou!???????????????????";
CM_ BO_ 1305 "????DVD?????????????????????Σ????????????????????Not Active.";
CM_ SG_ 1305 AUTODefrostOnKeySts "?????????????????";
CM_ SG_ 1305 PM2_5DisplayReq "1.????IHU????????????? ?，IHU??????????????????? ?????????IHU ?，IHU ???dvd ?????????????л?，????????????С?IHU ?????CLM ??PM2.5Displaysts=1 ???，?????IHU ????，IHU ?????????10 ?????θ?CLM/IPM，CLM/IPM ?????，??PM2.5Displayst ??0，IHU ?????，?л??????????IHU???档
2.IHU ??????·?С????е?????????С????!dou!???????01 ?????θ?CLM/IPM!dou!???????IHU ??п???????????????";
CM_ SG_ 1305 DVD_SET_PM2_5Sts "PM2.5?????";
CM_ SG_ 1305 BlowDelayOffKeySts "Not active：??в???
On!mao!??????????????
Off!mao!???????????????";
CM_ SG_ 1305 BlowAdvanceOnKeySts "Not active：??в???
On!mao!???????????????
Off!mao!????????????????";
CM_ SG_ 1305 ElecClimateSetTemp "?綯??????????
???!mao! ??16?????
??????????????????????
?綯IPM??!dou!???IPM????";
CM_ SG_ 1305 SetTemperature_R_F "??IHU????????????????????
?綯???????????????????";
CM_ SG_ 1305 SetTemperature_L_F "??IHU????????????????????
?綯???????????????????";
CM_ SG_ 1305 DVD_ZoneSelectionKeySts "DVD???????????л?";
CM_ SG_ 1305 DVD_SetCirculationModeKeySts "DVD????????????л?";
CM_ SG_ 1305 SetTemperature_R_C "?????????，????????????????趨?????????????趨???????????，??????趨???????，??????趨????????
IHUδ????趨????!dou!???????趨????startup ??default?????1F?!dou!IHU???????????????????????
??IHU?????????????????????                                                                                                                                                         
?綯???????????????????";
CM_ SG_ 1305 SetTemperature_L_C "?????????，????????????????趨?????????????趨???????????，??????趨???????，??????趨????????
IHUδ????趨????!dou!???????趨????startup ??default?????1F?!dou!IHU???????????????????????
??IHU?????????????????????                                                                                                                                                         
?綯???????????????????";
CM_ SG_ 1305 ModeAdjustKeySts "??IHU?????????????????????
?綯IPM??!dou!???IPM????";
CM_ SG_ 1305 Reserved_DVD_SetAC_MaxKeySts "DVD???????AC MAX";
CM_ SG_ 1305 DVD_SetMaxFrontDeforestSts "DVD???????????????";
CM_ SG_ 1305 BlowSpeedLevelKeySts "??IHU?????????????????????
?綯IPM??!dou!???IPM????
???!mao!????????!dou!?????0x4F9?е??????";
CM_ SG_ 1305 DVD_SetAutoKeySts "DVD??????????????";
CM_ SG_ 1305 DVD_SetACRequestKeySts "DVD????AC??????";
CM_ SG_ 1305 DVD_SetCLMOn "DVD??????????";
CM_ SG_ 1305 IHU_4_CVBOXRstReq "CVBOX?Reset?Request";
CM_ BO_ 1303 "??????????????????????????
1.??DVD????????????????????????????????????????
2.?????????????￡?????????500ms??100ms????????????????????????????????????????
3.???????DVD??????????????????????????Σ??????????????500ms????????????????????????????????????
????????繤?????ж??????????GPS?????????????????GPS??????????????????????GPS????????????Ч????????????????Ч???????????RRM/IHU_3????GPS????????????????????????????á????????RRM/IHU_3??";
CM_ SG_ 1303 DVD_SetThemeType "DVD????ICM?????????DVD??????????????????";
CM_ SG_ 1303 IHU_LDWLKA_LaneAssitTypeReq "LDW/LKA??????";
CM_ SG_ 1303 TimeSetYear "?????????????";
CM_ SG_ 1303 TimeSetMonth "????????????￡?";
CM_ SG_ 1303 TimeSetDay "??????????????";
CM_ SG_ 1303 DVD_Set_PLGPositionSts "????β?????λ??";
CM_ SG_ 1303 DVD_TrunkCmd "???????綯????????";
CM_ SG_ 1303 TimeSetSecond "??????????(??";
CM_ SG_ 1303 IHU_SET_ICMBrightnessLevel "IHU???????????????";
CM_ SG_ 1303 FatigureDrivingTime "IHU???????????????ICM??ICM???????/???????????";
CM_ SG_ 1303 TimeSetMinute "????????????????";
CM_ SG_ 1303 TimeSetHour "???????????С???";
CM_ SG_ 1302 ClimateDisplayReq "1.????CLM/IPM?，IHU???CLM/IPM?????????IHU?，IHU???IHU?????????????л?，????????????С?
IHU?????CLM/IPM????DisplayActive=1???!dou!?????IHU????!dou!IHU?????????10?????θ?CLM/IPM?????η????00??!dou!CLM/IPM?????!dou!??DisplayActive??0!dou!IHU?????!dou!?л??????????IHU???档
2. IHU??????·?С????е?????????!dou!???????01?????θ?CLM/IPM?????η????00??!dou!???????IHU??п??????????
?綯IPM??!dou!???IPM????";
CM_ SG_ 1302 CarAngle "0x0:????????
0x1~0x168!mao!?????????????!dou!???????????
0x1FF:??????????????!dou!???????????";
CM_ SG_ 1302 BltCallSts "???????????????";
CM_ SG_ 1302 PanelKeyVoiceSource "????IPM?????????????????????????";
CM_ SG_ 1302 RadioVolume "???????????
If RRM is off or event of this signal isn??t happen, this signal value shall be 0 (Not active)";
CM_ SG_ 1302 AMRadioFrequanceValue "AM?????????
If RRM is off or event of this signal isn??t happen, this signal value shall be 0x0000 (Not active)
??530kHz-1710kHz?????????й???";
CM_ SG_ 1302 FMRadioFrequanceValue "FM?????????
If RRM is off or event of this signal isn??t happen, this signal value shall be 0x0000 (Not active)";
CM_ SG_ 1302 RRMOnSts "????????????????";
CM_ SG_ 1302 SourceStationMode "?????????
If RRM is off or event of this signal isn??t happen, this signal value shall be 000 (Not active)";
CM_ SG_ 1302 RadioResearchSts "??????
If RRM is off or event of this signal isn??t happen, this signal value shall be 0 (Not active)";
CM_ SG_ 1302 RadioFrequanceMode "????????????
If RRM is off or event of this signal isn??t happen, this signal value shall be 00 (Not active)";
CM_ SG_ 1301 BSDSwitchSts "BSD????
??????δ?????!dou!?????????????!dou!?????????Not Active
1.IGN ON???!dou!?????????μ??BSD?????????
2.????????????????????!dou!??Not Active??
3.Not Active?????????δ???!dou!?????в???!dou!BSD?????????!dou!?????????????";
CM_ SG_ 1301 RRMResolutionY "RRM????????Y??
???????????2560*1600";
CM_ SG_ 1301 RRMResolutionX "RRM????????X??
???????????2560*1600";
CM_ SG_ 1301 LanguageSet "???????????
If IHU is off or event of this signal isn??t happen, this signal value shall be 00000 (Not active)
T1A????!mao!??????????????????!dou!ICM??AVM?????????????!dou!???????κ??????Not active????ICM??????IHU??????!dou!ICM????????????????";
CM_ SG_ 1301 OverSpeedValue "??????????
1. IHU???!dou!??Not active;
2.δ???????!dou!IHU???ú?!dou!??????????????????!dou!?????not active??? ??
3.???????!dou!??Not active??
4.???????????????111111(Cancel)??
5.?????????????!dou!???????Not active??
6.??????????????!dou!???????Open!dou!????????μ???????";
CM_ SG_ 1039 DMS_1_CRC "CRC (SAE J1850 CRC-8)
Note: Details Please refer to specification??EE Standard Specification for CAN  Network Implementation??section 2.3.2";
CM_ SG_ 1039 DMS_1_MessageCounter "Rolling message counter(the maximum value of Alive counter is 15)
Note: Details Please refer to specification??EE Standard Specification for CAN  Network Implementation??section 2.3.1";
CM_ SG_ 1039 DMS_1_Atte_Regn "Driver Attentional Region";
CM_ SG_ 1039 DMS_1_DrvrAbnormStAlrm "Driver Abnormal State Alarm";
CM_ SG_ 1039 DMS_1_AlrmSwtSt "DMS Alarm Switch State";
CM_ SG_ 1039 DMS_1_DrvUnrspvSt "Driver Unresponsive State";
CM_ SG_ 1039 DMS_1_DrvrAlertSt "Driver Alert State";
CM_ SG_ 1039 DMS_1_CameraSt "Camera State";
CM_ SG_ 1039 DMS_1_DrvrFatiLvlCfdec "Confidence of the signal Driver Fatigue Level";
CM_ SG_ 1039 DMS_1_DrvrDistrLvlCfdec "Confidence of the signal Driver Distract Level";
CM_ SG_ 1039 DMS_1_DMSSt "DMS State";
CM_ SG_ 1039 DMS_1_DrvrFatiLvl "Driver Fatigue Level";
CM_ SG_ 1039 DMS_1_DrvrDistrLvl "Driver Distract Level";
CM_ SG_ 1109 CWC_1_ChrgFlt "??????????????
charge fault";
CM_ SG_ 1109 CWC_Phoneforgotten_ON_OFF_Sts "??????????????????
0x0:??????
0x1:?????";
CM_ SG_ 1109 CWC_Phoneforgotten "??????????????????????(DVD???????????????????)
0x0:??????????
0x1:???????????";
CM_ SG_ 1109 CWC_workingSts "??????????????(DVD???????)
0x0: ???????????
0x1: ??????????";
CM_ SG_ 1109 CWC_ChargingSts "?????????????(DVD???????)
0x0: ??г??
0x1: ?????
0x2: ??????
0x3!mao!??????";
CM_ SG_ 1050 AVM_FactoryMode "AVM??????";
CM_ SG_ 1050 AVMFeedbackSts_RemoteMode "???????，AVM??????";
CM_ SG_ 1050 Reserved_ViewStsRsp "?????????????????AVVM????";
CM_ SG_ 1050 AVMDisplaySts "AVM?????????
AVM????δ????!dou!??0!dou!??DVD????????
AVM???????!dou!?????AVM???????????????????R?????????/?????!dou!??1!dou!DVD??????л?????????档";
CM_ SG_ 1288 AVMStatusFault "AVM??????/????";
CM_ SG_ 1288 AVMFaultStatusCameraRight "???????????/????";
CM_ SG_ 1288 AVMFaultStatusCameraRear "???????????/????";
CM_ SG_ 1288 AVMFaultStatusCameraLeft "???????????/????";
CM_ SG_ 1288 AVMFaultStatusCameraFront "??????????/????";
BA_DEF_ SG_  "GenSigTimeoutValue" INT 0 2147483647;
BA_DEF_ SG_  "GenSigStartValue" INT 0 2147483647;
BA_DEF_ SG_  "GenSigInactiveValue" INT 0 2147483647;
BA_DEF_ BO_  "TpTxIndex" INT 0 255;
BA_DEF_ BO_  "DiagUudtResponse" ENUM  "False","True";
BA_DEF_ BO_  "DiagResponse" ENUM  "No","Yes";
BA_DEF_ BO_  "DiagRequest" ENUM  "No","Yes";
BA_DEF_ BO_  "DiagState" ENUM  "No","Yes";
BA_DEF_ BO_  "NmAsrMessage" ENUM  "No","Yes";
BA_DEF_ BO_  "GenMsgFastOnStart" INT 0 65535;
BA_DEF_ BO_  "GenMsgCycleTimeFast" INT 0 65535;
BA_DEF_ BO_  "GenMsgNrOfRepetition" INT 0 65535;
BA_DEF_ BO_  "GenMsgStartDelayTime" INT 0 65535;
BA_DEF_ BO_  "GenMsgCycleTime" INT 0 65535;
BA_DEF_ BO_  "GenMsgDelayTime" INT 0 65535;
BA_DEF_ SG_  "GenSigSendType" ENUM  "Cyclic","OnWrite","OnWriteWithRepetition","OnChange","OnChangeWithRepetition","IfActive","IfActiveWithRepetition","NoSigSendType","OnChangeAndIfActive","OnChangeAndIfActiveWithRepetition";
BA_DEF_ BO_  "GenMsgSendType" ENUM  "Cyclic","NotUsed","NotUsed","NotUsed","NotUsed","NotUsed","NotUsed","IfActive","NoMsgSendType";
BA_DEF_ BO_  "GenMsgILSupport" ENUM  "No","Yes";
BA_DEF_REL_ BU_SG_REL_  "GenSigTimeoutTime" INT 0 65535;
BA_DEF_DEF_  "GenSigTimeoutValue" 0;
BA_DEF_DEF_  "GenSigStartValue" 0;
BA_DEF_DEF_  "GenSigInactiveValue" 0;
BA_DEF_DEF_  "TpTxIndex" 0;
BA_DEF_DEF_  "DiagUudtResponse" "False";
BA_DEF_DEF_  "DiagResponse" "No";
BA_DEF_DEF_  "DiagRequest" "No";
BA_DEF_DEF_  "DiagState" "No";
BA_DEF_DEF_  "NmAsrMessage" "No";
BA_DEF_DEF_  "GenMsgFastOnStart" 0;
BA_DEF_DEF_  "GenMsgCycleTimeFast" 0;
BA_DEF_DEF_  "GenMsgNrOfRepetition" 3;
BA_DEF_DEF_  "GenMsgStartDelayTime" 0;
BA_DEF_DEF_  "GenMsgCycleTime" 0;
BA_DEF_DEF_  "GenMsgDelayTime" 0;
BA_DEF_DEF_  "GenSigSendType" "NoSigSendType";
BA_DEF_DEF_  "GenMsgSendType" "NoMsgSendType";
BA_DEF_DEF_  "GenMsgILSupport" "No";
BA_DEF_DEF_REL_ "GenSigTimeoutTime" 0;
BA_ "GenMsgILSupport" BO_ 1177 1;
BA_ "GenMsgDelayTime" BO_ 1177 5;
BA_ "GenMsgCycleTimeFast" BO_ 1177 100;
BA_ "GenMsgILSupport" BO_ 643 1;
BA_ "GenMsgSendType" BO_ 643 0;
BA_ "GenMsgNrOfRepetition" BO_ 643 0;
BA_ "GenMsgCycleTime" BO_ 643 20;
BA_ "GenMsgILSupport" BO_ 1244 1;
BA_ "GenMsgDelayTime" BO_ 1244 5;
BA_ "GenMsgCycleTimeFast" BO_ 1244 100;
BA_ "GenMsgILSupport" BO_ 1035 1;
BA_ "GenMsgSendType" BO_ 1035 0;
BA_ "GenMsgNrOfRepetition" BO_ 1035 0;
BA_ "GenMsgCycleTime" BO_ 1035 100;
BA_ "GenMsgILSupport" BO_ 1278 1;
BA_ "GenMsgDelayTime" BO_ 1278 5;
BA_ "GenMsgCycleTimeFast" BO_ 1278 100;
BA_ "GenMsgILSupport" BO_ 1119 1;
BA_ "GenMsgDelayTime" BO_ 1119 5;
BA_ "GenMsgCycleTimeFast" BO_ 1119 100;
BA_ "GenMsgILSupport" BO_ 1100 1;
BA_ "GenMsgDelayTime" BO_ 1100 5;
BA_ "GenMsgCycleTimeFast" BO_ 1100 100;
BA_ "GenMsgILSupport" BO_ 1065 1;
BA_ "GenMsgDelayTime" BO_ 1065 5;
BA_ "GenMsgCycleTimeFast" BO_ 1065 100;
BA_ "GenMsgCycleTime" BO_ 1065 10;
BA_ "GenMsgILSupport" BO_ 1296 1;
BA_ "GenMsgSendType" BO_ 1296 0;
BA_ "GenMsgNrOfRepetition" BO_ 1296 0;
BA_ "GenMsgCycleTime" BO_ 1296 500;
BA_ "GenMsgILSupport" BO_ 1336 1;
BA_ "GenMsgSendType" BO_ 1336 0;
BA_ "GenMsgNrOfRepetition" BO_ 1336 0;
BA_ "GenMsgCycleTime" BO_ 1336 500;
BA_ "GenMsgILSupport" BO_ 1112 1;
BA_ "GenMsgSendType" BO_ 1112 0;
BA_ "GenMsgNrOfRepetition" BO_ 1112 0;
BA_ "GenMsgCycleTime" BO_ 1112 100;
BA_ "GenMsgILSupport" BO_ 1114 1;
BA_ "GenMsgDelayTime" BO_ 1114 5;
BA_ "GenMsgCycleTimeFast" BO_ 1114 100;
BA_ "GenMsgILSupport" BO_ 1276 1;
BA_ "GenMsgDelayTime" BO_ 1276 5;
BA_ "GenMsgCycleTimeFast" BO_ 1276 100;
BA_ "GenMsgILSupport" BO_ 1335 1;
BA_ "GenMsgSendType" BO_ 1335 0;
BA_ "GenMsgNrOfRepetition" BO_ 1335 0;
BA_ "GenMsgCycleTime" BO_ 1335 100;
BA_ "GenMsgILSupport" BO_ 1273 1;
BA_ "GenMsgDelayTime" BO_ 1273 5;
BA_ "GenMsgCycleTimeFast" BO_ 1273 100;
BA_ "GenMsgILSupport" BO_ 1272 1;
BA_ "GenMsgDelayTime" BO_ 1272 5;
BA_ "GenMsgCycleTimeFast" BO_ 1272 100;
BA_ "GenMsgILSupport" BO_ 1309 1;
BA_ "GenMsgDelayTime" BO_ 1309 5;
BA_ "GenMsgCycleTimeFast" BO_ 1309 100;
BA_ "GenMsgILSupport" BO_ 1074 1;
BA_ "GenMsgSendType" BO_ 1074 0;
BA_ "GenMsgNrOfRepetition" BO_ 1074 5;
BA_ "GenMsgDelayTime" BO_ 1074 5;
BA_ "GenMsgCycleTimeFast" BO_ 1074 100;
BA_ "GenMsgCycleTime" BO_ 1074 500;
BA_ "GenMsgILSupport" BO_ 1305 1;
BA_ "GenMsgDelayTime" BO_ 1305 5;
BA_ "GenMsgCycleTimeFast" BO_ 1305 100;
BA_ "GenMsgILSupport" BO_ 1303 1;
BA_ "GenMsgNrOfRepetition" BO_ 1303 5;
BA_ "GenMsgDelayTime" BO_ 1303 5;
BA_ "GenMsgCycleTimeFast" BO_ 1303 100;
BA_ "GenMsgILSupport" BO_ 1302 1;
BA_ "GenMsgSendType" BO_ 1302 0;
BA_ "GenMsgNrOfRepetition" BO_ 1302 0;
BA_ "GenMsgCycleTime" BO_ 1302 500;
BA_ "GenMsgILSupport" BO_ 1301 1;
BA_ "GenMsgSendType" BO_ 1301 0;
BA_ "GenMsgDelayTime" BO_ 1301 5;
BA_ "GenMsgCycleTimeFast" BO_ 1301 100;
BA_ "GenMsgCycleTime" BO_ 1301 500;
BA_ "GenMsgILSupport" BO_ 1039 1;
BA_ "GenMsgSendType" BO_ 1039 0;
BA_ "GenMsgNrOfRepetition" BO_ 1039 0;
BA_ "GenMsgCycleTime" BO_ 1039 100;
BA_ "GenMsgILSupport" BO_ 1253 1;
BA_ "GenMsgSendType" BO_ 1253 0;
BA_ "GenMsgNrOfRepetition" BO_ 1253 0;
BA_ "GenMsgCycleTime" BO_ 1253 100;
BA_ "GenMsgILSupport" BO_ 1109 1;
BA_ "GenMsgSendType" BO_ 1109 0;
BA_ "GenMsgNrOfRepetition" BO_ 1109 0;
BA_ "GenMsgCycleTime" BO_ 1109 100;
BA_ "GenMsgILSupport" BO_ 1050 1;
BA_ "GenMsgSendType" BO_ 1050 0;
BA_ "GenMsgNrOfRepetition" BO_ 1050 0;
BA_ "GenMsgCycleTime" BO_ 1050 100;
BA_ "GenMsgILSupport" BO_ 1288 1;
BA_ "GenMsgSendType" BO_ 1288 0;
BA_ "GenMsgNrOfRepetition" BO_ 1288 0;
BA_ "GenMsgCycleTime" BO_ 1288 500;
BA_ "GenSigSendType" SG_ 1177 IHU_26_RRWinCmd 2;
BA_ "GenSigSendType" SG_ 1177 IHU_26_WiprSnvty 2;
BA_ "GenSigSendType" SG_ 1177 IHU_26_SeatLegSpprtPosnCmd 2;
BA_ "GenSigSendType" SG_ 1177 IHU_26_RLWinCmd 2;
BA_ "GenSigSendType" SG_ 1177 IHU_26_FRWinCmd 2;
BA_ "GenSigSendType" SG_ 1177 IHU_26_FLWinCmd 2;
BA_ "GenSigSendType" SG_ 1177 IHU_26_CenterLockSwt 2;
BA_ "GenSigSendType" SG_ 1177 IHU_26_SeatLvlPosnCmd 2;
BA_ "GenSigSendType" SG_ 1177 IHU_26_SeatHdrestHeiAdjmtCmd 2;
BA_ "GenSigSendType" SG_ 1177 IHU_26_WinInhbSwt 2;
BA_ "GenSigSendType" SG_ 1177 IHU_26_ReWinDefrstSwt 2;
BA_ "GenSigSendType" SG_ 1177 IHU_26_SteerWhlHeatgSwt 2;
BA_ "GenSigSendType" SG_ 1177 IHU_26_BackrAgPosnCmd 2;
BA_ "GenSigSendType" SG_ 1177 IHU_26_SeatCushPosnCmd 2;
BA_ "GenSigSendType" SG_ 1177 IHU_26_SeatHeiPosnCmd 2;
BA_ "GenSigSendType" SG_ 643 IHU_25_APPsts 0;
BA_ "GenSigSendType" SG_ 643 IHU_25_AmbLigFlngModSel 0;
BA_ "GenSigSendType" SG_ 643 IHU_25_AmbLig14FlngEna 0;
BA_ "GenSigSendType" SG_ 643 IHU_25_AmbLig13FlngEna 0;
BA_ "GenSigSendType" SG_ 643 IHU_25_AmbLig12FlngEna 0;
BA_ "GenSigSendType" SG_ 643 IHU_25_AmbLigFadeINOUTStepTi 0;
BA_ "GenSigSendType" SG_ 643 IHU_25_AmbLig14FadeEna 0;
BA_ "GenSigSendType" SG_ 643 IHU_25_AmbLig13FadeEna 0;
BA_ "GenSigSendType" SG_ 643 IHU_25_AmbLig12FadeEna 0;
BA_ "GenSigSendType" SG_ 643 IHU_25_AmbLig11FadeEna 0;
BA_ "GenSigSendType" SG_ 643 IHU_25_AmbLig10FadeEna 0;
BA_ "GenSigSendType" SG_ 643 IHU_25_AmbLig09FadeEna 0;
BA_ "GenSigSendType" SG_ 643 IHU_25_AmbLig08FadeEna 0;
BA_ "GenSigSendType" SG_ 643 IHU_25_AmbLig07FadeEna 0;
BA_ "GenSigSendType" SG_ 643 IHU_25_AmbLig06FadeEna 0;
BA_ "GenSigSendType" SG_ 643 IHU_25_AmbLig05FadeEna 0;
BA_ "GenSigSendType" SG_ 643 IHU_25_AmbLig04FadeEna 0;
BA_ "GenSigSendType" SG_ 643 IHU_25_AmbLig03FadeEna 0;
BA_ "GenSigSendType" SG_ 643 IHU_25_AmbLig02FadeEna 0;
BA_ "GenSigSendType" SG_ 643 IHU_25_AmbLig01FadeEna 0;
BA_ "GenSigSendType" SG_ 643 IHU_25_AmbLigColorAdj 0;
BA_ "GenSigSendType" SG_ 643 IHU_25_AmbLigBriAdj 0;
BA_ "GenSigSendType" SG_ 643 IHU_25_AmbLig14Authn 0;
BA_ "GenSigSendType" SG_ 643 IHU_25_AmbLig13Authn 0;
BA_ "GenSigSendType" SG_ 643 IHU_25_AmbLig12Authn 0;
BA_ "GenSigSendType" SG_ 643 IHU_25_AmbLig11Authn 0;
BA_ "GenSigSendType" SG_ 643 IHU_25_AmbLig10Authn 0;
BA_ "GenSigSendType" SG_ 643 IHU_25_AmbLig09Authn 0;
BA_ "GenSigSendType" SG_ 643 IHU_25_AmbLig08Authn 0;
BA_ "GenSigSendType" SG_ 643 IHU_25_AmbLig07Authn 0;
BA_ "GenSigSendType" SG_ 643 IHU_25_AmbLig06Authn 0;
BA_ "GenSigSendType" SG_ 643 IHU_25_AmbLig05Authn 0;
BA_ "GenSigSendType" SG_ 643 IHU_25_AmbLig04Authn 0;
BA_ "GenSigSendType" SG_ 643 IHU_25_AmbLig03Authn 0;
BA_ "GenSigSendType" SG_ 643 IHU_25_AmbLig02Authn 0;
BA_ "GenSigSendType" SG_ 643 IHU_25_AmbLig01Authn 0;
BA_ "GenSigSendType" SG_ 1244 PassSeatMsgModeCmd 1;
BA_ "GenSigSendType" SG_ 1244 PassSeatMsgStr_LvlCmd 1;
BA_ "GenSigSendType" SG_ 1244 IHU_24_Reserved4 1;
BA_ "GenSigSendType" SG_ 1244 IHU_24_Reserved3 1;
BA_ "GenSigSendType" SG_ 1244 IHU_24_SetAdasDisp 1;
BA_ "GenSigSendType" SG_ 1244 IHU_24_SetBlueToothDisp 1;
BA_ "GenSigSendType" SG_ 1244 IHU_24_SetFaceIdOnoff 1;
BA_ "GenSigSendType" SG_ 1244 IHU_24_Reserved2 1;
BA_ "GenSigSendType" SG_ 1244 IHU_24_SetAdasDispPoision 1;
BA_ "GenSigSendType" SG_ 1244 IHU_24_SetNavDisp 1;
BA_ "GenSigSendType" SG_ 1244 IHU_24_SetHudBri 1;
BA_ "GenSigSendType" SG_ 1244 IHU_24_SetHudDispMod 1;
BA_ "GenSigSendType" SG_ 1244 IHU_24_Reserved1 1;
BA_ "GenSigSendType" SG_ 1244 IHU_24_SetHudHei 1;
BA_ "GenSigSendType" SG_ 1244 IHU_24_SetHudDispOnOff 1;
BA_ "GenSigSendType" SG_ 1035 IHU_23_CRC 0;
BA_ "GenSigSendType" SG_ 1035 IHU_23_MessageCounter 0;
BA_ "GenSigSendType" SG_ 1035 IHU_23_Reserved1 0;
BA_ "GenSigSendType" SG_ 1035 IHU_OTAPwrMngt 0;
BA_ "GenSigSendType" SG_ 1035 IHU_OTAHvReq 0;
BA_ "GenSigSendType" SG_ 1035 IHU_OTASts 0;
BA_ "GenSigSendType" SG_ 1278 IHU_22_Reserved1 2;
BA_ "GenSigSendType" SG_ 1278 IHU_SHU1RSeatAutVentnCmd 2;
BA_ "GenSigSendType" SG_ 1278 IHU_SHU1LSeatAutVentnCmd 2;
BA_ "GenSigSendType" SG_ 1278 IHU_SHU1RSeatAutHeatCmd 2;
BA_ "GenSigSendType" SG_ 1278 IHU_SHU1LSeatAutHeatCmd 2;
BA_ "GenSigSendType" SG_ 1278 SHU3RSeatVentilationCmd 2;
BA_ "GenSigSendType" SG_ 1278 SHU3LSeatVentilationCmd 2;
BA_ "GenSigSendType" SG_ 1278 SHU3RSeatHeatLevelCmd 2;
BA_ "GenSigSendType" SG_ 1278 SHU3LSeatHeatLevelCmd 2;
BA_ "GenSigSendType" SG_ 1278 SHU2RSeatVentilationCmd 2;
BA_ "GenSigSendType" SG_ 1278 SHU2MSeatVentilationCmd 2;
BA_ "GenSigSendType" SG_ 1278 SHU2LSeatVentilationCmd 2;
BA_ "GenSigSendType" SG_ 1278 SHU2RSeatHeatLevelCmd 2;
BA_ "GenSigSendType" SG_ 1278 SHU2MSeatHeatLevelCmd 2;
BA_ "GenSigSendType" SG_ 1278 SHU2LSeatHeatLevelCmd 2;
BA_ "GenSigSendType" SG_ 1278 SHU1RSeatVentilationCmd 2;
BA_ "GenSigSendType" SG_ 1278 SHU1LSeatVentilationCmd 2;
BA_ "GenSigSendType" SG_ 1278 SHU1RSeatHeatLevelCmd 2;
BA_ "GenSigSendType" SG_ 1278 SHU1LSeatHeatLevelCmd 2;
BA_ "GenSigSendType" SG_ 1119 IHU_19_Reserved_1 2;
BA_ "GenSigSendType" SG_ 1119 IHU_19_Set_HdrestSpkrMod 2;
BA_ "GenSigSendType" SG_ 1119 IHU_19_Set_AMPESEVol 2;
BA_ "GenSigSendType" SG_ 1119 IHU_19_Set_AMPWelVol 2;
BA_ "GenSigSendType" SG_ 1119 IHU_19_Set_AMPBTMediVol 2;
BA_ "GenSigSendType" SG_ 1119 IHU_19_REQ_AMPA2BMediSound 2;
BA_ "GenSigSendType" SG_ 1119 IHU_19_REQ_AMPA2BESESound 2;
BA_ "GenSigSendType" SG_ 1119 IHU_19_PABSetCmd 2;
BA_ "GenSigSendType" SG_ 1119 IHU_19_HwSet 2;
BA_ "GenSigSendType" SG_ 1119 IHU_19_BSRBPASet 2;
BA_ "GenSigSendType" SG_ 1119 REQ_AMPA2BKeyTone 2;
BA_ "GenSigSendType" SG_ 1119 REQ_AMPA2BTTSSound 2;
BA_ "GenSigSendType" SG_ 1119 REQ_AMPA2BVRSound 2;
BA_ "GenSigSendType" SG_ 1119 REQ_AMPA2BNaviSound 2;
BA_ "GenSigSendType" SG_ 1119 IHU_19_Reserved_2 2;
BA_ "GenSigSendType" SG_ 1119 Set_AMPMute 2;
BA_ "GenSigSendType" SG_ 1119 Set_AMPSpeedVolume 2;
BA_ "GenSigSendType" SG_ 1119 REQ_AMPA2BPhoneSound 2;
BA_ "GenSigSendType" SG_ 1100 Set_AMPAlarmVolume 2;
BA_ "GenSigSendType" SG_ 1100 Set_AMPLoudness 2;
BA_ "GenSigSendType" SG_ 1100 Set_AMPLiveAcoustics 2;
BA_ "GenSigSendType" SG_ 1100 Set_AMPSoundFieldFader 2;
BA_ "GenSigSendType" SG_ 1100 Set_AMPSoundFieldBalance 2;
BA_ "GenSigSendType" SG_ 1100 Set_AMPSoundEffectTreble 2;
BA_ "GenSigSendType" SG_ 1100 Set_AMPSoundEffectMidrange 2;
BA_ "GenSigSendType" SG_ 1100 Set_AMPSoundEffectBass 2;
BA_ "GenSigSendType" SG_ 1100 Set_AMPSoundEffect 2;
BA_ "GenSigSendType" SG_ 1100 Set_AMPRestoreDefaults 2;
BA_ "GenSigSendType" SG_ 1100 Set_AMPDefaultVolume 2;
BA_ "GenSigSendType" SG_ 1100 Set_AMPSoundFocus 2;
BA_ "GenSigSendType" SG_ 1100 Set_AMPPhoneVolume 2;
BA_ "GenSigSendType" SG_ 1100 Set_AMPMediaVolume 2;
BA_ "GenSigSendType" SG_ 1100 Set_AMPKeyTone 2;
BA_ "GenSigSendType" SG_ 1100 Set_AMPVRVolume 2;
BA_ "GenSigSendType" SG_ 1100 Set_AMPNaviVolume 2;
BA_ "GenSigSendType" SG_ 1065 IHU_16_Reserved3 2;
BA_ "GenSigSendType" SG_ 1065 IHU_16_SetReRowPwrKeyCmd 2;
BA_ "GenSigSendType" SG_ 1065 IHU_16_SetReRowBlowSpdLvlCmd 2;
BA_ "GenSigSendType" SG_ 1065 IHU_16_SetReRowWorkCmd 2;
BA_ "GenSigSendType" SG_ 1065 IHU_FragranceDisplayReq 2;
BA_ "GenSigSendType" SG_ 1065 IHU_PM2_5AutoRunSet 2;
BA_ "GenSigSendType" SG_ 1065 IHU_ANIONSwitch 2;
BA_ "GenSigSendType" SG_ 1065 IHU_RefreshFunction 2;
BA_ "GenSigSendType" SG_ 1065 IHU_ACModeCustom 2;
BA_ "GenSigSendType" SG_ 1065 IHU_FragranCeconsistenceLevel 2;
BA_ "GenSigSendType" SG_ 1065 IHU_FragranceSW 2;
BA_ "GenSigSendType" SG_ 1065 IHU_16_SetSeBlowSpdLvlDisp 2;
BA_ "GenSigSendType" SG_ 1065 IHU_16_SetSeWorking 2;
BA_ "GenSigSendType" SG_ 1065 IHU_16_SeIntelligentCustom 2;
BA_ "GenSigSendType" SG_ 1065 IHU_16_SetPtcHeatg 2;
BA_ "GenSigSendType" SG_ 1065 IHU_FragranceWelcomeMode 2;
BA_ "GenSigSendType" SG_ 1065 IHU_FragrancePosition 2;
BA_ "GenSigSendType" SG_ 1065 IHU_16_Reserved4 2;
BA_ "GenSigSendType" SG_ 1065 IHU_AutoBlueCallBlowSpeed 2;
BA_ "GenSigSendType" SG_ 1065 IHU_AutoParkInnerCirculation 2;
BA_ "GenSigSendType" SG_ 1065 IHU_16_Reserved1 0;
BA_ "GenSigSendType" SG_ 1296 IHU_15_Reserved5 0;
BA_ "GenSigSendType" SG_ 1296 CurrentTimeSecond 0;
BA_ "GenSigSendType" SG_ 1296 IHU_15_Reserved4 0;
BA_ "GenSigSendType" SG_ 1296 CurrentTimeMinute 0;
BA_ "GenSigSendType" SG_ 1296 IHU_15_Reserved3 0;
BA_ "GenSigSendType" SG_ 1296 CurrentTimeHour 0;
BA_ "GenSigSendType" SG_ 1296 IHU_15_Reserved2 0;
BA_ "GenSigSendType" SG_ 1296 CurrentTimeDay 0;
BA_ "GenSigStartValue" SG_ 1296 CurrentTimeDay 1;
BA_ "GenSigSendType" SG_ 1296 IHU_15_Reserved1 0;
BA_ "GenSigSendType" SG_ 1296 CurrentTimeMonth 0;
BA_ "GenSigStartValue" SG_ 1296 CurrentTimeMonth 1;
BA_ "GenSigSendType" SG_ 1296 CurrentTimeYear 0;
BA_ "GenSigSendType" SG_ 1336 IHU_14_Reserved1 0;
BA_ "GenSigSendType" SG_ 1336 Weather_Type 0;
BA_ "GenSigSendType" SG_ 1336 LPN_Info8 0;
BA_ "GenSigStartValue" SG_ 1336 LPN_Info8 127;
BA_ "GenSigSendType" SG_ 1336 LPN_Info7 0;
BA_ "GenSigStartValue" SG_ 1336 LPN_Info7 127;
BA_ "GenSigSendType" SG_ 1336 LPN_Info6 0;
BA_ "GenSigStartValue" SG_ 1336 LPN_Info6 127;
BA_ "GenSigSendType" SG_ 1336 LPN_Info5 0;
BA_ "GenSigStartValue" SG_ 1336 LPN_Info5 127;
BA_ "GenSigSendType" SG_ 1336 LPN_Info4 0;
BA_ "GenSigStartValue" SG_ 1336 LPN_Info4 127;
BA_ "GenSigSendType" SG_ 1336 LPN_Info3 0;
BA_ "GenSigStartValue" SG_ 1336 LPN_Info3 127;
BA_ "GenSigSendType" SG_ 1336 LPN_Info2 0;
BA_ "GenSigStartValue" SG_ 1336 LPN_Info2 127;
BA_ "GenSigSendType" SG_ 1336 LPN_Info1 0;
BA_ "GenSigStartValue" SG_ 1336 LPN_Info1 127;
BA_ "GenSigSendType" SG_ 1112 HU_13_Reserved8 0;
BA_ "GenSigSendType" SG_ 1112 IHU_13_Reserved7 0;
BA_ "GenSigSendType" SG_ 1112 MusicLoudness_6000HZ 0;
BA_ "GenSigSendType" SG_ 1112 IHU_13_Reserved6 0;
BA_ "GenSigSendType" SG_ 1112 MusicLoudness_2000HZ 0;
BA_ "GenSigSendType" SG_ 1112 IHU_13_Reserved5 0;
BA_ "GenSigSendType" SG_ 1112 MusicLoudness_1500HZ 0;
BA_ "GenSigSendType" SG_ 1112 IHU_13_Reserved4 0;
BA_ "GenSigSendType" SG_ 1112 MusicShowCMD 0;
BA_ "GenSigSendType" SG_ 1112 MusicLoudness_1000HZ 0;
BA_ "GenSigSendType" SG_ 1112 IHU_13_Reserved3 0;
BA_ "GenSigSendType" SG_ 1112 MusicLoudness_500HZ 0;
BA_ "GenSigSendType" SG_ 1112 LiShowMod 0;
BA_ "GenSigSendType" SG_ 1112 MusicLoudness_250HZ 0;
BA_ "GenSigSendType" SG_ 1112 ADBenable 0;
BA_ "GenSigSendType" SG_ 1112 DVD_StandbyModeSts 0;
BA_ "GenSigSendType" SG_ 1112 MusicLoudness_120HZ 0;
BA_ "GenSigSendType" SG_ 1114 MusicShowCMD 2;
BA_ "GenSigSendType" SG_ 1114 IHU_12_Reserved8 2;
BA_ "GenSigSendType" SG_ 1114 LightShowCmd 2;
BA_ "GenSigSendType" SG_ 1114 DVRSnapshot 2;
BA_ "GenSigSendType" SG_ 1114 AVMSwt 2;
BA_ "GenSigSendType" SG_ 1114 IHU_12_Reserved6 2;
BA_ "GenSigSendType" SG_ 1114 TouchEvt 2;
BA_ "GenSigSendType" SG_ 1114 LDWSensitivitySetting 2;
BA_ "GenSigSendType" SG_ 1114 IHU_APAKeySts 2;
BA_ "GenSigSendType" SG_ 1114 IHU_12_Reserved4 2;
BA_ "GenSigSendType" SG_ 1114 LDWSwitchSts 2;
BA_ "GenSigSendType" SG_ 1114 IHU_12_Reserved3 2;
BA_ "GenSigSendType" SG_ 1114 IHU_12_DMSSwtSet 2;
BA_ "GenSigSendType" SG_ 1114 IHU_12_CarMdlSetColor 2;
BA_ "GenSigSendType" SG_ 1114 CalibrationReq 2;
BA_ "GenSigSendType" SG_ 1114 RRMDisplayAVMOff 2;
BA_ "GenSigSendType" SG_ 1114 NaviBtnPressInputValueY 2;
BA_ "GenSigStartValue" SG_ 1114 NaviBtnPressInputValueY 65535;
BA_ "GenSigSendType" SG_ 1114 NaviBtnPressInputValueX 2;
BA_ "GenSigStartValue" SG_ 1114 NaviBtnPressInputValueX 65535;
BA_ "GenSigSendType" SG_ 1276 IHU_11_Reserved3 2;
BA_ "GenSigSendType" SG_ 1276 IHU_11_ASUStyleSet 2;
BA_ "GenSigSendType" SG_ 1276 IHU_11_ASUAssocWithDrvrModSet 2;
BA_ "GenSigSendType" SG_ 1276 DVD_SET_EPS_Assistance_Style 2;
BA_ "GenSigStartValue" SG_ 1276 DVD_SET_EPS_Assistance_Style 2;
BA_ "GenSigSendType" SG_ 1276 DVD_SET_EPS_AssociWithDriverMode 2;
BA_ "GenSigSendType" SG_ 1276 IHU_11_ELKSwtSet 2;
BA_ "GenSigSendType" SG_ 1276 IHU_11_LDWLDPSnvtySet 2;
BA_ "GenSigSendType" SG_ 1276 IHU_11_LDPSwtSet 2;
BA_ "GenSigSendType" SG_ 1276 IHU_11_WarnModSwtSet 2;
BA_ "GenSigSendType" SG_ 1276 IHU_11_LDWSwtSet 2;
BA_ "GenSigSendType" SG_ 1276 IHU_11_TLISwtSet 2;
BA_ "GenSigSendType" SG_ 1276 IHU_11_TSISwtSet 2;
BA_ "GenSigSendType" SG_ 1276 IHU_11_HMASwtSet 2;
BA_ "GenSigSendType" SG_ 1276 IHU_11_IESSwtSet 2;
BA_ "GenSigSendType" SG_ 1276 IHU_11_DAISwtSet 2;
BA_ "GenSigSendType" SG_ 1276 IHU_11_Resd2 2;
BA_ "GenSigSendType" SG_ 1276 IHU_11_SCFSwtSet 2;
BA_ "GenSigSendType" SG_ 1276 IHU_11_SLASwtSet 2;
BA_ "GenSigSendType" SG_ 1276 IHU_11_TJAICAExitTextInfoSwtSet 2;
BA_ "GenSigSendType" SG_ 1276 IHU_11_FCWSwtSet 2;
BA_ "GenSigSendType" SG_ 1276 IHU_11_FCWSnvtySet 2;
BA_ "GenSigSendType" SG_ 1276 IHU_11_AEBSwtSet 2;
BA_ "GenSigSendType" SG_ 1276 IHU_11_RCTBSwtSet 2;
BA_ "GenSigSendType" SG_ 1276 IHU_11_RAEBSwtSet 2;
BA_ "GenSigSendType" SG_ 1276 IHU_11_BSDSwitchSts 2;
BA_ "GenSigSendType" SG_ 1276 DVD_SET_RCW 2;
BA_ "GenSigSendType" SG_ 1276 DVD_SET_DOW 2;
BA_ "GenSigSendType" SG_ 1276 IHU_11_Reserved1 2;
BA_ "GenSigSendType" SG_ 1276 DVD_SET_CWC_PhoneforgottenFunSts 2;
BA_ "GenSigStartValue" SG_ 1276 DVD_SET_CWC_PhoneforgottenFunSts 3;
BA_ "GenSigSendType" SG_ 1276 ModeKeySts 2;
BA_ "GenSigSendType" SG_ 1276 DVD_SET_ModeKeyFunctionType 2;
BA_ "GenSigSendType" SG_ 1276 DVD_SET_CWC_WorkingSts 2;
BA_ "GenSigStartValue" SG_ 1276 DVD_SET_CWC_WorkingSts 3;
BA_ "GenSigSendType" SG_ 1335 IHU_10_Reserved_2 0;
BA_ "GenSigSendType" SG_ 1335 LightShowMod 0;
BA_ "GenSigStartValue" SG_ 1335 LightShowMod 2;
BA_ "GenSigSendType" SG_ 1335 Reserved_IHU_10_TrackMod 0;
BA_ "GenSigSendType" SG_ 1335 IHU_10_MirrorSet 0;
BA_ "GenSigSendType" SG_ 1335 IHU_10_ISSFctCmd 0;
BA_ "GenSigStartValue" SG_ 1335 IHU_10_ISSFctCmd 1;
BA_ "GenSigSendType" SG_ 1335 Set_HUDSteerpan 0;
BA_ "GenSigStartValue" SG_ 1335 Set_HUDSteerpan 1;
BA_ "GenSigSendType" SG_ 1335 IHU_DriveMode 0;
BA_ "GenSigStartValue" SG_ 1335 IHU_DriveMode 6;
BA_ "GenSigSendType" SG_ 1335 NavCurrRoadType 0;
BA_ "GenSigSendType" SG_ 1335 Reserved_NavCountryCode 0;
BA_ "GenSigSendType" SG_ 1335 IHU_10_Reserved_1 0;
BA_ "GenSigSendType" SG_ 1335 NavSpeedLimitUnits 0;
BA_ "GenSigSendType" SG_ 1335 NavSpeedLimit 0;
BA_ "GenSigSendType" SG_ 1335 NavSpeedLimitStatus 0;
BA_ "GenSigSendType" SG_ 1273 IHU_SET_AIPMBrightnessLevel 2;
BA_ "GenSigSendType" SG_ 1273 DVD_SetLightedRoofRackStatus 2;
BA_ "GenSigSendType" SG_ 1273 DrvrDoorUnlckOnlyStsSet 2;
BA_ "GenSigSendType" SG_ 1273 BlowSpeedLevelKeySts 4;
BA_ "GenSigSendType" SG_ 1273 IHU_SetTheaterDimmingColor_64 2;
BA_ "GenSigSendType" SG_ 1273 IHU_9_FrntRadarSwt 2;
BA_ "GenSigSendType" SG_ 1273 IHU_DriverSeatHeatLevelCmd 2;
BA_ "GenSigSendType" SG_ 1273 DVD_SET_BLTKey_PESts 2;
BA_ "GenSigSendType" SG_ 1273 FaceID 2;
BA_ "GenSigSendType" SG_ 1273 Delete_ID_Info 2;
BA_ "GenSigSendType" SG_ 1273 DVD_SET_AutoFoldSts 2;
BA_ "GenSigSendType" SG_ 1273 IHU_DriverSeatVentilationKeySts 2;
BA_ "GenSigSendType" SG_ 1273 DVD_SET_HeadlampHeightSts 2;
BA_ "GenSigSendType" SG_ 1273 Reserved_SASSwitchStatus 2;
BA_ "GenSigStartValue" SG_ 1273 Reserved_SASSwitchStatus 2;
BA_ "GenSigSendType" SG_ 1273 Reserved_DVD_SET_RemoteTrunkOnly 2;
BA_ "GenSigSendType" SG_ 1273 Reserved_DVD_SET_UrgeBrakemode 2;
BA_ "GenSigSendType" SG_ 1273 Reserved_DVD_SET_AidTurnIlumin 2;
BA_ "GenSigSendType" SG_ 1273 DVD_SET_DRLModeSts 2;
BA_ "GenSigSendType" SG_ 1273 DVD_SET_HeadlampDelayLightSts 2;
BA_ "GenSigSendType" SG_ 1273 DVD_SET_RemoteLockFeedback 2;
BA_ "GenSigSendType" SG_ 1273 IHU_ISS_Switch 2;
BA_ "GenSigSendType" SG_ 1273 DVD_SET_AutolockSts 2;
BA_ "GenSigSendType" SG_ 1273 Reserved_DVD_SET_AutoUnlockSts 2;
BA_ "GenSigSendType" SG_ 1272 DVD_Set_FGHeatSts 4;
BA_ "GenSigSendType" SG_ 1272 IHU_WindowCmd 2;
BA_ "GenSigSendType" SG_ 1272 IHU_8_Reserved_2 2;
BA_ "GenSigSendType" SG_ 1272 Set_Default 2;
BA_ "GenSigSendType" SG_ 1272 Seat_ExtMirror_PosStoreReq_ID 2;
BA_ "GenSigSendType" SG_ 1272 Seat_ExtMirror_PosRecall_ID 2;
BA_ "GenSigSendType" SG_ 1272 DVD_Set_ReverseExtMirrorSts 2;
BA_ "GenSigSendType" SG_ 1272 DVD_Set_EasyEntrySts 2;
BA_ "GenSigSendType" SG_ 1272 DVD_SetSCURelateKeyOrFaceID 2;
BA_ "GenSigSendType" SG_ 1272 DVD_SetAssociatedWithMusicMode 2;
BA_ "GenSigSendType" SG_ 1272 DVD_SetAssociatedWithDriverMode 2;
BA_ "GenSigSendType" SG_ 1272 DVD_SetTheaterDimmingBrightness 2;
BA_ "GenSigSendType" SG_ 1272 SetTheaterDimmingColor 2;
BA_ "GenSigSendType" SG_ 1272 DVD_SetTheaterDimmingStatus 2;
BA_ "GenSigSendType" SG_ 1272 Reserved_Set_MFS_Stuck_Duration 2;
BA_ "GenSigSendType" SG_ 1272 Set_WelLightPolling 2;
BA_ "GenSigSendType" SG_ 1272 Set_PEPS_IntelligentOpen 2;
BA_ "GenSigSendType" SG_ 1272 Set_PEPS_Polling 2;
BA_ "GenSigSendType" SG_ 1272 IHU_8_Reserved_1 2;
BA_ "GenSigSendType" SG_ 1272 IHU_8_SunshadeCmd 2;
BA_ "GenSigSendType" SG_ 1272 IHU_PSRFCmd 2;
BA_ "GenSigSendType" SG_ 1272 IHU_SRFCmd 2;
BA_ "GenSigSendType" SG_ 1309 LDWOnOffReq 2;
BA_ "GenSigStartValue" SG_ 1309 LDWOnOffReq 1;
BA_ "GenSigSendType" SG_ 1309 IHU_7_Reserved_6 2;
BA_ "GenSigSendType" SG_ 1309 TimeGapLastSetReq 2;
BA_ "GenSigStartValue" SG_ 1309 TimeGapLastSetReq 1;
BA_ "GenSigSendType" SG_ 1309 IHU_7_Reserved_5 2;
BA_ "GenSigSendType" SG_ 1309 IHU_7_Reserved_4 2;
BA_ "GenSigSendType" SG_ 1309 LDW_LKA_SensitivityReq 2;
BA_ "GenSigStartValue" SG_ 1309 LDW_LKA_SensitivityReq 2;
BA_ "GenSigSendType" SG_ 1309 IHU_7_Reserved_3 2;
BA_ "GenSigSendType" SG_ 1309 IHU_7_DrvAssiStyle 2;
BA_ "GenSigSendType" SG_ 1309 IHU_7_DCLCONOFF 2;
BA_ "GenSigSendType" SG_ 1309 HMAOnOffReq 2;
BA_ "GenSigStartValue" SG_ 1309 HMAOnOffReq 2;
BA_ "GenSigSendType" SG_ 1309 IHU_AutHldSet 2;
BA_ "GenSigSendType" SG_ 1309 IHU_7_Reserved_8 2;
BA_ "GenSigSendType" SG_ 1309 SCF_ON_OFF 2;
BA_ "GenSigSendType" SG_ 1309 SLAOnOffReq 2;
BA_ "GenSigStartValue" SG_ 1309 SLAOnOffReq 2;
BA_ "GenSigSendType" SG_ 1309 IHU_7_Reserved_1 2;
BA_ "GenSigSendType" SG_ 1309 IHU_7_Reserved_7 4;
BA_ "GenSigSendType" SG_ 1309 Set_ESPFunctionSts 2;
BA_ "GenSigSendType" SG_ 1309 TIHU_SetHDCOnOff 4;
BA_ "GenSigSendType" SG_ 1309 CST_SensitivityReq 2;
BA_ "GenSigSendType" SG_ 1309 BrakepedalfeelModeSetReq 2;
BA_ "GenSigSendType" SG_ 1309 IHU_AssociateDriveModeSet 2;
BA_ "GenSigSendType" SG_ 1309 Set_CSTFunctionSts 2;
BA_ "GenSigSendType" SG_ 1309 DistanceWarning_on_off 2;
BA_ "GenSigSendType" SG_ 1309 TJA_ICA_ON_OFF 2;
BA_ "GenSigSendType" SG_ 1309 AEB_ON_OFF 2;
BA_ "GenSigSendType" SG_ 1309 FCW_OPTION 2;
BA_ "GenSigSendType" SG_ 1309 FCW_ON_OFF 2;
BA_ "GenSigSendType" SG_ 1309 TimeGapSet1Req 2;
BA_ "GenSigSendType" SG_ 1074 IHU_6_Reserved6 0;
BA_ "GenSigSendType" SG_ 1074 IHU_6_Reserved5 0;
BA_ "GenSigSendType" SG_ 1074 IHU_6_Reserved4 0;
BA_ "GenSigSendType" SG_ 1074 IHU_6_Reserved3 0;
BA_ "GenSigSendType" SG_ 1074 IHU_6_TouchEvt 2;
BA_ "GenSigSendType" SG_ 1074 IHU_6_Reserved2 0;
BA_ "GenSigSendType" SG_ 1074 IHU_6_TrajectorySetting 2;
BA_ "GenSigSendType" SG_ 1074 IHU_6_LDWSwitchSts 4;
BA_ "GenSigSendType" SG_ 1074 IHU_6_AVM3DAroundViewSW 2;
BA_ "GenSigSendType" SG_ 1074 IHU_6_SideViewSW 2;
BA_ "GenSigSendType" SG_ 1074 IHU_6_Reserved1 0;
BA_ "GenSigSendType" SG_ 1074 Reserved_CarModelColor 0;
BA_ "GenSigSendType" SG_ 1074 IHU_6_CalibrationReq 2;
BA_ "GenSigSendType" SG_ 1074 IHU_6_RRMDisplayAVMOff 2;
BA_ "GenSigSendType" SG_ 1074 IHU_6_NaviBtnPressInputValueY 2;
BA_ "GenSigStartValue" SG_ 1074 IHU_6_NaviBtnPressInputValueY 65535;
BA_ "GenSigSendType" SG_ 1074 IHU_6_NaviBtnPressInputValueX 2;
BA_ "GenSigStartValue" SG_ 1074 IHU_6_NaviBtnPressInputValueX 65535;
BA_ "GenSigSendType" SG_ 1305 AUTODefrostOnKeySts 2;
BA_ "GenSigSendType" SG_ 1305 PM2_5DisplayReq 2;
BA_ "GenSigSendType" SG_ 1305 DVD_SET_PM2_5Sts 2;
BA_ "GenSigSendType" SG_ 1305 BlowDelayOffKeySts 2;
BA_ "GenSigSendType" SG_ 1305 BlowAdvanceOnKeySts 2;
BA_ "GenSigSendType" SG_ 1305 IHU_4_Reserved1 2;
BA_ "GenSigSendType" SG_ 1305 ElecClimateSetTemp 2;
BA_ "GenSigSendType" SG_ 1305 SetTemperature_R_F 2;
BA_ "GenSigStartValue" SG_ 1305 SetTemperature_R_F 17;
BA_ "GenSigSendType" SG_ 1305 SetTemperature_L_F 2;
BA_ "GenSigStartValue" SG_ 1305 SetTemperature_L_F 17;
BA_ "GenSigSendType" SG_ 1305 DVD_ZoneSelectionKeySts 2;
BA_ "GenSigSendType" SG_ 1305 DVD_SetCirculationModeKeySts 2;
BA_ "GenSigSendType" SG_ 1305 SetTemperature_R_C 2;
BA_ "GenSigStartValue" SG_ 1305 SetTemperature_R_C 17;
BA_ "GenSigSendType" SG_ 1305 SetTemperature_L_C 2;
BA_ "GenSigStartValue" SG_ 1305 SetTemperature_L_C 17;
BA_ "GenSigSendType" SG_ 1305 Set_TimeAMPM 2;
BA_ "GenSigSendType" SG_ 1305 IHU_4_Reserved4 2;
BA_ "GenSigSendType" SG_ 1305 ModeAdjustKeySts 2;
BA_ "GenSigStartValue" SG_ 1305 ModeAdjustKeySts 7;
BA_ "GenSigSendType" SG_ 1305 Reserved_DVD_SetAC_MaxKeySts 2;
BA_ "GenSigSendType" SG_ 1305 DVD_SetTemperatureUnit 2;
BA_ "GenSigSendType" SG_ 1305 DVD_SetMaxFrontDeforestSts 2;
BA_ "GenSigSendType" SG_ 1305 BlowSpeedLevelKeySts 2;
BA_ "GenSigSendType" SG_ 1305 DVD_SetAutoKeySts 2;
BA_ "GenSigSendType" SG_ 1305 DVD_SetACRequestKeySts 2;
BA_ "GenSigSendType" SG_ 1305 DVD_SetCLMOn 2;
BA_ "GenSigSendType" SG_ 1305 Set_Time24H12H 2;
BA_ "GenSigSendType" SG_ 1305 IHU_4_CVBOXRstReq 2;
BA_ "GenSigSendType" SG_ 1303 IHU_3_Reserved1 2;
BA_ "GenSigSendType" SG_ 1303 DVD_SetThemeType 2;
BA_ "GenSigSendType" SG_ 1303 IHU_3_Reserved2 4;
BA_ "GenSigSendType" SG_ 1303 IHU_LDWLKA_LaneAssitTypeReq 2;
BA_ "GenSigSendType" SG_ 1303 TimeSetYear 2;
BA_ "GenSigSendType" SG_ 1303 TimeSetMonth 2;
BA_ "GenSigStartValue" SG_ 1303 TimeSetMonth 1;
BA_ "GenSigSendType" SG_ 1303 TimeSetDay 2;
BA_ "GenSigStartValue" SG_ 1303 TimeSetDay 1;
BA_ "GenSigSendType" SG_ 1303 DVD_Set_PLGPositionSts 2;
BA_ "GenSigStartValue" SG_ 1303 DVD_Set_PLGPositionSts 100;
BA_ "GenSigSendType" SG_ 1303 DVD_TrunkCmd 2;
BA_ "GenSigSendType" SG_ 1303 TimeSetSecond 2;
BA_ "GenSigSendType" SG_ 1303 IHU_SET_ICMBrightnessLevel 2;
BA_ "GenSigSendType" SG_ 1303 FatigureDrivingTime 2;
BA_ "GenSigSendType" SG_ 1303 TimeSetMinute 2;
BA_ "GenSigSendType" SG_ 1303 TimeSetHour 2;
BA_ "GenSigSendType" SG_ 1302 ClimateDisplayReq 0;
BA_ "GenSigSendType" SG_ 1302 CarAngle 0;
BA_ "GenSigSendType" SG_ 1302 IHU_2_Reserved_3 0;
BA_ "GenSigSendType" SG_ 1302 IHU_2_Reserved_1 0;
BA_ "GenSigSendType" SG_ 1302 BltCallSts 0;
BA_ "GenSigSendType" SG_ 1302 PanelKeyVoiceSource 0;
BA_ "GenSigSendType" SG_ 1302 RadioVolume 0;
BA_ "GenSigStartValue" SG_ 1302 RadioVolume 6;
BA_ "GenSigSendType" SG_ 1302 AMRadioFrequanceValue 0;
BA_ "GenSigStartValue" SG_ 1302 AMRadioFrequanceValue 530;
BA_ "GenSigSendType" SG_ 1302 FMRadioFrequanceValue 0;
BA_ "GenSigStartValue" SG_ 1302 FMRadioFrequanceValue 17500;
BA_ "GenSigSendType" SG_ 1302 RRMOnSts 0;
BA_ "GenSigSendType" SG_ 1302 SourceStationMode 0;
BA_ "GenSigStartValue" SG_ 1302 SourceStationMode 1;
BA_ "GenSigSendType" SG_ 1302 RadioResearchSts 0;
BA_ "GenSigStartValue" SG_ 1302 RadioResearchSts 1;
BA_ "GenSigSendType" SG_ 1302 RadioFrequanceMode 0;
BA_ "GenSigStartValue" SG_ 1302 RadioFrequanceMode 1;
BA_ "GenSigSendType" SG_ 1301 IHU_1_Reserved_4 0;
BA_ "GenSigSendType" SG_ 1301 BSDSwitchSts 2;
BA_ "GenSigSendType" SG_ 1301 RRMResolutionY 0;
BA_ "GenSigSendType" SG_ 1301 RRMResolutionX 0;
BA_ "GenSigSendType" SG_ 1301 LanguageSet 2;
BA_ "GenSigSendType" SG_ 1301 OverSpeedValue 2;
BA_ "GenSigSendType" SG_ 1301 IHU_1_Reserved_2 0;
BA_ "GenSigSendType" SG_ 1301 IHU_1_Reserved_1 0;
BA_ "GenSigSendType" SG_ 1039 DMS_1_CRC 0;
BA_ "GenSigSendType" SG_ 1039 DMS_1_MessageCounter 0;
BA_ "GenSigSendType" SG_ 1039 DMS_1_Resd1 0;
BA_ "GenSigSendType" SG_ 1039 DMS_1_Atte_Regn 0;
BA_ "GenSigSendType" SG_ 1039 DMS_1_DrvrAbnormStAlrm 0;
BA_ "GenSigSendType" SG_ 1039 DMS_1_AlrmSwtSt 0;
BA_ "GenSigStartValue" SG_ 1039 DMS_1_AlrmSwtSt 1;
BA_ "GenSigSendType" SG_ 1039 DMS_1_DrvUnrspvSt 0;
BA_ "GenSigSendType" SG_ 1039 DMS_1_DrvrAlertSt 0;
BA_ "GenSigSendType" SG_ 1039 DMS_1_CameraSt 0;
BA_ "GenSigSendType" SG_ 1039 DMS_1_DrvrFatiLvlCfdec 0;
BA_ "GenSigSendType" SG_ 1039 DMS_1_DrvrDistrLvlCfdec 0;
BA_ "GenSigSendType" SG_ 1039 DMS_1_DMSSt 0;
BA_ "GenSigSendType" SG_ 1039 DMS_1_DrvrFatiLvl 0;
BA_ "GenSigSendType" SG_ 1039 DMS_1_DrvrDistrLvl 0;
BA_ "GenSigSendType" SG_ 1253 CVBOX_1_Reserved 0;
BA_ "GenSigSendType" SG_ 1253 OMSMod 0;
BA_ "GenSigSendType" SG_ 1253 DVRSts 0;
BA_ "GenSigSendType" SG_ 1253 RMSSts 0;
BA_ "GenSigSendType" SG_ 1253 OMSSts 0;
BA_ "GenSigSendType" SG_ 1253 DMSSts 0;
BA_ "GenSigSendType" SG_ 1109 CWC_1_ChrgFlt 0;
BA_ "GenSigSendType" SG_ 1109 CWC_Phoneforgotten_ON_OFF_Sts 0;
BA_ "GenSigStartValue" SG_ 1109 CWC_Phoneforgotten_ON_OFF_Sts 1;
BA_ "GenSigSendType" SG_ 1109 CWC_Phoneforgotten 0;
BA_ "GenSigSendType" SG_ 1109 CWC_workingSts 0;
BA_ "GenSigStartValue" SG_ 1109 CWC_workingSts 1;
BA_ "GenSigSendType" SG_ 1109 CWC_ChargingSts 0;
BA_ "GenSigSendType" SG_ 1050 AVM_3_Reserved4 0;
BA_ "GenSigSendType" SG_ 1050 AVM_FactoryMode 0;
BA_ "GenSigSendType" SG_ 1050 AVMFeedbackSts_RemoteMode 0;
BA_ "GenSigSendType" SG_ 1050 AVM_3_Reserved3 0;
BA_ "GenSigSendType" SG_ 1050 Reserved_ViewStsRsp 0;
BA_ "GenSigSendType" SG_ 1050 AVM_3_Reserved2 0;
BA_ "GenSigSendType" SG_ 1050 AVM_3_Reserved1 0;
BA_ "GenSigSendType" SG_ 1050 AVMDisplaySts 0;
BA_ "GenSigSendType" SG_ 1288 AVM_2_Reserved1 0;
BA_ "GenSigSendType" SG_ 1288 AVMStatusFault 0;
BA_ "GenSigSendType" SG_ 1288 AVMFaultStatusCameraRight 0;
BA_ "GenSigSendType" SG_ 1288 AVMFaultStatusCameraRear 0;
BA_ "GenSigSendType" SG_ 1288 AVMFaultStatusCameraLeft 0;
BA_ "GenSigSendType" SG_ 1288 AVMFaultStatusCameraFront 0;
VAL_ 1177 IHU_26_RRWinCmd 127 "Reserved" 126 "Reserved" 125 "Reserved" 124 "Reserved" 123 "Reserved" 122 "Reserved" 121 "Reserved" 120 "Reserved" 119 "Reserved" 118 "Reserved" 117 "Reserved" 116 "Reserved" 115 "Reserved" 114 "Reserved" 113 "Reserved" 112 "Reserved" 111 "Reserved" 110 "Reserved" 109 "Reserved" 108 "Reserved" 107 "Reserved" 106 "Reserved" 105 "Reserved" 104 "Reserved" 103 "Reserved" 102 "Reserved" 101 "Reserved" 100 "100%" 99 "99%" 98 "98%" 97 "97%" 96 "96%" 95 "95%" 94 "94%" 93 "93%" 92 "92%" 91 "91%" 90 "90%" 89 "89%" 88 "88%" 87 "87%" 86 "86%" 85 "85%" 84 "84%" 83 "83%" 82 "82%" 81 "81%" 80 "80%" 79 "79%" 78 "78%" 77 "77%" 76 "76%" 75 "75%" 74 "74%" 73 "73%" 72 "72%" 71 "71%" 70 "70%" 69 "69%" 68 "68%" 67 "67%" 66 "66%" 65 "65%" 64 "64%" 63 "63%" 62 "62%" 61 "61%" 60 "60%" 59 "59%" 58 "58%" 57 "57%" 56 "56%" 55 "55%" 54 "54%" 53 "53%" 52 "52%" 51 "51%" 50 "50%" 49 "49%" 48 "48%" 47 "47%" 46 "46%" 45 "45%" 44 "44%" 43 "43%" 42 "42%" 41 "41%" 40 "40%" 39 "39%" 38 "38%" 37 "37%" 36 "36%" 35 "35%" 34 "34%" 33 "33%" 32 "32%" 31 "31%" 30 "30%" 29 "29%" 28 "28%" 27 "27%" 26 "26%" 25 "25%" 24 "24%" 23 "23%" 22 "22%" 21 "21%" 20 "20%" 19 "19%" 18 "18%" 17 "17%" 16 "16%" 15 "15%" 14 "14%" 13 "13%" 12 "12%" 11 "11%" 10 "10%" 9 "9%" 8 "8%" 7 "7%" 6 "6%" 5 "5%" 4 "4%" 3 "3%" 2 "2%" 1 "1%" 0 "Not active" ;
VAL_ 1177 IHU_26_WiprSnvty 6 "Reserved" 5 "Reserved" 4 "Level4" 3 "Level3" 2 "Level2" 1 "Level1" 0 "Not Active" ;
VAL_ 1177 IHU_26_SeatLegSpprtPosnCmd 15 "Reserved" 14 "Reserved" 13 "Reserved" 12 "Reserved" 11 "100%" 10 "90% " 9 "80% " 8 "70% " 7 "60% " 6 "50% " 5 "40% " 4 "30% " 3 "20% " 2 "10% " 1 "0% " 0 "Not active " ;
VAL_ 1177 IHU_26_RLWinCmd 127 "Reserved" 126 "Reserved" 125 "Reserved" 124 "Reserved" 123 "Reserved" 122 "Reserved" 121 "Reserved" 120 "Reserved" 119 "Reserved" 118 "Reserved" 117 "Reserved" 116 "Reserved" 115 "Reserved" 114 "Reserved" 113 "Reserved" 112 "Reserved" 111 "Reserved" 110 "Reserved" 109 "Reserved" 108 "Reserved" 107 "Reserved" 106 "Reserved" 105 "Reserved" 104 "Reserved" 103 "Reserved" 102 "Reserved" 101 "Reserved" 100 "100%" 99 "99%" 98 "98%" 97 "97%" 96 "96%" 95 "95%" 94 "94%" 93 "93%" 92 "92%" 91 "91%" 90 "90%" 89 "89%" 88 "88%" 87 "87%" 86 "86%" 85 "85%" 84 "84%" 83 "83%" 82 "82%" 81 "81%" 80 "80%" 79 "79%" 78 "78%" 77 "77%" 76 "76%" 75 "75%" 74 "74%" 73 "73%" 72 "72%" 71 "71%" 70 "70%" 69 "69%" 68 "68%" 67 "67%" 66 "66%" 65 "65%" 64 "64%" 63 "63%" 62 "62%" 61 "61%" 60 "60%" 59 "59%" 58 "58%" 57 "57%" 56 "56%" 55 "55%" 54 "54%" 53 "53%" 52 "52%" 51 "51%" 50 "50%" 49 "49%" 48 "48%" 47 "47%" 46 "46%" 45 "45%" 44 "44%" 43 "43%" 42 "42%" 41 "41%" 40 "40%" 39 "39%" 38 "38%" 37 "37%" 36 "36%" 35 "35%" 34 "34%" 33 "33%" 32 "32%" 31 "31%" 30 "30%" 29 "29%" 28 "28%" 27 "27%" 26 "26%" 25 "25%" 24 "24%" 23 "23%" 22 "22%" 21 "21%" 20 "20%" 19 "19%" 18 "18%" 17 "17%" 16 "16%" 15 "15%" 14 "14%" 13 "13%" 12 "12%" 11 "11%" 10 "10%" 9 "9%" 8 "8%" 7 "7%" 6 "6%" 5 "5%" 4 "4%" 3 "3%" 2 "2%" 1 "1%" 0 "Not active" ;
VAL_ 1177 IHU_26_FRWinCmd 127 "Reserved" 126 "Reserved" 125 "Reserved" 124 "Reserved" 123 "Reserved" 122 "Reserved" 121 "Reserved" 120 "Reserved" 119 "Reserved" 118 "Reserved" 117 "Reserved" 116 "Reserved" 115 "Reserved" 114 "Reserved" 113 "Reserved" 112 "Reserved" 111 "Reserved" 110 "Reserved" 109 "Reserved" 108 "Reserved" 107 "Reserved" 106 "Reserved" 105 "Reserved" 104 "Reserved" 103 "Reserved" 102 "Reserved" 101 "Reserved" 100 "100%" 99 "99%" 98 "98%" 97 "97%" 96 "96%" 95 "95%" 94 "94%" 93 "93%" 92 "92%" 91 "91%" 90 "90%" 89 "89%" 88 "88%" 87 "87%" 86 "86%" 85 "85%" 84 "84%" 83 "83%" 82 "82%" 81 "81%" 80 "80%" 79 "79%" 78 "78%" 77 "77%" 76 "76%" 75 "75%" 74 "74%" 73 "73%" 72 "72%" 71 "71%" 70 "70%" 69 "69%" 68 "68%" 67 "67%" 66 "66%" 65 "65%" 64 "64%" 63 "63%" 62 "62%" 61 "61%" 60 "60%" 59 "59%" 58 "58%" 57 "57%" 56 "56%" 55 "55%" 54 "54%" 53 "53%" 52 "52%" 51 "51%" 50 "50%" 49 "49%" 48 "48%" 47 "47%" 46 "46%" 45 "45%" 44 "44%" 43 "43%" 42 "42%" 41 "41%" 40 "40%" 39 "39%" 38 "38%" 37 "37%" 36 "36%" 35 "35%" 34 "34%" 33 "33%" 32 "32%" 31 "31%" 30 "30%" 29 "29%" 28 "28%" 27 "27%" 26 "26%" 25 "25%" 24 "24%" 23 "23%" 22 "22%" 21 "21%" 20 "20%" 19 "19%" 18 "18%" 17 "17%" 16 "16%" 15 "15%" 14 "14%" 13 "13%" 12 "12%" 11 "11%" 10 "10%" 9 "9%" 8 "8%" 7 "7%" 6 "6%" 5 "5%" 4 "4%" 3 "3%" 2 "2%" 1 "1%" 0 "Not active" ;
VAL_ 1177 IHU_26_FLWinCmd 127 "Reserved" 126 "Reserved" 125 "Reserved" 124 "Reserved" 123 "Reserved" 122 "Reserved" 121 "Reserved" 120 "Reserved" 119 "Reserved" 118 "Reserved" 117 "Reserved" 116 "Reserved" 115 "Reserved" 114 "Reserved" 113 "Reserved" 112 "Reserved" 111 "Reserved" 110 "Reserved" 109 "Reserved" 108 "Reserved" 107 "Reserved" 106 "Reserved" 105 "Reserved" 104 "Reserved" 103 "Reserved" 102 "Reserved" 101 "Reserved" 100 "100%" 99 "99%" 98 "98%" 97 "97%" 96 "96%" 95 "95%" 94 "94%" 93 "93%" 92 "92%" 91 "91%" 90 "90%" 89 "89%" 88 "88%" 87 "87%" 86 "86%" 85 "85%" 84 "84%" 83 "83%" 82 "82%" 81 "81%" 80 "80%" 79 "79%" 78 "78%" 77 "77%" 76 "76%" 75 "75%" 74 "74%" 73 "73%" 72 "72%" 71 "71%" 70 "70%" 69 "69%" 68 "68%" 67 "67%" 66 "66%" 65 "65%" 64 "64%" 63 "63%" 62 "62%" 61 "61%" 60 "60%" 59 "59%" 58 "58%" 57 "57%" 56 "56%" 55 "55%" 54 "54%" 53 "53%" 52 "52%" 51 "51%" 50 "50%" 49 "49%" 48 "48%" 47 "47%" 46 "46%" 45 "45%" 44 "44%" 43 "43%" 42 "42%" 41 "41%" 40 "40%" 39 "39%" 38 "38%" 37 "37%" 36 "36%" 35 "35%" 34 "34%" 33 "33%" 32 "32%" 31 "31%" 30 "30%" 29 "29%" 28 "28%" 27 "27%" 26 "26%" 25 "25%" 24 "24%" 23 "23%" 22 "22%" 21 "21%" 20 "20%" 19 "19%" 18 "18%" 17 "17%" 16 "16%" 15 "15%" 14 "14%" 13 "13%" 12 "12%" 11 "11%" 10 "10%" 9 "9%" 8 "8%" 7 "7%" 6 "6%" 5 "5%" 4 "4%" 3 "3%" 2 "2%" 1 "1%" 0 "Not active" ;
VAL_ 1177 IHU_26_CenterLockSwt 3 " Reserved" 2 " LOCK" 1 " UNLOCK" 0 " Not Active" ;
VAL_ 1177 IHU_26_SeatLvlPosnCmd 15 "Reserved" 14 "Reserved" 13 "Reserved" 12 "Reserved" 11 "100%" 10 "90% " 9 "80% " 8 "70% " 7 "60% " 6 "50% " 5 "40% " 4 "30% " 3 "20% " 2 "10% " 1 "0% " 0 "Not active " ;
VAL_ 1177 IHU_26_SeatHdrestHeiAdjmtCmd 15 "Reserved" 14 "Reserved" 13 "Reserved" 12 "Reserved" 11 "Reserved" 10 "100%" 9 "90%" 8 "80%" 7 "70%" 6 "60%" 5 "50%" 4 "40%" 3 "30%" 2 "20%" 1 "10%" 0 "Not active" ;
VAL_ 1177 IHU_26_WinInhbSwt 1 " Active" 0 " Not active" ;
VAL_ 1177 IHU_26_ReWinDefrstSwt 1 " Active" 0 " Not active" ;
VAL_ 1177 IHU_26_SteerWhlHeatgSwt 1 " Active" 0 " Not active" ;
VAL_ 1177 IHU_26_BackrAgPosnCmd 31 "Reserved" 30 "Reserved" 29 "Reserved" 28 "Reserved" 27 "Reserved" 26 "Reserved" 25 "Reserved" 24 "Reserved" 23 "Reserved" 22 "Reserved" 21 "100%" 20 "95%" 19 "90%" 18 "85%" 17 "80%" 16 "75%" 15 "70%" 14 "65%" 13 "60%" 12 "55%" 11 "50%" 10 "45% " 9 "40% " 8 "35% " 7 "30% " 6 "25% " 5 "20% " 4 "15% " 3 "10% " 2 "5% " 1 "0% " 0 "Not active " ;
VAL_ 1177 IHU_26_SeatCushPosnCmd 15 "Reserved" 14 "Reserved" 13 "Reserved" 12 "Reserved" 11 "Reserved" 10 "100%" 9 "90%" 8 "80%" 7 "70%" 6 "60%" 5 "50%" 4 "40%" 3 "30%" 2 "20%" 1 "10%" 0 "Not active" ;
VAL_ 1177 IHU_26_SeatHeiPosnCmd 15 "Reserved" 14 "Reserved" 13 "Reserved" 12 "Reserved" 11 "100%" 10 "90% " 9 "80% " 8 "70% " 7 "60% " 6 "50% " 5 "40% " 4 "30% " 3 "20% " 2 "10% " 1 "0% " 0 "Not active " ;
VAL_ 643 IHU_25_APPsts 1 " Active" 0 " Not Active" ;
VAL_ 643 IHU_25_AmbLigFlngModSel 7 " mode7" 6 " mode6" 5 " mode5" 4 " mode4" 3 " mode3" 2 " mode2" 1 " mode1" 0 " Not Active" ;
VAL_ 643 IHU_25_AmbLig14FlngEna 1 " Active" 0 " Not Active" ;
VAL_ 643 IHU_25_AmbLig13FlngEna 1 " Active" 0 " Not Active" ;
VAL_ 643 IHU_25_AmbLig12FlngEna 1 " Active" 0 " Not Active" ;
VAL_ 643 IHU_25_AmbLig14FadeEna 1 " Active" 0 " Not Active" ;
VAL_ 643 IHU_25_AmbLig13FadeEna 1 " Active" 0 " Not Active" ;
VAL_ 643 IHU_25_AmbLig12FadeEna 1 " Active" 0 " Not Active" ;
VAL_ 643 IHU_25_AmbLig11FadeEna 1 " Active" 0 " Not Active" ;
VAL_ 643 IHU_25_AmbLig10FadeEna 1 " Active" 0 " Not Active" ;
VAL_ 643 IHU_25_AmbLig09FadeEna 1 " Active" 0 " Not Active" ;
VAL_ 643 IHU_25_AmbLig08FadeEna 1 " Active" 0 " Not Active" ;
VAL_ 643 IHU_25_AmbLig07FadeEna 1 " Active" 0 " Not Active" ;
VAL_ 643 IHU_25_AmbLig06FadeEna 1 " Active" 0 " Not Active" ;
VAL_ 643 IHU_25_AmbLig05FadeEna 1 " Active" 0 " Not Active" ;
VAL_ 643 IHU_25_AmbLig04FadeEna 1 " Active" 0 " Not Active" ;
VAL_ 643 IHU_25_AmbLig03FadeEna 1 " Active" 0 " Not Active" ;
VAL_ 643 IHU_25_AmbLig02FadeEna 1 " Active" 0 " Not Active" ;
VAL_ 643 IHU_25_AmbLig01FadeEna 1 " Active" 0 " Not Active" ;
VAL_ 643 IHU_25_AmbLig14Authn 1 " Active" 0 " Not Active" ;
VAL_ 643 IHU_25_AmbLig13Authn 1 " Active" 0 " Not Active" ;
VAL_ 643 IHU_25_AmbLig12Authn 1 " Active" 0 " Not Active" ;
VAL_ 643 IHU_25_AmbLig11Authn 1 " Active" 0 " Not Active" ;
VAL_ 643 IHU_25_AmbLig10Authn 1 " Active" 0 " Not Active" ;
VAL_ 643 IHU_25_AmbLig09Authn 1 " Active" 0 " Not Active" ;
VAL_ 643 IHU_25_AmbLig08Authn 1 " Active" 0 " Not Active" ;
VAL_ 643 IHU_25_AmbLig07Authn 1 " Active" 0 " Not Active" ;
VAL_ 643 IHU_25_AmbLig06Authn 1 " Active" 0 " Not Active" ;
VAL_ 643 IHU_25_AmbLig05Authn 1 " Active" 0 " Not Active" ;
VAL_ 643 IHU_25_AmbLig04Authn 1 " Active" 0 " Not Active" ;
VAL_ 643 IHU_25_AmbLig03Authn 1 " Active" 0 " Not Active" ;
VAL_ 643 IHU_25_AmbLig02Authn 1 " Active" 0 " Not Active" ;
VAL_ 643 IHU_25_AmbLig01Authn 1 " Active" 0 " Not Active" ;
VAL_ 1244 PassSeatMsgModeCmd 5 "Jump Mode" 4 "Relieve Mode" 3 "Cross Mode" 2 "Cat Paw Mode" 1 "Wave Mode" 0 "Not Active" ;
VAL_ 1244 PassSeatMsgStr_LvlCmd 4 "High" 3 "Middle" 2 "Low" 1 "OFF" 0 "NotActive" ;
VAL_ 1244 IHU_24_SetAdasDisp 3 "Reserved" 2 "Display " 1 "No Display" 0 "No Active" ;
VAL_ 1244 IHU_24_SetBlueToothDisp 3 "Reserved" 2 "Display " 1 "No Display" 0 "No Active" ;
VAL_ 1244 IHU_24_SetFaceIdOnoff 3 "Reserved" 2 "OFF" 1 "ON" 0 "No Active" ;
VAL_ 1244 IHU_24_SetAdasDispPoision 7 "Reserved" 6 "Reserved" 5 "Reserved" 4 "Invalid" 3 "Ignore" 2 "ADAS right" 1 "ADAS left" 0 "Not Active" ;
VAL_ 1244 IHU_24_SetNavDisp 3 "Reserved" 2 "Display " 1 "No Display" 0 "No Active" ;
VAL_ 1244 IHU_24_SetHudBri 15 "Ignore" 14 "Reserved" 13 "Reserved" 12 "Reserved" 11 "Reserved" 10 "Level10" 9 "Level9" 8 "Level8" 7 "Level7" 6 "Level6" 5 "Level5" 4 "Level4" 3 "Level3" 2 "Level2" 1 "Level1" 0 "Not Active" ;
VAL_ 1244 IHU_24_SetHudDispMod 3 "sport" 2 "snowy" 1 "normal" 0 "Not Active" ;
VAL_ 1244 IHU_24_SetHudHei 15 "Ignore" 14 "Reserved" 13 "Reserved" 12 "Reserved" 11 "Reserved" 10 "Level10" 9 "Level9" 8 "Level8" 7 "Level7" 6 "Level6" 5 "Level5" 4 "Level4" 3 "Level3" 2 "Level2" 1 "Level1" 0 "Not Active" ;
VAL_ 1244 IHU_24_SetHudDispOnOff 4 "Invalid" 3 "IgnoreAJ545:AJ549" 2 "ON" 1 "OFF" 0 "Not Active" ;
VAL_ 1035 IHU_OTAPwrMngt 7 " Reserved" 6 " Reserved" 5 " Reserved" 4 " Reserved" 3 " Continuous ON" 2 " Power On" 1 " Power Off" 0 " No Request" ;
VAL_ 1035 IHU_OTAHvReq 3 " Reserved" 2 " Reserved" 1 " Power Down" 0 " No Request" ;
VAL_ 1035 IHU_OTASts 3 " Reserved" 2 " Reserved" 1 " OTA Status" 0 " Normal Status" ;
VAL_ 1278 IHU_SHU1RSeatAutVentnCmd 3 " Reserved" 2 " OFF" 1 " ON" 0 " Not Active" ;
VAL_ 1278 IHU_SHU1LSeatAutVentnCmd 3 " Reserved" 2 " OFF" 1 " ON" 0 " Not Active" ;
VAL_ 1278 IHU_SHU1RSeatAutHeatCmd 3 " Reserved" 2 " OFF" 1 " ON" 0 " Not Active" ;
VAL_ 1278 IHU_SHU1LSeatAutHeatCmd 3 " Reserved" 2 " OFF" 1 " ON" 0 " Not Active" ;
VAL_ 1278 SHU3RSeatVentilationCmd 7 " Reserved" 6 " Reserved" 5 " Reserved" 4 " Seat Ventilation Level3" 3 " Seat Ventilation Level2" 2 " Seat Ventilation Level1" 1 " OFF" 0 " Not Active" ;
VAL_ 1278 SHU3LSeatVentilationCmd 7 " Reserved" 6 " Reserved" 5 " Reserved" 4 " Seat Ventilation Level3" 3 " Seat Ventilation Level2" 2 " Seat Ventilation Level1" 1 " OFF" 0 " Not Active" ;
VAL_ 1278 SHU3RSeatHeatLevelCmd 7 " Reserved" 6 " Reserved" 5 " Reserved" 4 " Seat heating Level3" 3 " Seat heating Level2" 2 " Seat heating Level1" 1 " OFF" 0 " Not Active" ;
VAL_ 1278 SHU3LSeatHeatLevelCmd 7 " Reserved" 6 " Reserved" 5 " Reserved" 4 " Seat heating Level3" 3 " Seat heating Level2" 2 " Seat heating Level1" 1 " OFF" 0 " Not Active" ;
VAL_ 1278 SHU2RSeatVentilationCmd 7 " Reserved" 6 " Reserved" 5 " Reserved" 4 " Seat Ventilation Level3" 3 " Seat Ventilation Level2" 2 " Seat Ventilation Level1" 1 " OFF" 0 " Not Active" ;
VAL_ 1278 SHU2MSeatVentilationCmd 7 " Reserved" 6 " Reserved" 5 " Reserved" 4 " Seat Ventilation Level3" 3 " Seat Ventilation Level2" 2 " Seat Ventilation Level1" 1 " OFF" 0 " Not Active" ;
VAL_ 1278 SHU2LSeatVentilationCmd 7 " Reserved" 6 " Reserved" 5 " Reserved" 4 " Seat Ventilation Level3" 3 " Seat Ventilation Level2" 2 " Seat Ventilation Level1" 1 " OFF" 0 " Not Active" ;
VAL_ 1278 SHU2RSeatHeatLevelCmd 7 " Reserved" 6 " Reserved" 5 " Reserved" 4 " Seat heating Level3" 3 " Seat heating Level2" 2 " Seat heating Level1" 1 " OFF" 0 " Not Active" ;
VAL_ 1278 SHU2MSeatHeatLevelCmd 7 " Reserved" 6 " Reserved" 5 " Reserved" 4 " Seat heating Level3" 3 " Seat heating Level2" 2 " Seat heating Level1" 1 " OFF" 0 " Not Active" ;
VAL_ 1278 SHU2LSeatHeatLevelCmd 7 " Reserved" 6 " Reserved" 5 " Reserved" 4 " Seat heating Level3" 3 " Seat heating Level2" 2 " Seat heating Level1" 1 " OFF" 0 " Not Active" ;
VAL_ 1278 SHU1RSeatVentilationCmd 7 " Reserved" 6 " Reserved" 5 " Reserved" 4 " Seat Ventilation Level3" 3 " Seat Ventilation Level2" 2 " Seat Ventilation Level1" 1 " OFF" 0 " Not Active" ;
VAL_ 1278 SHU1LSeatVentilationCmd 7 " Reserved" 6 " Reserved" 5 " Reserved" 4 " Seat Ventilation Level3" 3 " Seat Ventilation Level2" 2 " Seat Ventilation Level1" 1 " OFF" 0 " Not Active" ;
VAL_ 1278 SHU1RSeatHeatLevelCmd 7 " Reserved" 6 " Reserved" 5 " Reserved" 4 " Seat heating Level3" 3 " Seat heating Level2" 2 " Seat heating Level1" 1 " OFF" 0 " Not Active" ;
VAL_ 1278 SHU1LSeatHeatLevelCmd 7 " Reserved" 6 " Reserved" 5 " Reserved" 4 " Seat heating Level3" 3 " Seat heating Level2" 2 " Seat heating Level1" 1 " OFF" 0 " Not Active" ;
VAL_ 1119 IHU_19_Set_HdrestSpkrMod 7 "reserved" 6 "reserved " 5 "reserved" 4 "reserved" 3 "Private mode" 2 "Drive mode" 1 "Shared mode" 0 "Not Active" ;
VAL_ 1119 IHU_19_Set_AMPESEVol 63 " Reserved" 62 " Reserved" 61 " Reserved" 60 " Reserved" 59 " Reserved" 58 " Reserved" 57 " Reserved" 56 " Reserved" 55 " Reserved" 54 " Reserved" 53 " Reserved" 52 " Reserved" 51 " Reserved" 50 " Reserved" 49 " Reserved" 48 " Reserved" 41 " Reserved" 40 " Reserved" 39 " Reserved" 38 " Reserved" 37 " Reserved" 36 " Reserved" 35 " Reserved" 34 " Reserved" 33 " Reserved" 32 " 31" 31 " 30" 30 " 29" 29 " 28" 28 " 27" 27 " 26" 26 " 25" 25 " 24" 24 " 23" 23 " 22" 22 " 21" 21 " 20" 20 " 19" 19 " 18" 18 " 17" 17 " 16" 16 " 15" 15 " 14" 14 " 13" 13 " 12" 12 " 11" 11 " 10" 10 " 9" 9 " 8" 8 " 7" 7 " 6" 6 " 5" 5 " 4" 4 " 3" 3 " 2" 2 " 1" 1 " 0 " 0 " Not Active" ;
VAL_ 1119 IHU_19_Set_AMPWelVol 63 " Reserved" 62 " Reserved" 61 " Reserved" 60 " Reserved" 59 " Reserved" 58 " Reserved" 57 " Reserved" 56 " Reserved" 55 " Reserved" 54 " Reserved" 53 " Reserved" 52 " Reserved" 51 " Reserved" 50 " Reserved" 49 " Reserved" 48 " Reserved" 41 " Reserved" 40 " Reserved" 39 " Reserved" 38 " Reserved" 37 " Reserved" 36 " Reserved" 35 " Reserved" 34 " Reserved" 33 " Reserved" 32 " 31" 31 " 30" 30 " 29" 29 " 28" 28 " 27" 27 " 26" 26 " 25" 25 " 24" 24 " 23" 23 " 22" 22 " 21" 21 " 20" 20 " 19" 19 " 18" 18 " 17" 17 " 16" 16 " 15" 15 " 14" 14 " 13" 13 " 12" 12 " 11" 11 " 10" 10 " 9" 9 " 8" 8 " 7" 7 " 6" 6 " 5" 5 " 4" 4 " 3" 3 " 2" 2 " 1" 1 " 0 " 0 " Not Active" ;
VAL_ 1119 IHU_19_Set_AMPBTMediVol 63 " Reserved" 62 " Reserved" 61 " Reserved" 60 " Reserved" 59 " Reserved" 58 " Reserved" 57 " Reserved" 56 " Reserved" 55 " Reserved" 54 " Reserved" 53 " Reserved" 52 " Reserved" 51 " Reserved" 50 " Reserved" 49 " Reserved" 48 " Reserved" 41 " Reserved" 40 " Reserved" 39 " Reserved" 38 " Reserved" 37 " Reserved" 36 " Reserved" 35 " Reserved" 34 " Reserved" 33 " Reserved" 32 " 31" 31 " 30" 30 " 29" 29 " 28" 28 " 27" 27 " 26" 26 " 25" 25 " 24" 24 " 23" 23 " 22" 22 " 21" 21 " 20" 20 " 19" 19 " 18" 18 " 17" 17 " 16" 16 " 15" 15 " 14" 14 " 13" 13 " 12" 12 " 11" 11 " 10" 10 " 9" 9 " 8" 8 " 7" 7 " 6" 6 " 5" 5 " 4" 4 " 3" 3 " 2" 2 " 1" 1 " 0 " 0 " Not Active" ;
VAL_ 1119 IHU_19_REQ_AMPA2BMediSound 7 "reserved" 6 "reserved " 5 "reserved" 4 " OFF" 3 " Welcome" 2 " BT Media" 1 " Media" 0 " Not Active" ;
VAL_ 1119 IHU_19_REQ_AMPA2BESESound 3 " reserved" 2 " OFF" 1 " ON" 0 " Not Active" ;
VAL_ 1119 IHU_19_PABSetCmd 3 " Not Used" 2 " PAB ON Cmd           " 1 " PAB OFF Cmd" 0 " Not Active" ;
VAL_ 1119 IHU_19_HwSet 3 " Not Used" 2 " OFF                                   " 1 " ON" 0 " Not Active" ;
VAL_ 1119 IHU_19_BSRBPASet 3 " Not Used" 2 " OFF                                  " 1 " ON" 0 " Not Active" ;
VAL_ 1119 REQ_AMPA2BKeyTone 3 " reserved" 2 " OFF" 1 " ON" 0 " Not Active" ;
VAL_ 1119 REQ_AMPA2BTTSSound 3 " reserved" 2 " OFF" 1 " ON" 0 " Not Active" ;
VAL_ 1119 REQ_AMPA2BVRSound 3 " reserved" 2 " OFF" 1 " ON" 0 " Not Active" ;
VAL_ 1119 REQ_AMPA2BNaviSound 3 " reserved" 2 " OFF" 1 " ON" 0 " Not Active" ;
VAL_ 1119 IHU_19_Reserved_2 3 " reserved" 2 " OFF" 1 " ON" 0 " Not Active" ;
VAL_ 1119 Set_AMPMute 3 " reserved" 2 " OFF" 1 " ON" 0 " Not Active" ;
VAL_ 1119 Set_AMPSpeedVolume 7 " Reserved" 6 " Reserved" 5 " Reserved" 4 " High" 3 " Middle" 2 " Low" 1 " OFF" 0 " Not Active" ;
VAL_ 1119 REQ_AMPA2BPhoneSound 7 " Reserved" 6 " Reserved" 5 " Reserved" 4 " Reserved" 2 " Tbox Sound ON" 1 " BT PhoneSound ON" 0 "Not Active" ;
VAL_ 1100 Set_AMPAlarmVolume 15 " Reserved" 14 " Reserved" 13 " Reserved" 12 " Reserved" 11 " Reserved" 10 " 10" 9 " 9" 8 " 8" 7 " 7" 6 " 6" 5 " 5" 4 " 4" 3 " 3" 2 " 2" 1 " 1" 0 " Not Active" ;
VAL_ 1100 Set_AMPLoudness 3 " reserved" 2 " OFF" 1 " ON" 0 " Not Active" ;
VAL_ 1100 Set_AMPLiveAcoustics 3 " reserved" 2 " OFF" 1 " ON" 0 " Not Active" ;
VAL_ 1100 Set_AMPSoundFieldFader 15 " 7" 14 " 6" 13 " 5" 12 " 4" 11 " 3" 10 " 2" 9 " 1" 8 " 0" 7 " -1" 6 " -2" 5 " -3" 4 " -4" 3 " -5" 2 " -6" 1 " -7" 0 " Not Active" ;
VAL_ 1100 Set_AMPSoundFieldBalance 15 " 7" 14 " 6" 13 " 5" 12 " 4" 11 " 3" 10 " 2" 9 " 1" 8 " 0" 7 " -1" 6 " -2" 5 " -3" 4 " -4" 3 " -5" 2 " -6" 1 " -7" 0 " Not Active" ;
VAL_ 1100 Set_AMPSoundEffectTreble 15 " 7" 14 " 6" 13 " 5" 12 " 4" 11 " 3" 10 " 2" 9 " 1" 8 " 0" 7 " -1" 6 " -2" 5 " -3" 4 " -4" 3 " -5" 2 " -6" 1 " -7" 0 " Not Active" ;
VAL_ 1100 Set_AMPSoundEffectMidrange 15 " 7" 14 " 6" 13 " 5" 12 " 4" 11 " 3" 10 " 2" 9 " 1" 8 " 0" 7 " -1" 6 " -2" 5 " -3" 4 " -4" 3 " -5" 2 " -6" 1 " -7" 0 " Not Active" ;
VAL_ 1100 Set_AMPSoundEffectBass 15 " 7" 14 " 6" 13 " 5" 12 " 4" 11 " 3" 10 " 2" 9 " 1" 8 " 0" 7 " -1" 6 " -2" 5 " -3" 4 " -4" 3 " -5" 2 " -6" 1 " -7" 0 " Not Active" ;
VAL_ 1100 Set_AMPSoundEffect 15 " Reserved" 14 " Reserved" 13 " Reserved" 12 " Reserved" 11 " Reserved" 10 " Reserved" 9 "  Reserved" 8 " Rural model" 7 " Vocals mode" 6 " Rock mode" 5 " Classic mode" 4 " Jazz mode" 3 " Popular mode" 2 " Standard mode " 1 " Customer-defined mode" 0 " Not Active" ;
VAL_ 1100 Set_AMPRestoreDefaults 3 " Reserved" 2 " OFF" 1 " ON" 0 " Not Active" ;
VAL_ 1100 Set_AMPDefaultVolume 63 " Reserved" 62 " Reserved" 61 " Reserved" 60 " Reserved" 59 " Reserved" 58 " Reserved" 57 " Reserved" 56 " Reserved" 55 " Reserved" 54 " Reserved" 53 " Reserved" 52 " Reserved" 51 " Reserved" 50 " Reserved" 49 " Reserved" 48 " Reserved" 41 " Reserved" 40 " Reserved" 39 " Reserved" 38 " Reserved" 37 " Reserved" 36 " Reserved" 35 " Reserved" 34 " Reserved" 33 " Reserved" 32 " 31" 31 " 30" 30 " 29" 29 " 28" 28 " 27" 27 " 26" 26 " 25" 25 " 24" 24 " 23" 23 " 22" 22 " 21" 21 " 20" 20 " 19" 19 " 18" 18 " 17" 17 " 16" 16 " 15" 15 " 14" 14 " 13" 13 " 12" 12 " 11" 11 " 10" 10 " 9" 9 " 8" 8 " 7" 7 " 6" 6 " 5" 5 " 4" 4 " 3" 3 " 2" 2 " 1" 1 " 0 " 0 " Not Active" ;
VAL_ 1100 Set_AMPSoundFocus 0 " Not Active" ;
VAL_ 1100 Set_AMPPhoneVolume 31 " Reserved" 30 " Reserved" 29 " Reserved" 28 " Reserved" 27 " Reserved" 26 " 25" 25 " 24" 24 " 23" 23 " 22" 22 " 21" 21 " 20" 20 " 19" 19 " 18" 18 " 17" 17 " 16" 16 " 15" 15 " 14" 14 " 13" 13 " 12" 12 " 11" 11 " 10" 10 " 9" 9 " 8" 8 " 7" 7 " 6" 6 " 5" 5 " 4" 4 " 3" 3 " 2" 2 " 1" 1 " 0 " 0 " Not Active" ;
VAL_ 1100 Set_AMPMediaVolume 63 " Reserved" 62 " Reserved" 61 " Reserved" 60 " Reserved" 59 " Reserved" 58 " Reserved" 57 " Reserved" 56 " Reserved" 55 " Reserved" 54 " Reserved" 53 " Reserved" 52 " Reserved" 51 " Reserved" 50 " Reserved" 49 " Reserved" 48 " Reserved" 41 " Reserved" 40 " Reserved" 39 " Reserved" 38 " Reserved" 37 " Reserved" 36 " Reserved" 35 " Reserved" 34 " Reserved" 33 " Reserved" 32 " 31" 31 " 30" 30 " 29" 29 " 28" 28 " 27" 27 " 26" 26 " 25" 25 " 24" 24 " 23" 23 " 22" 22 " 21" 21 " 20" 20 " 19" 19 " 18" 18 " 17" 17 " 16" 16 " 15" 15 " 14" 14 " 13" 13 " 12" 12 " 11" 11 " 10" 10 " 9" 9 " 8" 8 " 7" 7 " 6" 6 " 5" 5 " 4" 4 " 3" 3 " 2" 2 " 1" 1 " 0 " 0 " Not Active" ;
VAL_ 1100 Set_AMPKeyTone 3 " reserved" 2 " OFF" 1 " ON" 0 " Not Active" ;
VAL_ 1100 Set_AMPVRVolume 15 " Reserved" 14 " Reserved" 13 " Reserved" 12 " Reserved" 11 " 10" 10 " 9" 9 " 8" 8 " 7" 7 " 6" 6 " 5" 5 " 4" 4 " 3" 3 " 2" 2 " 1" 1 " 0 " 0 " Not Active" ;
VAL_ 1100 Set_AMPNaviVolume 15 " Reserved" 14 " Reserved" 13 " Reserved" 12 " Reserved" 11 " 10" 10 " 9" 9 " 8" 8 " 7" 7 " 6" 6 " 5" 5 " 4" 4 " 3" 3 " 2" 2 " 1" 1 " 0 " 0 " Not Active" ;
VAL_ 1065 IHU_16_SetReRowPwrKeyCmd 1 " Active" 0 " Not Active" ;
VAL_ 1065 IHU_16_SetReRowBlowSpdLvlCmd 7 " Level  7" 6 " Level  6" 5 " Level  5" 4 " Level  4" 3 " Level  3" 2 " Level  2" 1 " Level  1" 0 " Not Active" ;
VAL_ 1065 IHU_16_SetReRowWorkCmd 1 " Active" 0 " Not Active" ;
VAL_ 1065 IHU_FragranceDisplayReq 3 " not used" 2 " close diaplay" 1 " open diaplay" 0 " not active" ;
VAL_ 1065 IHU_PM2_5AutoRunSet 3 " Not Used" 2 " Off" 1 " On" 0 " Not active" ;
VAL_ 1065 IHU_ANIONSwitch 3 " Not Used" 2 " Off" 1 " On" 0 " Not active" ;
VAL_ 1065 IHU_RefreshFunction 3 " Not Used" 2 " Off" 1 " On" 0 " Not active" ;
VAL_ 1065 IHU_ACModeCustom 7 " Not used" 6 " Not used" 5 " Not used" 4 " Not used" 3 " Strong   " 2 " Comfortable                                    " 1 " Save" 0 " Not Active" ;
VAL_ 1065 IHU_FragranCeconsistenceLevel 7 " Not used" 6 " Not used" 5 " Level5" 4 " Level4" 3 " Level3" 2 " Level2" 1 " Level1" 0 " Not Active     " ;
VAL_ 1065 IHU_FragranceSW 3 " Not Used" 2 " Off                                     " 1 " Auto " 0 " Not Active" ;
VAL_ 1065 IHU_16_SetSeBlowSpdLvlDisp 7 " Level  7" 6 " Level  6" 5 " Level  5" 4 " Level  4" 3 " Level  3" 2 " Level  2" 1 " Level  1" 0 " Not Active" ;
VAL_ 1065 IHU_16_SetSeWorking 1 " Active" 0 " Not Active" ;
VAL_ 1065 IHU_16_SeIntelligentCustom 1 " Active" 0 " Not Active" ;
VAL_ 1065 IHU_16_SetPtcHeatg 1 " Active" 0 " Not Active" ;
VAL_ 1065 IHU_FragranceWelcomeMode 3 " Not Used" 2 " Off                                     " 1 " On " 0 " Not Active" ;
VAL_ 1065 IHU_FragrancePosition 7 " Not used" 6 " Not used" 5 " Not used" 4 " Not used" 3 " Position three  " 2 " Position two                         " 1 " Position one" 0 " Not Active" ;
VAL_ 1065 IHU_AutoBlueCallBlowSpeed 3 " Not Used" 2 " Off                                     " 1 " On " 0 " Not Active" ;
VAL_ 1065 IHU_AutoParkInnerCirculation 3 " Not Used" 2 " Off                                     " 1 " On " 0 " Not Active" ;
VAL_ 1336 Weather_Type 63 " Reserved" 62 " Reserved" 61 " Reserved" 60 " Reserved" 59 " Reserved" 58 " Reserved" 57 " Reserved" 56 " Reserved" 55 " Reserved" 54 " Reserved" 53 " Reserved" 52 " Reserved" 51 " Reserved" 50 " Reserved" 49 " Reserved" 48 " Reserved" 47 " Reserved" 46 " Reserved" 45 " Reserved" 44 " Reserved" 43 " Reserved" 42 " Reserved" 41 " Reserved" 40 " Reserved" 39 " Reserved" 38 " Reserved" 37 " Reserved" 36 " Reserved" 35 " Reserved" 34 " Reserved" 33 " Haze" 32 " Reserved(Sandstorm)" 31 " Sand" 30 " Dust" 29 " Reserve(Heavy snow to snowstorm)" 28 " Reserved(Moderate to heavy snow)" 27 " Reserved(Light to moderate snow)" 26 " Reserved(Heavy to severe storm)" 25 " Reserved(Storm to heavy storm)" 24 " Reserved(Heavy rain to storm)" 23 " Reserved(Moderate to heavy rain)" 22 " Reserved(Light to moderate rain)" 21 " Duststorm" 20 " Reserved(Ice rain)" 19 " Foggy" 18 " Snowstorm" 17 " Heavy snow" 16 " Moderate snow" 15 " Light snow" 14 " Reserved(Snow flurry)" 13 " Reserved(Severe storm)" 12 " Reserved(Heavy storm)" 11 " Storm" 10 " Heavy rain" 9 " Moderate rain" 8 " Light rain" 7 " Sleet" 6 " Thundershower with hail" 5 " Thundershower" 4 " Shower" 3 " Overcast" 2 " Cloudy" 1 " Sunny" 0 " Reserved" ;
VAL_ 1112 MusicLoudness_6000HZ 31 " Invalid" 30 " Reserved" 29 " Reserved" 28 " Reserved" 27 " Reserved" 26 " Reserved" 25 " Reserved" 24 " Reserved" 23 " Reserved" 22 " Reserved" 21 " Reserved" 20 " Reserved" 19 " Reserved" 18 " Reserved" 17 " Reserved" 16 " Reserved" 15 " Level 16" 14 " Level 15" 13 " Level 14" 12 " Level 13" 11 " Level 12" 10 " Level 11" 9 " Level 10" 8 " Level 9" 7 " Level 8" 6 " Level 7" 5 " Level 6" 4 " Level 5" 3 " Level 4" 2 " Level 3" 1 " Level 2" 0 " Level 1" ;
VAL_ 1112 MusicLoudness_2000HZ 31 " Invalid" 30 " Reserved" 29 " Reserved" 28 " Reserved" 27 " Reserved" 26 " Reserved" 25 " Reserved" 24 " Reserved" 23 " Reserved" 22 " Reserved" 21 " Reserved" 20 " Reserved" 19 " Reserved" 18 " Reserved" 17 " Reserved" 16 " Reserved" 15 " Level 16" 14 " Level 15" 13 " Level 14" 12 " Level 13" 11 " Level 12" 10 " Level 11" 9 " Level 10" 8 " Level 9" 7 " Level 8" 6 " Level 7" 5 " Level 6" 4 " Level 5" 3 " Level 4" 2 " Level 3" 1 " Level 2" 0 " Level 1" ;
VAL_ 1112 MusicLoudness_1500HZ 31 " Invalid" 30 " Reserved" 29 " Reserved" 28 " Reserved" 27 " Reserved" 26 " Reserved" 25 " Reserved" 24 " Reserved" 23 " Reserved" 22 " Reserved" 21 " Reserved" 20 " Reserved" 19 " Reserved" 18 " Reserved" 17 " Reserved" 16 " Reserved" 15 " Level 16" 14 " Level 15" 13 " Level 14" 12 " Level 13" 11 " Level 12" 10 " Level 11" 9 " Level 10" 8 " Level 9" 7 " Level 8" 6 " Level 7" 5 " Level 6" 4 " Level 5" 3 " Level 4" 2 " Level 3" 1 " Level 2" 0 " Level 1" ;
VAL_ 1112 MusicShowCMD 1 " ON" 0 " OFF" ;
VAL_ 1112 MusicLoudness_1000HZ 31 " Invalid" 30 " Reserved" 29 " Reserved" 28 " Reserved" 27 " Reserved" 26 " Reserved" 25 " Reserved" 24 " Reserved" 23 " Reserved" 22 " Reserved" 21 " Reserved" 20 " Reserved" 19 " Reserved" 18 " Reserved" 17 " Reserved" 16 " Reserved" 15 " Level 16" 14 " Level 15" 13 " Level 14" 12 " Level 13" 11 " Level 12" 10 " Level 11" 9 " Level 10" 8 " Level 9" 7 " Level 8" 6 " Level 7" 5 " Level 6" 4 " Level 5" 3 " Level 4" 2 " Level 3" 1 " Level 2" 0 " Level 1" ;
VAL_ 1112 MusicLoudness_500HZ 31 " Invalid" 30 " Reserved" 29 " Reserved" 28 " Reserved" 27 " Reserved" 26 " Reserved" 25 " Reserved" 24 " Reserved" 23 " Reserved" 22 " Reserved" 21 " Reserved" 20 " Reserved" 19 " Reserved" 18 " Reserved" 17 " Reserved" 16 " Reserved" 15 " Level 16" 14 " Level 15" 13 " Level 14" 12 " Level 13" 11 " Level 12" 10 " Level 11" 9 " Level 10" 8 " Level 9" 7 " Level 8" 6 " Level 7" 5 " Level 6" 4 " Level 5" 3 " Level 4" 2 " Level 3" 1 " Level 2" 0 " Level 1" ;
VAL_ 1112 LiShowMod 6 " Mode5" 5 " Mode4" 4 " Mode3" 3 " Mode2" 2 " Mode1" 1 " OFF" 0 " NotActive" ;
VAL_ 1112 MusicLoudness_250HZ 31 " Invalid" 30 " Reserved" 29 " Reserved" 28 " Reserved" 27 " Reserved" 26 " Reserved" 25 " Reserved" 24 " Reserved" 23 " Reserved" 22 " Reserved" 21 " Reserved" 20 " Reserved" 19 " Reserved" 18 " Reserved" 17 " Reserved" 16 " Reserved" 15 " Level 16" 14 " Level 15" 13 " Level 14" 12 " Level 13" 11 " Level 12" 10 " Level 11" 9 " Level 10" 8 " Level 9" 7 " Level 8" 6 " Level 7" 5 " Level 6" 4 " Level 5" 3 " Level 4" 2 " Level 3" 1 " Level 2" 0 " Level 1" ;
VAL_ 1112 ADBenable 3 " Reserved" 2 " disenable" 1 " enable" 0 " Notactive" ;
VAL_ 1112 DVD_StandbyModeSts 1 " DVD is in StandbyMode" 0 " DVD is not in StandbyMode" ;
VAL_ 1112 MusicLoudness_120HZ 31 " Invalid" 30 " Reserved" 29 " Reserved" 28 " Reserved" 27 " Reserved" 26 " Reserved" 25 " Reserved" 24 " Reserved" 23 " Reserved" 22 " Reserved" 21 " Reserved" 20 " Reserved" 19 " Reserved" 18 " Reserved" 17 " Reserved" 16 " Reserved" 15 " Level 16" 14 " Level 15" 13 " Level 14" 12 " Level 13" 11 " Level 12" 10 " Level 11" 9 " Level 10" 8 " Level 9" 7 " Level 8" 6 " Level 7" 5 " Level 6" 4 " Level 5" 3 " Level 4" 2 " Level 3" 1 " Level 2" 0 " Level 1" ;
VAL_ 1114 MusicShowCMD 2 " ON" 1 " OFF" 0 " NotActive" ;
VAL_ 1114 LightShowCmd 6 " Mode5" 5 " Mode4" 4 " Mode3" 3 " Mode2" 2 " Mode1" 1 " OFF" 0 " NotActive" ;
VAL_ 1114 DVRSnapshot 1 " Active" 0 " Not active" ;
VAL_ 1114 AVMSwt 1 " Active" 0 " Not active" ;
VAL_ 1114 TouchEvt 3 " Lift up" 2 " Moving" 1 " Press down" 0 " Not active" ;
VAL_ 1114 LDWSensitivitySetting 3 " High" 2 " Middle" 1 " Low" 0 " Not active" ;
VAL_ 1114 IHU_APAKeySts 1 " Active" 0 " Not active" ;
VAL_ 1114 LDWSwitchSts 3 " Not Used" 2 " Off" 1 " On" 0 " Not active" ;
VAL_ 1114 IHU_12_DMSSwtSet 3 " Reserved" 2 " Turn off alarm    " 1 " Open alarm" 0 " Not Active" ;
VAL_ 1114 IHU_12_CarMdlSetColor 15 " Not used" 14 " Not used" 13 " Not used" 12 " Not used" 11 " Not used" 10 " Not used" 9 " Not used" 8 " Colour8" 7 " Colour7" 6 " Colour6" 5 " Colour5" 4 " Colour4" 3 " Colour3" 2 " Colour2" 1 " Colour1" 0 " Not active" ;
VAL_ 1114 CalibrationReq 1 " Active" 0 " Not active" ;
VAL_ 1114 RRMDisplayAVMOff 1 " Active" 0 " Not active" ;
VAL_ 1114 NaviBtnPressInputValueY 65535 " Not active" ;
VAL_ 1114 NaviBtnPressInputValueX 65535 " Not active" ;
VAL_ 1276 DVD_SET_EPS_Assistance_Style 3 " invalid" 2 " not active" 1 " Assistane light" 0 " Assistane heavy" ;
VAL_ 1276 DVD_SET_EPS_AssociWithDriverMode 3 " Not Used" 2 " ON" 1 " OFF" 0 " Not active" ;
VAL_ 1276 IHU_11_ELKSwtSet 3 " Not Used" 2 " OFF" 1 " ON" 0 " Not Active" ;
VAL_ 1276 IHU_11_LDWLDPSnvtySet 3 " Not Used" 2 " HIGH" 1 " LOW" 0 " Not Active" ;
VAL_ 1276 IHU_11_LDPSwtSet 3 " Not Used" 2 " OFF" 1 " ON" 0 " Not Active" ;
VAL_ 1276 IHU_11_WarnModSwtSet 3 " voice and shock" 2 " only shock " 1 " only voice" 0 " Not Active" ;
VAL_ 1276 IHU_11_LDWSwtSet 3 " Not Used" 2 " OFF" 1 " ON" 0 " Not Active" ;
VAL_ 1276 IHU_11_TLISwtSet 3 " Not Used" 2 " OFF" 1 " ON" 0 " Not Active" ;
VAL_ 1276 IHU_11_TSISwtSet 3 " Not Used" 2 " OFF" 1 " ON" 0 " Not Active" ;
VAL_ 1276 IHU_11_HMASwtSet 3 " Not Used" 2 " OFF" 1 " ON" 0 " Not Active" ;
VAL_ 1276 IHU_11_IESSwtSet 3 " Not Used" 2 " OFF" 1 " ON" 0 " Not Active" ;
VAL_ 1276 IHU_11_DAISwtSet 3 " Not Used" 2 " OFF" 1 " ON" 0 " Not Active" ;
VAL_ 1276 IHU_11_SCFSwtSet 3 " Not Used" 2 " OFF" 1 " ON" 0 " Not Active" ;
VAL_ 1276 IHU_11_SLASwtSet 3 " Not Used" 2 " OFF" 1 " ON" 0 " Not Active" ;
VAL_ 1276 IHU_11_TJAICAExitTextInfoSwtSet 3 " Not Used" 2 " OFF" 1 " ON" 0 " Not Active" ;
VAL_ 1276 IHU_11_FCWSwtSet 3 " Not Used" 2 " OFF" 1 " ON" 0 " Not Active" ;
VAL_ 1276 IHU_11_FCWSnvtySet 3 " far" 2 " near" 1 " standard" 0 " Not Active" ;
VAL_ 1276 IHU_11_AEBSwtSet 3 " Not Used" 2 " OFF" 1 " ON" 0 " Not Active" ;
VAL_ 1276 IHU_11_RCTBSwtSet 3 " Not Used" 2 " OFF" 1 " ON" 0 " Not Active" ;
VAL_ 1276 IHU_11_RAEBSwtSet 3 " Not Used" 2 " OFF" 1 " ON" 0 " Not Active" ;
VAL_ 1276 IHU_11_BSDSwitchSts 3 " Not Used" 2 " OFF" 1 " ON" 0 " Not Active" ;
VAL_ 1276 DVD_SET_RCW 3 " Not Used" 2 " OFF" 1 " ON" 0 " Not Active" ;
VAL_ 1276 DVD_SET_DOW 3 " Not Used" 2 " OFF" 1 " ON" 0 " Not Active" ;
VAL_ 1276 DVD_SET_CWC_PhoneforgottenFunSts 3 " Invalid" 2 " ON" 1 " OFF" 0 " Not active" ;
VAL_ 1276 ModeKeySts 1 " Active" 0 " Not active" ;
VAL_ 1276 DVD_SET_ModeKeyFunctionType 3 " Not Used" 2 " Snapshot" 1 " Source Switching" 0 " Not active" ;
VAL_ 1276 DVD_SET_CWC_WorkingSts 3 " Invalid" 2 " ON" 1 " OFF" 0 " Not active" ;
VAL_ 1335 LightShowMod 6 " Mode5" 5 " Mode4" 4 " Mode3" 3 " Mode2" 2 " Mode1" 1 " OFF" 0 "Not Avtive" ;
VAL_ 1335 Reserved_IHU_10_TrackMod 1 " ON" 0 " OFF                                   " ;
VAL_ 1335 IHU_10_MirrorSet 1 " ON" 0 " OFF" ;
VAL_ 1335 IHU_10_ISSFctCmd 1 " ON" 0 " OFF" ;
VAL_ 1335 Set_HUDSteerpan 1 " Open" 0 " Close" ;
VAL_ 1335 IHU_DriveMode 7 " SAND" 6 " Not display" 5 " Offroad" 4 " MUD" 3 " SNOW" 2 " SPORT" 1 " NORMAL" 0 " ECO" ;
VAL_ 1335 NavCurrRoadType 10 " Nonaviway" 9 " Commonway" 8 " Minorway" 7 " Mainway" 6 " Expressway" 5 " CountyandTownlway" 4 " Townway" 3 " Countylway" 2 " Provincialway" 1 " Nationalway" 0 " Highway" ;
VAL_ 1335 NavSpeedLimitUnits 3 " Reserved" 2 " KMH" 1 " MPH" 0 " Unknown" ;
VAL_ 1335 NavSpeedLimit 63 " Reserved" 62 " Reserved" 61 " Reserved" 60 " Reserved" 59 " Reserved" 58 " Reserved" 57 " Reserved" 56 " Reserved" 55 " Reserved" 54 " Reserved" 53 " Reserved" 52 " Reserved" 51 " Reserved" 50 " Reserved" 49 " Reserved" 48 " Reserved" 47 " Reserved" 46 " Reserved" 45 " Reserved" 44 " Reserved" 43 " Reserved" 42 " Reserved" 41 " Reserved" 40 " Reserved" 39 " Reserved" 38 " Reserved" 37 " Reserved" 36 " Reserved" 35 " Reserved" 34 " Reserved" 33 " Reserved" 32 " Reserved" 31 " Reserved" 30 " Reserved" 29 " Reserved" 28 " Reserved" 27 " Reserved" 26 " SPL 130" 25 " SPL 125" 24 " SPL 120" 23 " SPL 115" 22 " SPL 110" 21 " SPL 105" 20 " SPL 100" 19 " SPL 95" 18 " SPL 90" 17 " SPL 85" 16 " SPL 80" 15 " SPL 75" 14 " SPL 70" 13 " SPL 65" 12 " SPL 60" 11 " SPL 55" 10 " SPL 50" 9 " SPL 45" 8 " SPL 40" 7 " SPL 35" 6 " SPL 30" 5 " SPL 25" 4 " SPL 20" 3 " SPL 15" 2 " SPL 10" 1 " SPL 5" 0 " No Display" ;
VAL_ 1335 NavSpeedLimitStatus 3 " SL_PLURAL" 2 " SL_NOLIMIT" 1 " SL_EXISTS" 0 " SL_UNKNOWN" ;
VAL_ 1273 IHU_SET_AIPMBrightnessLevel 15 " Not Used" 14 " Not Used                                                         " 13 " Not Used                                                            " 12 " Not Used                                                        " 11 " Not Used                                                       " 10 " Level  10                                                     " 9 " Level  9                                                       " 8 " Level  8                                                        " 7 " Level  7                                                        " 6 " Level  6                                                          " 5 " Level  5                                                      " 4 " Level  4                                                     " 3 " Level  3                                                       " 2 " Level  2                                                         " 1 " Level  1                                                     " 0 " Not active                                                 " ;
VAL_ 1273 DVD_SetLightedRoofRackStatus 3 " Reserved" 2 " ON" 1 " OFF" 0 " Not Active" ;
VAL_ 1273 DrvrDoorUnlckOnlyStsSet 3 " Not used" 2 " Not DriveDoorUnlockOnly  mode" 1 " DriveDoorUnlockOnly  mode" 0 " Not active" ;
VAL_ 1273 BlowSpeedLevelKeySts 15 " Level 15" 14 " Level 14              " 13 " Level 13" 12 " Level 12" 11 " Level 11" 10 " Level 10" 9 " Level  9" 8 " Level  8" 7 " Level  7" 6 " Level  6" 5 " Level  5" 4 " Level  4" 3 " Level  3" 2 " Level  2" 1 " Level  1 " 0 " Not active " ;
VAL_ 1273 IHU_SetTheaterDimmingColor_64 64 " Number 64" 63 " Number 63" 62 " Number 62" 61 " Number 61" 60 " Number 60" 59 " Number 59" 58 " Number 58" 57 " Number 57" 56 " Number 56" 55 " Number 55" 54 " Number 54" 53 " Number 53" 52 " Number 52" 51 " Number 51" 50 " Number 50" 49 " Number 49" 48 " Number 48" 47 " Number 47" 46 " Number 46" 45 " Number 45" 44 " Number 44" 43 " Number 43" 42 " Number 42" 41 " Number 41" 40 " Number 40" 39 " Number 39" 38 " Number 38" 37 " Number 37" 36 " Number 36" 35 " Number 35" 34 " Number 34" 33 " Number 33" 32 " Number 32" 31 " Number 31" 30 " Number 30" 29 " Number 29" 28 " Number 28" 27 " Number 27" 26 " Number 26" 25 " Number 25" 24 " Number 24" 23 " Number 23" 22 " Number 22" 21 " Number 21" 20 " Number 20" 19 " Number 19" 18 " Number 18" 17 " Number 17" 16 " Number 16" 15 " Number 15" 14 " Number 14" 13 " Number 13" 12 " Number 12" 11 " Number 11" 10 " Number 10" 9 " Number 9" 8 " Number 8" 7 " Number 7" 6 " Number 6" 5 " Number 5" 4 " Number 4" 3 " Number 3(Sport)" 2 " Number 2(Normal)" 1 " Number 1(ECO)" 0 " Not Active" ;
VAL_ 1273 IHU_9_FrntRadarSwt 1 " Active" 0 " Not Active" ;
VAL_ 1273 IHU_DriverSeatHeatLevelCmd 3 " Seat heating Level2" 2 " Seat heating Level1" 1 " OFF" 0 " Not Active" ;
VAL_ 1273 DVD_SET_BLTKey_PESts 3 " Not Used" 2 " OFF" 1 " ON" 0 " Not Active" ;
VAL_ 1273 FaceID 7 " Not Used" 6 " Not Used" 5 " ID5" 4 " ID4" 3 " ID3" 2 " ID2" 1 " ID1" 0 " Not active" ;
VAL_ 1273 Delete_ID_Info 7 " Not Used" 6 " Set_All_Personalization_to_default" 5 " Set_ID5_Personalization_to_default" 4 " Set_ID4_Personalization_to_default" 3 " Set_ID3_Personalization_to_default" 2 " Set_ID2_Personalization_to_default" 1 " Set_ID1_Personalization_to_default" 0 " Not active" ;
VAL_ 1273 DVD_SET_AutoFoldSts 3 " Not used" 2 " Not autofold mode" 1 " Autofold mode" 0 " Not active" ;
VAL_ 1273 IHU_DriverSeatVentilationKeySts 3 " Seat Ventilation Level2" 2 " Seat Ventilation Level1" 1 " OFF" 0 " Not Active" ;
VAL_ 1273 DVD_SET_HeadlampHeightSts 7 " Not Used" 6 " Not Used" 5 " Not Used" 4 " Level 3" 3 " Level 2" 2 " Level 1" 1 " Level 0" 0 " Not active" ;
VAL_ 1273 Reserved_SASSwitchStatus 3 " Not used" 2 " Off" 1 " Auto Active" 0 " Manual Active" ;
VAL_ 1273 Reserved_DVD_SET_RemoteTrunkOnly 3 " Not Used" 2 " Not Remote Trunk Only" 1 " Remote Trunk Only" 0 " Not active" ;
VAL_ 1273 Reserved_DVD_SET_UrgeBrakemode 3 " Not used" 2 " Hazard Lamp Not For Urgency Brake mode" 1 " Hazard Lamp For Urgency Brake  mode" 0 " Not active" ;
VAL_ 1273 Reserved_DVD_SET_AidTurnIlumin 3 " Not Used" 2 " Not Aid Turning Illumination mode" 1 " Aid Turning illumination mode" 0 " Not active" ;
VAL_ 1273 DVD_SET_DRLModeSts 3 " Not Used" 2 " Close DRL  mode" 1 " Open DRL mode" 0 " Not active" ;
VAL_ 1273 DVD_SET_HeadlampDelayLightSts 3 " Not Used" 2 " Not delay mode" 1 " Delay mode" 0 " Not active  " ;
VAL_ 1273 DVD_SET_RemoteLockFeedback 7 " Not Used" 6 " Not Used" 5 " Not Used" 4 " Not Used" 3 " Only speaker(Reserved)" 2 " Only lamp" 1 " Lamp and speaker" 0 " Not active" ;
VAL_ 1273 IHU_ISS_Switch 1 " Active" 0 " Not Active" ;
VAL_ 1273 DVD_SET_AutolockSts 3 " Not Used" 2 " Not autolock mode" 1 " Autolock mode" 0 " Not active" ;
VAL_ 1273 Reserved_DVD_SET_AutoUnlockSts 3 " Not Used" 2 " Not auto unlock mode" 1 " Auto unlock mode" 0 " Not active" ;
VAL_ 1272 DVD_Set_FGHeatSts 3 " Reserved" 2 " OFF                          " 1 " ON                   " 0 " Not Active" ;
VAL_ 1272 IHU_WindowCmd 31 " Not used" 30 " Not used" 29 " Not used" 28 " Not used" 27 " Not used" 26 " Not used" 25 " Not used" 24 " Not used" 23 " Not used" 22 " Not used" 21 " Not used" 20 " Not used" 19 " Not used" 18 " Not used" 17 " Not used" 16 " Not used" 15 " All  Windows comfort" 14 " All  Windows close" 13 " All Windows open" 12 " Rear Windows close" 11 " Rear Windows open" 10 " Front Windows close" 9 " Front Windows open" 8 " RRWindow close" 7 " RRWindow open" 6 " RLWindow close" 5 " RLWindow open" 4 " FRWindow close" 3 " FRWindow open" 2 " FLWindow close" 1 " FLWindow open" 0 " Not active" ;
VAL_ 1272 Set_Default 7 " Not Used" 6 " Not Used" 5 " Not Used" 4 " Not Used" 3 " Set_HUD_to_default" 2 " Set_All_to_default" 1 " Set_Personalization_to_default" 0 " Not active" ;
VAL_ 1272 Seat_ExtMirror_PosStoreReq_ID 31 " Not used" 30 " Not used" 29 " Not used" 28 " Not used" 27 " Not used" 26 " Not used" 25 " Not used" 24 " Not used" 23 " Not used" 22 " Not used" 21 " Not used" 20 " Not used" 19 " Not used" 18 " Not used" 17 " Not used" 16 " Not used" 15 " seat_ExtMirror_Pos2_StoreReq_ID5" 14 " seat_ExtMirror_Pos1_StoreReq_ID5" 13 " seat_ExtMirror_Pos0_StoreReq_ID5" 12 " seat_ExtMirror_Pos2_StoreReq_ID4" 11 " seat_ExtMirror_Pos1_StoreReq_ID4" 10 " seat_ExtMirror_Pos0_StoreReq_ID4" 9 " seat_ExtMirror_Pos2_StoreReq_ID3" 8 " seat_ExtMirror_Pos1_StoreReq_ ID3" 7 " seat_ExtMirror_Pos0_StoreReq_ID3" 6 " seat_ExtMirror_Pos2_StoreReq_ID2" 5 " seat_ExtMirror_Pos1_StoreReq_ID2" 4 " seat_ExtMirror_Pos0_StoreReq_ID2" 3 " seat_ExtMirror_Pos2_StoreReq_ID1" 2 " seat_ExtMirror_Pos1_StoreReq_ID1" 1 " seat_ExtMirror_Pos0_StoreReq_ID1" 0 " Not Active" ;
VAL_ 1272 Seat_ExtMirror_PosRecall_ID 31 " Not used" 30 " Not used" 29 " Not used" 28 " Not used" 27 " Not used" 26 " Not used" 25 " Not used" 24 " Not used" 23 " Not used" 22 " Not used" 21 " Not used" 20 " Not used" 19 " Not used" 18 " Not used" 17 " Not used" 16 " Not used" 15 " seat_ExtMirror_Pos2_Recall_ID5" 14 " seat_ExtMirror_Pos1_Recall_ID5" 13 " seat_ExtMirror_Pos0_Recall_ID5" 12 " seat_ExtMirror_Pos2_Recall_ID4" 11 " seat_ExtMirror_Pos1_Recall_ID4" 10 " seat_ExtMirror_Pos0_Recall_ID4" 9 " seat_ExtMirror_Pos2_Recall_ID3" 8 " seat_ExtMirror_Pos1_Recall_ID3" 7 " seat_ExtMirror_Pos0_Recall_ID3" 6 " seat_ExtMirror_Pos2_Recall_ID2" 5 " seat_ExtMirror_Pos1_Recall_ID2" 4 " seat_ExtMirror_Pos0_Recall_ID2" 3 " seat_ExtMirror_Pos2_Recall_ID1" 2 " seat_ExtMirror_Pos1_Recall_ID1" 1 " seat_ExtMirror_Pos0_Recall_ID1" 0 " Not Active" ;
VAL_ 1272 DVD_Set_ReverseExtMirrorSts 7 " Not Used" 6 " Not Used" 5 " Not Used" 4 " Both sides" 3 " Only left side" 2 " Only right side" 1 " OFF" 0 " Not active" ;
VAL_ 1272 DVD_Set_EasyEntrySts 3 " Not Used" 2 " ON" 1 " OFF" 0 " Not active" ;
VAL_ 1272 DVD_SetSCURelateKeyOrFaceID 3 " Not Used" 2 " Relate                   " 1 " Not Relate" 0 " Not Active" ;
VAL_ 1272 DVD_SetAssociatedWithMusicMode 3 " Reserved" 2 " OFF                          " 1 " ON                   " 0 " Not Active" ;
VAL_ 1272 DVD_SetAssociatedWithDriverMode 3 " Reserved" 2 " OFF                          " 1 " ON                   " 0 " Not Active" ;
VAL_ 1272 DVD_SetTheaterDimmingBrightness 7 " Reserved" 6 " Reserved" 5 " Level 5" 4 " Level 4" 3 " Level 3" 2 " Level 2" 1 " Level 1                  " 0 " Not Active" ;
VAL_ 1272 SetTheaterDimmingColor 7 " Purple" 6 " Blue" 5 " Cyan" 4 " Green" 3 " Yellow" 2 " Orange" 1 " Red                   " 0 " Not Active" ;
VAL_ 1272 DVD_SetTheaterDimmingStatus 3 " Reserved" 2 " OFF                          " 1 " ON                   " 0 " Not Active" ;
VAL_ 1272 Reserved_Set_MFS_Stuck_Duration 7 " invalid" 6 " Reserved" 5 " Reserved" 4 " level 4(120s)" 3 " level 3(90s)" 2 " level 2(60s)" 1 " level 1(30s)" 0 " Not active" ;
VAL_ 1272 Set_WelLightPolling 3 " Reserved" 2 " Close                            " 1 " Open                   " 0 " Not Active" ;
VAL_ 1272 Set_PEPS_IntelligentOpen 3 " Reserved" 2 " Close                            " 1 " Open                   " 0 " Not Active" ;
VAL_ 1272 Set_PEPS_Polling 3 " Reserved" 2 " Close                            " 1 " Open                   " 0 " Not Active" ;
VAL_ 1272 IHU_8_SunshadeCmd 3 " Half Open" 2 " Close                               " 1 " Open            " 0 " Not Active" ;
VAL_ 1272 IHU_PSRFCmd 15 " Reserved" 14 " Reserved" 13 " Reserved" 12 " Tilt" 11 " 100%" 10 " 90%" 9 " 80%" 8 " 70%" 7 " 60%" 6 " 50%" 5 " 40%" 4 " 30%" 3 " 20%" 2 " 10%" 1 " 0" 0 " Not Acitive" ;
VAL_ 1272 IHU_SRFCmd 7 " Reserved" 6 " Reserved" 5 " Reserved" 4 " Reserved" 3 " Tilt  " 2 " Close                            " 1 " Open                   " 0 " Not Active" ;
VAL_ 1309 LDWOnOffReq 3 " reserved" 2 " Not active" 1 " on" 0 " off" ;
VAL_ 1309 TimeGapLastSetReq 3 " Reserved" 2 " Not Active" 1 " On" 0 " Off" ;
VAL_ 1309 LDW_LKA_SensitivityReq 3 " reserved" 2 " Not active" 1 " highSensitivity" 0 " lowSensitivity" ;
VAL_ 1309 IHU_7_DrvAssiStyle 3 " self-defined" 2 " Old Driver" 1 " New Driver" 0 " Not active" ;
VAL_ 1309 IHU_7_DCLCONOFF 3 " Not Used" 2 " OFF" 1 " ON" 0 " Not Active" ;
VAL_ 1309 HMAOnOffReq 3 " Reserved" 2 " Not active" 1 " HMA selected" 0 " HMA not selected" ;
VAL_ 1309 IHU_AutHldSet 3 " Not Used" 2 " Off                                     " 1 " On " 0 " Not Active" ;
VAL_ 1309 SCF_ON_OFF 3 " Not Used" 2 " Off                                     " 1 " On " 0 " Not Active" ;
VAL_ 1309 SLAOnOffReq 3 " reserved" 2 " Not active" 1 " on" 0 " off" ;
VAL_ 1309 Set_ESPFunctionSts 3 " Not Used" 2 " OFF" 1 " ON" 0 " Not active" ;
VAL_ 1309 TIHU_SetHDCOnOff 3 " Not Used" 2 " OFF" 1 " ON" 0 " Not Active" ;
VAL_ 1309 CST_SensitivityReq 3 " Reserved" 2 " highSensitivity" 1 " lowSensitivity" 0 " Not active" ;
VAL_ 1309 BrakepedalfeelModeSetReq 3 " Reserved" 2 " Sport" 1 " Comfort" 0 " Not active" ;
VAL_ 1309 IHU_AssociateDriveModeSet 3 " Reserved" 2 " OFF" 1 " ON" 0 " Not active" ;
VAL_ 1309 Set_CSTFunctionSts 3 " Reserved" 2 " CST OFF" 1 " CST ON" 0 " Not active" ;
VAL_ 1309 DistanceWarning_on_off 3 " reserved" 2 " switch on" 1 " switch off" 0 " Not active" ;
VAL_ 1309 TJA_ICA_ON_OFF 3 " reserved" 2 " switch on" 1 " switch off" 0 " Not active" ;
VAL_ 1309 AEB_ON_OFF 3 " reserved" 2 " switch on" 1 " switch off" 0 " Not active" ;
VAL_ 1309 FCW_OPTION 3 " far" 2 " near " 1 " standard" 0 " Not active" ;
VAL_ 1309 FCW_ON_OFF 3 " reserved" 2 " switch on" 1 " switch off" 0 " Not active" ;
VAL_ 1309 TimeGapSet1Req 7 " reserved" 6 " reserved" 5 " reserved" 4 " reserved" 3 " tauGap_2" 2 " tauGap_1" 1 " tauGap_0" 0 " Not active" ;
VAL_ 1074 IHU_6_TouchEvt 3 " Lift up" 2 " Moving" 1 " Press down" 0 " Not active" ;
VAL_ 1074 IHU_6_TrajectorySetting 7 " Not Used" 6 " Not Used" 5 " Not Used" 4 " Not Used" 3 " StaticTrajectoryOn" 2 " BothOn" 1 " Off" 0 " Not active" ;
VAL_ 1074 IHU_6_LDWSwitchSts 3 " Not Used" 2 " Off" 1 " On" 0 " Not active" ;
VAL_ 1074 IHU_6_AVM3DAroundViewSW 3 " Not Used" 2 " Off" 1 " On" 0 " Not active" ;
VAL_ 1074 IHU_6_SideViewSW 3 " Not Used" 2 " Off       " 1 " On" 0 " Not active" ;
VAL_ 1074 IHU_6_CalibrationReq 1 " Active" 0 " Not active" ;
VAL_ 1074 IHU_6_RRMDisplayAVMOff 1 " Active" 0 " Not active" ;
VAL_ 1074 IHU_6_NaviBtnPressInputValueY 65535 " Not active" ;
VAL_ 1074 IHU_6_NaviBtnPressInputValueX 65535 " Not active" ;
VAL_ 1305 AUTODefrostOnKeySts 3 " Not Used" 2 " On" 1 " Off" 0 " Not Active" ;
VAL_ 1305 PM2_5DisplayReq 3 " not used" 2 " close diaplay" 1 " open diaplay" 0 " not active" ;
VAL_ 1305 DVD_SET_PM2_5Sts 3 " Not used" 2 " Not PM2.5 mode" 1 " PM2.5 mode" 0 " Not active" ;
VAL_ 1305 BlowDelayOffKeySts 3 " Not Used" 2 " Off                                     " 1 " On" 0 " Not Active" ;
VAL_ 1305 BlowAdvanceOnKeySts 3 " Not Used" 2 " Off                                     " 1 " On " 0 " Not Active" ;
VAL_ 1305 ElecClimateSetTemp 31 " Not Used" 30 " Not Used" 29 " Not Used" 28 " Not Used" 27 " Not Used" 26 " Not Used" 25 " Not Used" 24 " Not Used" 23 " Not Used" 22 " Not Used" 21 " Not Used" 20 " Not Used" 19 " Not Used" 18 " Not Used" 17 " Not Used" 16 " 16" 15 " 15" 14 " 14" 13 " 13" 12 " 12" 11 " 11" 10 " 10" 9 " 9" 8 " 8" 7 " 7" 6 " 6  " 5 " 5" 4 " 4" 3 " 3" 2 " 2" 1 " 1" 0 " Not active" ;
VAL_ 1305 SetTemperature_R_F 31 " Not active" ;
VAL_ 1305 SetTemperature_L_F 31 " Not active" ;
VAL_ 1305 DVD_ZoneSelectionKeySts 3 " Not Used" 2 " Dual zone mode                                  " 1 " Single zone mode" 0 " Not Active" ;
VAL_ 1305 DVD_SetCirculationModeKeySts 3 " Not Used" 2 " Air circulation mode                                " 1 " Recirculation mode" 0 " Not Active" ;
VAL_ 1305 SetTemperature_R_C 31 " Not active" ;
VAL_ 1305 SetTemperature_L_C 31 " Not active" ;
VAL_ 1305 Set_TimeAMPM 3 " Reserved" 2 " PM                              " 1 " AM" 0 " Not Active" ;
VAL_ 1305 ModeAdjustKeySts 7 " Not Active" 6 " BlowFace &BlowFoot& Defrost" 5 " BlowFace & Defrost" 4 " Defrost" 3 " BlowFoot & Defrost" 2 " BlowFoot " 1 " BlowFace & BlowFoot" 0 " BlowFace" ;
VAL_ 1305 Reserved_DVD_SetAC_MaxKeySts 3 " Not Used" 2 " Off                                     " 1 " On " 0 " Not Active" ;
VAL_ 1305 DVD_SetTemperatureUnit 3 " Not Used" 2 "  Fahrenheit(℉)                                     " 1 " Centigrade(℃)" 0 " Not Active" ;
VAL_ 1305 DVD_SetMaxFrontDeforestSts 3 " Not Used" 2 " Off                                     " 1 " On " 0 " Not Active" ;
VAL_ 1305 BlowSpeedLevelKeySts 7 " Level  7" 6 " Level  6" 5 " Level  5" 4 " Level  4" 3 " Level  3" 2 " Level  2" 1 " Level  1 " 0 " Not active " ;
VAL_ 1305 DVD_SetAutoKeySts 3 " Not Used" 2 " Off                                     " 1 " On " 0 " Not Active" ;
VAL_ 1305 DVD_SetACRequestKeySts 3 " Not Used" 2 " Off                                     " 1 " On " 0 " Not Active" ;
VAL_ 1305 DVD_SetCLMOn 3 " Not Used" 2 " Off                                     " 1 " On " 0 " Not Active" ;
VAL_ 1305 Set_Time24H12H 3 " Reserved" 2 " 12h                                " 1 " 24h" 0 " Not Active" ;
VAL_ 1305 IHU_4_CVBOXRstReq 1 " Request" 0 " No Request" ;
VAL_ 1303 DVD_SetThemeType 7 " Not used" 6 " Not used" 5 " Not used" 4 " Not used" 3 " Theme 3" 2 " Theme 2" 1 " Theme 1" 0 " Not active    " ;
VAL_ 1303 IHU_LDWLKA_LaneAssitTypeReq 3 " OFF" 2 " LKA" 1 " LDW" 0 " Not active" ;
VAL_ 1303 TimeSetYear 127 " Not active" ;
VAL_ 1303 TimeSetMonth 0 " Not active" ;
VAL_ 1303 TimeSetDay 0 " Not active" ;
VAL_ 1303 DVD_TrunkCmd 3 " Not used" 2 " Close" 1 " Open" 0 " Not Active                                                     " ;
VAL_ 1303 TimeSetSecond 63 " Not active" ;
VAL_ 1303 IHU_SET_ICMBrightnessLevel 15 " Not Used" 14 " Not Used                                                         " 13 " Not Used                                                            " 12 " Not Used                                                        " 11 " Not Used                                                       " 10 " Level  10                                                     " 9 " Level  9                                                       " 8 " Level  8                                                        " 7 " Level  7                                                        " 6 " Level  6                                                          " 5 " Level  5                                                      " 4 " Level  4                                                     " 3 " Level  3                                                       " 2 " Level  2                                                         " 1 " Level  1                                                     " 0 " Not active                                                 " ;
VAL_ 1303 FatigureDrivingTime 15 " Not Used" 14 " Not Used                                                   " 13 " Not Used                                                     " 12 " Not Used                                                     " 11 " Not Used                                                      " 10 " Not Used                                                       " 9 " Open                                                 " 8 " 4 hour                                                        " 7 " 3.5 hour                                                         " 6 " 3 hour                                                          " 5 " 2.5 hour                                                       " 4 " 2 hour                                                        " 3 " 1.5 hour                                                       " 2 " 1 hour                                                         " 1 " Cancel                                                       " 0 " Not active                                                  " ;
VAL_ 1303 TimeSetMinute 255 " Not active" ;
VAL_ 1303 TimeSetHour 255 " Not active" ;
VAL_ 1302 ClimateDisplayReq 3 " Not used" 2 " Closed Menu                                                 " 1 " Open Menu                                                  " 0 " Not active                                         " ;
VAL_ 1302 CarAngle 511 " No angle information" 0 " No display" ;
VAL_ 1302 BltCallSts 1 " Active" 0 " Not Active" ;
VAL_ 1302 PanelKeyVoiceSource 1 " DVD" 0 " IPM                                      " ;
VAL_ 1302 RadioVolume 0 " Not active" ;
VAL_ 1302 AMRadioFrequanceValue 0 " Not active" ;
VAL_ 1302 FMRadioFrequanceValue 0 " Not active" ;
VAL_ 1302 RRMOnSts 1 " RRMOn" 0 " RRMOff                                                     " ;
VAL_ 1302 SourceStationMode 7 " Local Storage" 6 " iPOD" 5 " Bluetooth" 4 " Online radio" 3 " Online music" 2 " USB" 1 " Tuner" 0 " Not active" ;
VAL_ 1302 RadioResearchSts 3 " Not Used" 2 " AST                                                              " 1 " Normal                                                " 0 " Not active                                               " ;
VAL_ 1302 RadioFrequanceMode 3 " Not Used" 2 " AM mode                                                        " 1 " FM mode                                                 " 0 " Not active                                                 " ;
VAL_ 1301 BSDSwitchSts 3 " Not Used" 2 " OFF" 1 " ON       " 0 " Not active      " ;
VAL_ 1301 RRMResolutionY 2046 " Not used" 2045 " Not used" 2044 " Not used" 2043 " Not used" 2042 " Not used" 2041 " Not used" 2040 " Not used" 2039 " Not used" 2038 " Not used" 2037 " Not used" 2036 " Not used" 2035 " Not used" 2034 " Not used" 2033 " Not used" 2032 " Not used" 2031 " Not used" 2030 " Not used" 2029 " Not used" 2028 " Not used" 2027 " Not used" 2026 " Not used" 2025 " Not used" 2024 " Not used" 2023 " Not used" 2022 " Not used" 2021 " Not used" 2020 " Not used" 2019 " Not used" 2018 " Not used" 2017 " Not used" 2016 " Not used" 2015 " Not used" 2014 " Not used" 2013 " Not used" 2012 " Not used" 2011 " Not used" 2010 " Not used" 2009 " Not used" 2008 " Not used" 2007 " Not used" 2006 " Not used" 2005 " Not used" 2004 " Not used" 2003 " Not used" 2002 " Not used" 2001 " Not used" 2000 " Not used" 1999 " Not used" 1998 " Not used" 1997 " Not used" 1996 " Not used" 1995 " Not used" 1994 " Not used" 1993 " Not used" 1992 " Not used" 1991 " Not used" 1990 " Not used" 1989 " Not used" 1988 " Not used" 1987 " Not used" 1986 " Not used" 1985 " Not used" 1984 " Not used" 1983 " Not used" 1982 " Not used" 1981 " Not used" 1980 " Not used" 1979 " Not used" 1978 " Not used" 1977 " Not used" 1976 " Not used" 1975 " Not used" 1974 " Not used" 1973 " Not used" 1972 " Not used" 1971 " Not used" 1970 " Not used" 1969 " Not used" 1968 " Not used" 1967 " Not used" 1966 " Not used" 1965 " Not used" 1964 " Not used" 1963 " Not used" 1962 " Not used" 1961 " Not used" 1960 " Not used" 1959 " Not used" 1958 " Not used" 1957 " Not used" 1956 " Not used" 1955 " Not used" 1954 " Not used" 1953 " Not used" 1952 " Not used" 1951 " Not used" 1950 " Not used" 1949 " Not used" 1948 " Not used" 1947 " Not used" 1946 " Not used" 1945 " Not used" 1944 " Not used" 1943 " Not used" 1942 " Not used" 1941 " Not used" 1940 " Not used" 1939 " Not used" 1938 " Not used" 1937 " Not used" 1936 " Not used" 1935 " Not used" 1934 " Not used" 1933 " Not used" 1932 " Not used" 1931 " Not used" 1930 " Not used" 1929 " Not used" 1928 " Not used" 1927 " Not used" 1926 " Not used" 1925 " Not used" 1924 " Not used" 1923 " Not used" 1922 " Not used" 1921 " Not used" 1920 " Not used" 1919 " Not used" 1918 " Not used" 1917 " Not used" 1916 " Not used" 1915 " Not used" 1914 " Not used" 1913 " Not used" 1912 " Not used" 1911 " Not used" 1910 " Not used" 1909 " Not used" 1908 " Not used" 1907 " Not used" 1906 " Not used" 1905 " Not used" 1904 " Not used" 1903 " Not used" 1902 " Not used" 1901 " Not used" 1900 " Not used" 1899 " Not used" 1898 " Not used" 1897 " Not used" 1896 " Not used" 1895 " Not used" 1894 " Not used" 1893 " Not used" 1892 " Not used" 1891 " Not used" 1890 " Not used" 1889 " Not used" 1888 " Not used" 1887 " Not used" 1886 " Not used" 1885 " Not used" 1884 " Not used" 1883 " Not used" 1882 " Not used" 1881 " Not used" 1880 " Not used" 1879 " Not used" 1878 " Not used" 1877 " Not used" 1876 " Not used" 1875 " Not used" 1874 " Not used" 1873 " Not used" 1872 " Not used" 1871 " Not used" 1870 " Not used" 1869 " Not used" 1868 " Not used" 1867 " Not used" 1866 " Not used" 1865 " Not used" 1864 " Not used" 1863 " Not used" 1862 " Not used" 1861 " Not used" 1860 " Not used" 1859 " Not used" 1858 " Not used" 1857 " Not used" 1856 " Not used" 1855 " Not used" 1854 " Not used" 1853 " Not used" 1852 " Not used" 1851 " Not used" 1850 " Not used" 1849 " Not used" 1848 " Not used" 1847 " Not used" 1846 " Not used" 1845 " Not used" 1844 " Not used" 1843 " Not used" 1842 " Not used" 1841 " Not used" 1840 " Not used" 1839 " Not used" 1838 " Not used" 1837 " Not used" 1836 " Not used" 1835 " Not used" 1834 " Not used" 1833 " Not used" 1832 " Not used" 1831 " Not used" 1830 " Not used" 1829 " Not used" 1828 " Not used" 1827 " Not used" 1826 " Not used" 1825 " Not used" 1824 " Not used" 1823 " Not used" 1822 " Not used" 1821 " Not used" 1820 " Not used" 1819 " Not used" 1818 " Not used" 1817 " Not used" 1816 " Not used" 1815 " Not used" 1814 " Not used" 1813 " Not used" 1812 " Not used" 1811 " Not used" 1810 " Not used" 1809 " Not used" 1808 " Not used" 1807 " Not used" 1806 " Not used" 1805 " Not used" 1804 " Not used" 1803 " Not used" 1802 " Not used" 1801 " Not used" 1800 " Not used" 1799 " Not used" 1798 " Not used" 1797 " Not used" 1796 " Not used" 1795 " Not used" 1794 " Not used" 1793 " Not used" 1792 " Not used" 1791 " Not used" 1790 " Not used" 1789 " Not used" 1788 " Not used" 1787 " Not used" 1786 " Not used" 1785 " Not used" 1784 " Not used" 1783 " Not used" 1782 " Not used" 1781 " Not used" 1780 " Not used" 1779 " Not used" 1778 " Not used" 1777 " Not used" 1776 " Not used" 1775 " Not used" 1774 " Not used" 1773 " Not used" 1772 " Not used" 1771 " Not used" 1770 " Not used" 1769 " Not used" 1768 " Not used" 1767 " Not used" 1766 " Not used" 1765 " Not used" 1764 " Not used" 1763 " Not used" 1762 " Not used" 1761 " Not used" 1760 " Not used" 1759 " Not used" 1758 " Not used" 1757 " Not used" 1756 " Not used" 1755 " Not used" 1754 " Not used" 1753 " Not used" 1752 " Not used" 1751 " Not used" 1750 " Not used" 1749 " Not used" 1748 " Not used" 1747 " Not used" 1746 " Not used" 1745 " Not used" 1744 " Not used" 1743 " Not used" 1742 " Not used" 1741 " Not used" 1740 " Not used" 1739 " Not used" 1738 " Not used" 1737 " Not used" 1736 " Not used" 1735 " Not used" 1734 " Not used" 1733 " Not used" 1732 " Not used" 1731 " Not used" 1730 " Not used" 1729 " Not used" 1728 " Not used" 1727 " Not used" 1726 " Not used" 1725 " Not used" 1724 " Not used" 1723 " Not used" 1722 " Not used" 1721 " Not used" 1720 " Not used" 1719 " Not used" 1718 " Not used" 1717 " Not used" 1716 " Not used" 1715 " Not used" 1714 " Not used" 1713 " Not used" 1712 " Not used" 1711 " Not used" 1710 " Not used" 1709 " Not used" 1708 " Not used" 1707 " Not used" 1706 " Not used" 1705 " Not used" 1704 " Not used" 1703 " Not used" 1702 " Not used" 1701 " Not used" 1700 " Not used" 1699 " Not used" 1698 " Not used" 1697 " Not used" 1696 " Not used" 1695 " Not used" 1694 " Not used" 1693 " Not used" 1692 " Not used" 1691 " Not used" 1690 " Not used" 1689 " Not used" 1688 " Not used" 1687 " Not used" 1686 " Not used" 1685 " Not used" 1684 " Not used" 1683 " Not used" 1682 " Not used" 1681 " Not used" 1680 " Not used" 1679 " Not used" 1678 " Not used" 1677 " Not used" 1676 " Not used" 1675 " Not used" 1674 " Not used" 1673 " Not used" 1672 " Not used" 1671 " Not used" 1670 " Not used" 1669 " Not used" 1668 " Not used" 1667 " Not used" 1666 " Not used" 1665 " Not used" 1664 " Not used" 1663 " Not used" 1662 " Not used" 1661 " Not used" 1660 " Not used" 1659 " Not used" 1658 " Not used" 1657 " Not used" 1656 " Not used" 1655 " Not used" 1654 " Not used" 1653 " Not used" 1652 " Not used" 1651 " Not used" 1650 " Not used" 1649 " Not used" 1648 " Not used" 1647 " Not used" 1646 " Not used" 1645 " Not used" 1644 " Not used" 1643 " Not used" 1642 " Not used" 1641 " Not used" 1640 " Not used" 1639 " Not used" 1638 " Not used" 1637 " Not used" 1636 " Not used" 1635 " Not used" 1634 " Not used" 1633 " Not used" 1632 " Not used" 1631 " Not used" 1630 " Not used" 1629 " Not used" 1628 " Not used" 1627 " Not used" 1626 " Not used" 1625 " Not used" 1624 " Not used" 1623 " Not used" 1622 " Not used" 1621 " Not used" 1620 " Not used" 1619 " Not used" 1618 " Not used" 1617 " Not used" 1616 " Not used" 1615 " Not used" 1614 " Not used" 1613 " Not used" 1612 " Not used" 1611 " Not used" 1610 " Not used" 1609 " Not used" 1608 " Not used" 1607 " Not used" 1606 " Not used" 1605 " Not used" 1604 " Not used" 1603 " Not used" 1602 " Not used" 1601 " Not used" 1600 " Not used" ;
VAL_ 1301 RRMResolutionX 4094 " Not used" 4093 " Not used" 4092 " Not used" 4091 " Not used" 4090 " Not used" 4089 " Not used" 4088 " Not used" 4087 " Not used" 4086 " Not used" 4085 " Not used" 4084 " Not used" 4083 " Not used" 4082 " Not used" 4081 " Not used" 4080 " Not used" 4079 " Not used" 4078 " Not used" 4077 " Not used" 4076 " Not used" 4075 " Not used" 4074 " Not used" 4073 " Not used" 4072 " Not used" 4071 " Not used" 4070 " Not used" 4069 " Not used" 4068 " Not used" 4067 " Not used" 4066 " Not used" 4065 " Not used" 4064 " Not used" 4063 " Not used" 4062 " Not used" 4061 " Not used" 4060 " Not used" 4059 " Not used" 4058 " Not used" 4057 " Not used" 4056 " Not used" 4055 " Not used" 4054 " Not used" 4053 " Not used" 4052 " Not used" 4051 " Not used" 4050 " Not used" 4049 " Not used" 4048 " Not used" 4047 " Not used" 4046 " Not used" 4045 " Not used" 4044 " Not used" 4043 " Not used" 4042 " Not used" 4041 " Not used" 4040 " Not used" 4039 " Not used" 4038 " Not used" 4037 " Not used" 4036 " Not used" 4035 " Not used" 4034 " Not used" 4033 " Not used" 4032 " Not used" 4031 " Not used" 4030 " Not used" 4029 " Not used" 4028 " Not used" 4027 " Not used" 4026 " Not used" 4025 " Not used" 4024 " Not used" 4023 " Not used" 4022 " Not used" 4021 " Not used" 4020 " Not used" 4019 " Not used" 4018 " Not used" 4017 " Not used" 4016 " Not used" 4015 " Not used" 4014 " Not used" 4013 " Not used" 4012 " Not used" 4011 " Not used" 4010 " Not used" 4009 " Not used" 4008 " Not used" 4007 " Not used" 4006 " Not used" 4005 " Not used" 4004 " Not used" 4003 " Not used" 4002 " Not used" 4001 " Not used" 4000 " Not used" 3999 " Not used" 3998 " Not used" 3997 " Not used" 3996 " Not used" 3995 " Not used" 3994 " Not used" 3993 " Not used" 3992 " Not used" 3991 " Not used" 3990 " Not used" 3989 " Not used" 3988 " Not used" 3987 " Not used" 3986 " Not used" 3985 " Not used" 3984 " Not used" 3983 " Not used" 3982 " Not used" 3981 " Not used" 3980 " Not used" 3979 " Not used" 3978 " Not used" 3977 " Not used" 3976 " Not used" 3975 " Not used" 3974 " Not used" 3973 " Not used" 3972 " Not used" 3971 " Not used" 3970 " Not used" 3969 " Not used" 3968 " Not used" 3967 " Not used" 3966 " Not used" 3965 " Not used" 3964 " Not used" 3963 " Not used" 3962 " Not used" 3961 " Not used" 3960 " Not used" 3959 " Not used" 3958 " Not used" 3957 " Not used" 3956 " Not used" 3955 " Not used" 3954 " Not used" 3953 " Not used" 3952 " Not used" 3951 " Not used" 3950 " Not used" 3949 " Not used" 3948 " Not used" 3947 " Not used" 3946 " Not used" 3945 " Not used" 3944 " Not used" 3943 " Not used" 3942 " Not used" 3941 " Not used" 3940 " Not used" 3939 " Not used" 3938 " Not used" 3937 " Not used" 3936 " Not used" 3935 " Not used" 3934 " Not used" 3933 " Not used" 3932 " Not used" 3931 " Not used" 3930 " Not used" 3929 " Not used" 3928 " Not used" 3927 " Not used" 3926 " Not used" 3925 " Not used" 3924 " Not used" 3923 " Not used" 3922 " Not used" 3921 " Not used" 3920 " Not used" 3919 " Not used" 3918 " Not used" 3917 " Not used" 3916 " Not used" 3915 " Not used" 3914 " Not used" 3913 " Not used" 3912 " Not used" 3911 " Not used" 3910 " Not used" 3909 " Not used" 3908 " Not used" 3907 " Not used" 3906 " Not used" 3905 " Not used" 3904 " Not used" 3903 " Not used" 3902 " Not used" 3901 " Not used" 3900 " Not used" 3899 " Not used" 3898 " Not used" 3897 " Not used" 3896 " Not used" 3895 " Not used" 3894 " Not used" 3893 " Not used" 3892 " Not used" 3891 " Not used" 3890 " Not used" 3889 " Not used" 3888 " Not used" 3887 " Not used" 3886 " Not used" 3885 " Not used" 3884 " Not used" 3883 " Not used" 3882 " Not used" 3881 " Not used" 3880 " Not used" 3879 " Not used" 3878 " Not used" 3877 " Not used" 3876 " Not used" 3875 " Not used" 3874 " Not used" 3873 " Not used" 3872 " Not used" 3871 " Not used" 3870 " Not used" 3869 " Not used" 3868 " Not used" 3867 " Not used" 3866 " Not used" 3865 " Not used" 3864 " Not used" 3863 " Not used" 3862 " Not used" 3861 " Not used" 3860 " Not used" 3859 " Not used" 3858 " Not used" 3857 " Not used" 3856 " Not used" 3855 " Not used" 3854 " Not used" 3853 " Not used" 3852 " Not used" 3851 " Not used" 3850 " Not used" 3849 " Not used" 3848 " Not used" 3847 " Not used" 3846 " Not used" 3845 " Not used" 3844 " Not used" 3843 " Not used" 3842 " Not used" 3841 " Not used" 3840 " Not used" 3839 " Not used" 3838 " Not used" 3837 " Not used" 3836 " Not used" 3835 " Not used" 3834 " Not used" 3833 " Not used" 3832 " Not used" 3831 " Not used" 3830 " Not used" 3829 " Not used" 3828 " Not used" 3827 " Not used" 3826 " Not used" 3825 " Not used" 3824 " Not used" 3823 " Not used" 3822 " Not used" 3821 " Not used" 3820 " Not used" 3819 " Not used" 3818 " Not used" 3817 " Not used" 3816 " Not used" 3815 " Not used" 3814 " Not used" 3813 " Not used" 3812 " Not used" 3811 " Not used" 3810 " Not used" 3809 " Not used" 3808 " Not used" 3807 " Not used" 3806 " Not used" 3805 " Not used" 3804 " Not used" 3803 " Not used" 3802 " Not used" 3801 " Not used" 3800 " Not used" 3799 " Not used" 3798 " Not used" 3797 " Not used" 3796 " Not used" 3795 " Not used" 3794 " Not used" 3793 " Not used" 3792 " Not used" 3791 " Not used" 3790 " Not used" 3789 " Not used" 3788 " Not used" 3787 " Not used" 3786 " Not used" 3785 " Not used" 3784 " Not used" 3783 " Not used" 3782 " Not used" 3781 " Not used" 3780 " Not used" 3779 " Not used" 3778 " Not used" 3777 " Not used" 3776 " Not used" 3775 " Not used" 3774 " Not used" 3773 " Not used" 3772 " Not used" 3771 " Not used" 3770 " Not used" 3769 " Not used" 3768 " Not used" 3767 " Not used" 3766 " Not used" 3765 " Not used" 3764 " Not used" 3763 " Not used" 3762 " Not used" 3761 " Not used" 3760 " Not used" 3759 " Not used" 3758 " Not used" 3757 " Not used" 3756 " Not used" 3755 " Not used" 3754 " Not used" 3753 " Not used" 3752 " Not used" 3751 " Not used" 3750 " Not used" 3749 " Not used" 3748 " Not used" 3747 " Not used" 3746 " Not used" 3745 " Not used" 3744 " Not used" 3743 " Not used" 3742 " Not used" 3741 " Not used" 3740 " Not used" 3739 " Not used" 3738 " Not used" 3737 " Not used" 3736 " Not used" 3735 " Not used" 3734 " Not used" 3733 " Not used" 3732 " Not used" 3731 " Not used" 3730 " Not used" 3729 " Not used" 3728 " Not used" 3727 " Not used" 3726 " Not used" 3725 " Not used" 3724 " Not used" 3723 " Not used" 3722 " Not used" 3721 " Not used" 3720 " Not used" 3719 " Not used" 3718 " Not used" 3717 " Not used" 3716 " Not used" 3715 " Not used" 3714 " Not used" 3713 " Not used" 3712 " Not used" 3711 " Not used" 3710 " Not used" 3709 " Not used" 3708 " Not used" 3707 " Not used" 3706 " Not used" 3705 " Not used" 3704 " Not used" 3703 " Not used" 3702 " Not used" 3701 " Not used" 3700 " Not used" 3699 " Not used" 3698 " Not used" 3697 " Not used" 3696 " Not used" 3695 " Not used" 3694 " Not used" 3693 " Not used" 3692 " Not used" 3691 " Not used" 3690 " Not used" 3689 " Not used" 3688 " Not used" 3687 " Not used" 3686 " Not used" 3685 " Not used" 3684 " Not used" 3683 " Not used" 3682 " Not used" 3681 " Not used" 3680 " Not used" 3679 " Not used" 3678 " Not used" 3677 " Not used" 3676 " Not used" 3675 " Not used" 3674 " Not used" 3673 " Not used" 3672 " Not used" 3671 " Not used" 3670 " Not used" 3669 " Not used" 3668 " Not used" 3667 " Not used" 3666 " Not used" 3665 " Not used" 3664 " Not used" 3663 " Not used" 3662 " Not used" 3661 " Not used" 3660 " Not used" 3659 " Not used" 3658 " Not used" 3657 " Not used" 3656 " Not used" 3655 " Not used" 3654 " Not used" 3653 " Not used" 3652 " Not used" 3651 " Not used" 3650 " Not used" 3649 " Not used" 3648 " Not used" 3647 " Not used" 3646 " Not used" 3645 " Not used" 3644 " Not used" 3643 " Not used" 3642 " Not used" 3641 " Not used" 3640 " Not used" 3639 " Not used" 3638 " Not used" 3637 " Not used" 3636 " Not used" 3635 " Not used" 3634 " Not used" 3633 " Not used" 3632 " Not used" 3631 " Not used" 3630 " Not used" 3629 " Not used" 3628 " Not used" 3627 " Not used" 3626 " Not used" 3625 " Not used" 3624 " Not used" 3623 " Not used" 3622 " Not used" 3621 " Not used" 3620 " Not used" 3619 " Not used" 3618 " Not used" 3617 " Not used" 3616 " Not used" 3615 " Not used" 3614 " Not used" 3613 " Not used" 3612 " Not used" 3611 " Not used" 3610 " Not used" 3609 " Not used" 3608 " Not used" 3607 " Not used" 3606 " Not used" 3605 " Not used" 3604 " Not used" 3603 " Not used" 3602 " Not used" 3601 " Not used" 3600 " Not used" 3599 " Not used" 3598 " Not used" 3597 " Not used" 3596 " Not used" 3595 " Not used" 3594 " Not used" 3593 " Not used" 3592 " Not used" 3591 " Not used" 3590 " Not used" 3589 " Not used" 3588 " Not used" 3587 " Not used" 3586 " Not used" 3585 " Not used" 3584 " Not used" 3583 " Not used" 3582 " Not used" 3581 " Not used" 3580 " Not used" 3579 " Not used" 3578 " Not used" 3577 " Not used" 3576 " Not used" 3575 " Not used" 3574 " Not used" 3573 " Not used" 3572 " Not used" 3571 " Not used" 3570 " Not used" 3569 " Not used" 3568 " Not used" 3567 " Not used" 3566 " Not used" 3565 " Not used" 3564 " Not used" 3563 " Not used" 3562 " Not used" 3561 " Not used" 3560 " Not used" 3559 " Not used" 3558 " Not used" 3557 " Not used" 3556 " Not used" 3555 " Not used" 3554 " Not used" 3553 " Not used" 3552 " Not used" 3551 " Not used" 3550 " Not used" 3549 " Not used" 3548 " Not used" 3547 " Not used" 3546 " Not used" 3545 " Not used" 3544 " Not used" 3543 " Not used" 3542 " Not used" 3541 " Not used" 3540 " Not used" 3539 " Not used" 3538 " Not used" 3537 " Not used" 3536 " Not used" 3535 " Not used" 3534 " Not used" 3533 " Not used" 3532 " Not used" 3531 " Not used" 3530 " Not used" 3529 " Not used" 3528 " Not used" 3527 " Not used" 3526 " Not used" 3525 " Not used" 3524 " Not used" 3523 " Not used" 3522 " Not used" 3521 " Not used" 3520 " Not used" 3519 " Not used" 3518 " Not used" 3517 " Not used" 3516 " Not used" 3515 " Not used" 3514 " Not used" 3513 " Not used" 3512 " Not used" 3511 " Not used" 3510 " Not used" 3509 " Not used" 3508 " Not used" 3507 " Not used" 3506 " Not used" 3505 " Not used" 3504 " Not used" 3503 " Not used" 3502 " Not used" 3501 " Not used" 3500 " Not used" 3499 " Not used" 3498 " Not used" 3497 " Not used" 3496 " Not used" 3495 " Not used" 3494 " Not used" 3493 " Not used" 3492 " Not used" 3491 " Not used" 3490 " Not used" 3489 " Not used" 3488 " Not used" 3487 " Not used" 3486 " Not used" 3485 " Not used" 3484 " Not used" 3483 " Not used" 3482 " Not used" 3481 " Not used" 3480 " Not used" 3479 " Not used" 3478 " Not used" 3477 " Not used" 3476 " Not used" 3475 " Not used" 3474 " Not used" 3473 " Not used" 3472 " Not used" 3471 " Not used" 3470 " Not used" 3469 " Not used" 3468 " Not used" 3467 " Not used" 3466 " Not used" 3465 " Not used" 3464 " Not used" 3463 " Not used" 3462 " Not used" 3461 " Not used" 3460 " Not used" 3459 " Not used" 3458 " Not used" 3457 " Not used" 3456 " Not used" 3455 " Not used" 3454 " Not used" 3453 " Not used" 3452 " Not used" 3451 " Not used" 3450 " Not used" 3449 " Not used" 3448 " Not used" 3447 " Not used" 3446 " Not used" 3445 " Not used" 3444 " Not used" 3443 " Not used" 3442 " Not used" 3441 " Not used" 3440 " Not used" 3439 " Not used" 3438 " Not used" 3437 " Not used" 3436 " Not used" 3435 " Not used" 3434 " Not used" 3433 " Not used" 3432 " Not used" 3431 " Not used" 3430 " Not used" 3429 " Not used" 3428 " Not used" 3427 " Not used" 3426 " Not used" 3425 " Not used" 3424 " Not used" 3423 " Not used" 3422 " Not used" 3421 " Not used" 3420 " Not used" 3419 " Not used" 3418 " Not used" 3417 " Not used" 3416 " Not used" 3415 " Not used" 3414 " Not used" 3413 " Not used" 3412 " Not used" 3411 " Not used" 3410 " Not used" 3409 " Not used" 3408 " Not used" 3407 " Not used" 3406 " Not used" 3405 " Not used" 3404 " Not used" 3403 " Not used" 3402 " Not used" 3401 " Not used" 3400 " Not used" 3399 " Not used" 3398 " Not used" 3397 " Not used" 3396 " Not used" 3395 " Not used" 3394 " Not used" 3393 " Not used" 3392 " Not used" 3391 " Not used" 3390 " Not used" 3389 " Not used" 3388 " Not used" 3387 " Not used" 3386 " Not used" 3385 " Not used" 3384 " Not used" 3383 " Not used" 3382 " Not used" 3381 " Not used" 3380 " Not used" 3379 " Not used" 3378 " Not used" 3377 " Not used" 3376 " Not used" 3375 " Not used" 3374 " Not used" 3373 " Not used" 3372 " Not used" 3371 " Not used" 3370 " Not used" 3369 " Not used" 3368 " Not used" 3367 " Not used" 3366 " Not used" 3365 " Not used" 3364 " Not used" 3363 " Not used" 3362 " Not used" 3361 " Not used" 3360 " Not used" 3359 " Not used" 3358 " Not used" 3357 " Not used" 3356 " Not used" 3355 " Not used" 3354 " Not used" 3353 " Not used" 3352 " Not used" 3351 " Not used" 3350 " Not used" 3349 " Not used" 3348 " Not used" 3347 " Not used" 3346 " Not used" 3345 " Not used" 3344 " Not used" 3343 " Not used" 3342 " Not used" 3341 " Not used" 3340 " Not used" 3339 " Not used" 3338 " Not used" 3337 " Not used" 3336 " Not used" 3335 " Not used" 3334 " Not used" 3333 " Not used" 3332 " Not used" 3331 " Not used" 3330 " Not used" 3329 " Not used" 3328 " Not used" 3327 " Not used" 3326 " Not used" 3325 " Not used" 3324 " Not used" 3323 " Not used" 3322 " Not used" 3321 " Not used" 3320 " Not used" 3319 " Not used" 3318 " Not used" 3317 " Not used" 3316 " Not used" 3315 " Not used" 3314 " Not used" 3313 " Not used" 3312 " Not used" 3311 " Not used" 3310 " Not used" 3309 " Not used" 3308 " Not used" 3307 " Not used" 3306 " Not used" 3305 " Not used" 3304 " Not used" 3303 " Not used" 3302 " Not used" 3301 " Not used" 3300 " Not used" 3299 " Not used" 3298 " Not used" 3297 " Not used" 3296 " Not used" 3295 " Not used" 3294 " Not used" 3293 " Not used" 3292 " Not used" 3291 " Not used" 3290 " Not used" 3289 " Not used" 3288 " Not used" 3287 " Not used" 3286 " Not used" 3285 " Not used" 3284 " Not used" 3283 " Not used" 3282 " Not used" 3281 " Not used" 3280 " Not used" 3279 " Not used" 3278 " Not used" 3277 " Not used" 3276 " Not used" 3275 " Not used" 3274 " Not used" 3273 " Not used" 3272 " Not used" 3271 " Not used" 3270 " Not used" 3269 " Not used" 3268 " Not used" 3267 " Not used" 3266 " Not used" 3265 " Not used" 3264 " Not used" 3263 " Not used" 3262 " Not used" 3261 " Not used" 3260 " Not used" 3259 " Not used" 3258 " Not used" 3257 " Not used" 3256 " Not used" 3255 " Not used" 3254 " Not used" 3253 " Not used" 3252 " Not used" 3251 " Not used" 3250 " Not used" 3249 " Not used" 3248 " Not used" 3247 " Not used" 3246 " Not used" 3245 " Not used" 3244 " Not used" 3243 " Not used" 3242 " Not used" 3241 " Not used" 3240 " Not used" 3239 " Not used" 3238 " Not used" 3237 " Not used" 3236 " Not used" 3235 " Not used" 3234 " Not used" 3233 " Not used" 3232 " Not used" 3231 " Not used" 3230 " Not used" 3229 " Not used" 3228 " Not used" 3227 " Not used" 3226 " Not used" 3225 " Not used" 3224 " Not used" 3223 " Not used" 3222 " Not used" 3221 " Not used" 3220 " Not used" 3219 " Not used" 3218 " Not used" 3217 " Not used" 3216 " Not used" 3215 " Not used" 3214 " Not used" 3213 " Not used" 3212 " Not used" 3211 " Not used" 3210 " Not used" 3209 " Not used" 3208 " Not used" 3207 " Not used" 3206 " Not used" 3205 " Not used" 3204 " Not used" 3203 " Not used" 3202 " Not used" 3201 " Not used" 3200 " Not used" 3199 " Not used" 3198 " Not used" 3197 " Not used" 3196 " Not used" 3195 " Not used" 3194 " Not used" 3193 " Not used" 3192 " Not used" 3191 " Not used" 3190 " Not used" 3189 " Not used" 3188 " Not used" 3187 " Not used" 3186 " Not used" 3185 " Not used" 3184 " Not used" 3183 " Not used" 3182 " Not used" 3181 " Not used" 3180 " Not used" 3179 " Not used" 3178 " Not used" 3177 " Not used" 3176 " Not used" 3175 " Not used" 3174 " Not used" 3173 " Not used" 3172 " Not used" 3171 " Not used" 3170 " Not used" 3169 " Not used" 3168 " Not used" 3167 " Not used" 3166 " Not used" 3165 " Not used" 3164 " Not used" 3163 " Not used" 3162 " Not used" 3161 " Not used" 3160 " Not used" 3159 " Not used" 3158 " Not used" 3157 " Not used" 3156 " Not used" 3155 " Not used" 3154 " Not used" 3153 " Not used" 3152 " Not used" 3151 " Not used" 3150 " Not used" 3149 " Not used" 3148 " Not used" 3147 " Not used" 3146 " Not used" 3145 " Not used" 3144 " Not used" 3143 " Not used" 3142 " Not used" 3141 " Not used" 3140 " Not used" 3139 " Not used" 3138 " Not used" 3137 " Not used" 3136 " Not used" 3135 " Not used" 3134 " Not used" 3133 " Not used" 3132 " Not used" 3131 " Not used" 3130 " Not used" 3129 " Not used" 3128 " Not used" 3127 " Not used" 3126 " Not used" 3125 " Not used" 3124 " Not used" 3123 " Not used" 3122 " Not used" 3121 " Not used" 3120 " Not used" 3119 " Not used" 3118 " Not used" 3117 " Not used" 3116 " Not used" 3115 " Not used" 3114 " Not used" 3113 " Not used" 3112 " Not used" 3111 " Not used" 3110 " Not used" 3109 " Not used" 3108 " Not used" 3107 " Not used" 3106 " Not used" 3105 " Not used" 3104 " Not used" 3103 " Not used" 3102 " Not used" 3101 " Not used" 3100 " Not used" 3099 " Not used" 3098 " Not used" 3097 " Not used" 3096 " Not used" 3095 " Not used" 3094 " Not used" 3093 " Not used" 3092 " Not used" 3091 " Not used" 3090 " Not used" 3089 " Not used" 3088 " Not used" 3087 " Not used" 3086 " Not used" 3085 " Not used" 3084 " Not used" 3083 " Not used" 3082 " Not used" 3081 " Not used" 3080 " Not used" 3079 " Not used" 3078 " Not used" 3077 " Not used" 3076 " Not used" 3075 " Not used" 3074 " Not used" 3073 " Not used" 3072 " Not used" 3071 " Not used" 3070 " Not used" 3069 " Not used" 3068 " Not used" 3067 " Not used" 3066 " Not used" 3065 " Not used" 3064 " Not used" 3063 " Not used" 3062 " Not used" 3061 " Not used" 3060 " Not used" 3059 " Not used" 3058 " Not used" 3057 " Not used" 3056 " Not used" 3055 " Not used" 3054 " Not used" 3053 " Not used" 3052 " Not used" 3051 " Not used" 3050 " Not used" 3049 " Not used" 3048 " Not used" 3047 " Not used" 3046 " Not used" 3045 " Not used" 3044 " Not used" 3043 " Not used" 3042 " Not used" 3041 " Not used" 3040 " Not used" 3039 " Not used" 3038 " Not used" 3037 " Not used" 3036 " Not used" 3035 " Not used" 3034 " Not used" 3033 " Not used" 3032 " Not used" 3031 " Not used" 3030 " Not used" 3029 " Not used" 3028 " Not used" 3027 " Not used" 3026 " Not used" 3025 " Not used" 3024 " Not used" 3023 " Not used" 3022 " Not used" 3021 " Not used" 3020 " Not used" 3019 " Not used" 3018 " Not used" 3017 " Not used" 3016 " Not used" 3015 " Not used" 3014 " Not used" 3013 " Not used" 3012 " Not used" 3011 " Not used" 3010 " Not used" 3009 " Not used" 3008 " Not used" 3007 " Not used" 3006 " Not used" 3005 " Not used" 3004 " Not used" 3003 " Not used" 3002 " Not used" 3001 " Not used" 3000 " Not used" 2999 " Not used" 2998 " Not used" 2997 " Not used" 2996 " Not used" 2995 " Not used" 2994 " Not used" 2993 " Not used" 2992 " Not used" 2991 " Not used" 2990 " Not used" 2989 " Not used" 2988 " Not used" 2987 " Not used" 2986 " Not used" 2985 " Not used" 2984 " Not used" 2983 " Not used" 2982 " Not used" 2981 " Not used" 2980 " Not used" 2979 " Not used" 2978 " Not used" 2977 " Not used" 2976 " Not used" 2975 " Not used" 2974 " Not used" 2973 " Not used" 2972 " Not used" 2971 " Not used" 2970 " Not used" 2969 " Not used" 2968 " Not used" 2967 " Not used" 2966 " Not used" 2965 " Not used" 2964 " Not used" 2963 " Not used" 2962 " Not used" 2961 " Not used" 2960 " Not used" 2959 " Not used" 2958 " Not used" 2957 " Not used" 2956 " Not used" 2955 " Not used" 2954 " Not used" 2953 " Not used" 2952 " Not used" 2951 " Not used" 2950 " Not used" 2949 " Not used" 2948 " Not used" 2947 " Not used" 2946 " Not used" 2945 " Not used" 2944 " Not used" 2943 " Not used" 2942 " Not used" 2941 " Not used" 2940 " Not used" 2939 " Not used" 2938 " Not used" 2937 " Not used" 2936 " Not used" 2935 " Not used" 2934 " Not used" 2933 " Not used" 2932 " Not used" 2931 " Not used" 2930 " Not used" 2929 " Not used" 2928 " Not used" 2927 " Not used" 2926 " Not used" 2925 " Not used" 2924 " Not used" 2923 " Not used" 2922 " Not used" 2921 " Not used" 2920 " Not used" 2919 " Not used" 2918 " Not used" 2917 " Not used" 2916 " Not used" 2915 " Not used" 2914 " Not used" 2913 " Not used" 2912 " Not used" 2911 " Not used" 2910 " Not used" 2909 " Not used" 2908 " Not used" 2907 " Not used" 2906 " Not used" 2905 " Not used" 2904 " Not used" 2903 " Not used" 2902 " Not used" 2901 " Not used" 2900 " Not used" 2899 " Not used" 2898 " Not used" 2897 " Not used" 2896 " Not used" 2895 " Not used" 2894 " Not used" 2893 " Not used" 2892 " Not used" 2891 " Not used" 2890 " Not used" 2889 " Not used" 2888 " Not used" 2887 " Not used" 2886 " Not used" 2885 " Not used" 2884 " Not used" 2883 " Not used" 2882 " Not used" 2881 " Not used" 2880 " Not used" 2879 " Not used" 2878 " Not used" 2877 " Not used" 2876 " Not used" 2875 " Not used" 2874 " Not used" 2873 " Not used" 2872 " Not used" 2871 " Not used" 2870 " Not used" 2869 " Not used" 2868 " Not used" 2867 " Not used" 2866 " Not used" 2865 " Not used" 2864 " Not used" 2863 " Not used" 2862 " Not used" 2861 " Not used" 2860 " Not used" 2859 " Not used" 2858 " Not used" 2857 " Not used" 2856 " Not used" 2855 " Not used" 2854 " Not used" 2853 " Not used" 2852 " Not used" 2851 " Not used" 2850 " Not used" 2849 " Not used" 2848 " Not used" 2847 " Not used" 2846 " Not used" 2845 " Not used" 2844 " Not used" 2843 " Not used" 2842 " Not used" 2841 " Not used" 2840 " Not used" 2839 " Not used" 2838 " Not used" 2837 " Not used" 2836 " Not used" 2835 " Not used" 2834 " Not used" 2833 " Not used" 2832 " Not used" 2831 " Not used" 2830 " Not used" 2829 " Not used" 2828 " Not used" 2827 " Not used" 2826 " Not used" 2825 " Not used" 2824 " Not used" 2823 " Not used" 2822 " Not used" 2821 " Not used" 2820 " Not used" 2819 " Not used" 2818 " Not used" 2817 " Not used" 2816 " Not used" 2815 " Not used" 2814 " Not used" 2813 " Not used" 2812 " Not used" 2811 " Not used" 2810 " Not used" 2809 " Not used" 2808 " Not used" 2807 " Not used" 2806 " Not used" 2805 " Not used" 2804 " Not used" 2803 " Not used" 2802 " Not used" 2801 " Not used" 2800 " Not used" 2799 " Not used" 2798 " Not used" 2797 " Not used" 2796 " Not used" 2795 " Not used" 2794 " Not used" 2793 " Not used" 2792 " Not used" 2791 " Not used" 2790 " Not used" 2789 " Not used" 2788 " Not used" 2787 " Not used" 2786 " Not used" 2785 " Not used" 2784 " Not used" 2783 " Not used" 2782 " Not used" 2781 " Not used" 2780 " Not used" 2779 " Not used" 2778 " Not used" 2777 " Not used" 2776 " Not used" 2775 " Not used" 2774 " Not used" 2773 " Not used" 2772 " Not used" 2771 " Not used" 2770 " Not used" 2769 " Not used" 2768 " Not used" 2767 " Not used" 2766 " Not used" 2765 " Not used" 2764 " Not used" 2763 " Not used" 2762 " Not used" 2761 " Not used" 2760 " Not used" 2759 " Not used" 2758 " Not used" 2757 " Not used" 2756 " Not used" 2755 " Not used" 2754 " Not used" 2753 " Not used" 2752 " Not used" 2751 " Not used" 2750 " Not used" 2749 " Not used" 2748 " Not used" 2747 " Not used" 2746 " Not used" 2745 " Not used" 2744 " Not used" 2743 " Not used" 2742 " Not used" 2741 " Not used" 2740 " Not used" 2739 " Not used" 2738 " Not used" 2737 " Not used" 2736 " Not used" 2735 " Not used" 2734 " Not used" 2733 " Not used" 2732 " Not used" 2731 " Not used" 2730 " Not used" 2729 " Not used" 2728 " Not used" 2727 " Not used" 2726 " Not used" 2725 " Not used" 2724 " Not used" 2723 " Not used" 2722 " Not used" 2721 " Not used" 2720 " Not used" 2719 " Not used" 2718 " Not used" 2717 " Not used" 2716 " Not used" 2715 " Not used" 2714 " Not used" 2713 " Not used" 2712 " Not used" 2711 " Not used" 2710 " Not used" 2709 " Not used" 2708 " Not used" 2707 " Not used" 2706 " Not used" 2705 " Not used" 2704 " Not used" 2703 " Not used" 2702 " Not used" 2701 " Not used" 2700 " Not used" 2699 " Not used" 2698 " Not used" 2697 " Not used" 2696 " Not used" 2695 " Not used" 2694 " Not used" 2693 " Not used" 2692 " Not used" 2691 " Not used" 2690 " Not used" 2689 " Not used" 2688 " Not used" 2687 " Not used" 2686 " Not used" 2685 " Not used" 2684 " Not used" 2683 " Not used" 2682 " Not used" 2681 " Not used" 2680 " Not used" 2679 " Not used" 2678 " Not used" 2677 " Not used" 2676 " Not used" 2675 " Not used" 2674 " Not used" 2673 " Not used" 2672 " Not used" 2671 " Not used" 2670 " Not used" 2669 " Not used" 2668 " Not used" 2667 " Not used" 2666 " Not used" 2665 " Not used" 2664 " Not used" 2663 " Not used" 2662 " Not used" 2661 " Not used" 2660 " Not used" 2659 " Not used" 2658 " Not used" 2657 " Not used" 2656 " Not used" 2655 " Not used" 2654 " Not used" 2653 " Not used" 2652 " Not used" 2651 " Not used" 2650 " Not used" 2649 " Not used" 2648 " Not used" 2647 " Not used" 2646 " Not used" 2645 " Not used" 2644 " Not used" 2643 " Not used" 2642 " Not used" 2641 " Not used" 2640 " Not used" 2639 " Not used" 2638 " Not used" 2637 " Not used" 2636 " Not used" 2635 " Not used" 2634 " Not used" 2633 " Not used" 2632 " Not used" 2631 " Not used" 2630 " Not used" 2629 " Not used" 2628 " Not used" 2627 " Not used" 2626 " Not used" 2625 " Not used" 2624 " Not used" 2623 " Not used" 2622 " Not used" 2621 " Not used" 2620 " Not used" 2619 " Not used" 2618 " Not used" 2617 " Not used" 2616 " Not used" 2615 " Not used" 2614 " Not used" 2613 " Not used" 2612 " Not used" 2611 " Not used" 2610 " Not used" 2609 " Not used" 2608 " Not used" 2607 " Not used" 2606 " Not used" 2605 " Not used" 2604 " Not used" 2603 " Not used" 2602 " Not used" 2601 " Not used" 2600 " Not used" 2599 " Not used" 2598 " Not used" 2597 " Not used" 2596 " Not used" 2595 " Not used" 2594 " Not used" 2593 " Not used" 2592 " Not used" 2591 " Not used" 2590 " Not used" 2589 " Not used" 2588 " Not used" 2587 " Not used" 2586 " Not used" 2585 " Not used" 2584 " Not used" 2583 " Not used" 2582 " Not used" 2581 " Not used" 2580 " Not used" 2579 " Not used" 2578 " Not used" 2577 " Not used" 2576 " Not used" 2575 " Not used" 2574 " Not used" 2573 " Not used" 2572 " Not used" 2571 " Not used" 2570 " Not used" 2569 " Not used" 2568 " Not used" 2567 " Not used" 2566 " Not used" 2565 " Not used" 2564 " Not used" 2563 " Not used" 2562 " Not used" 2561 " Not used" 2560 " Not used" ;
VAL_ 1301 LanguageSet 31 " Not Used" 30 " Not Used" 29 " Not Used" 28 " Not Used" 27 " Not Used" 26 " Not Used" 25 " Not Used" 24 " Not Used" 23 " Not Used" 22 " Not Used" 21 " Not Used" 20 " Not Used" 19 " Not Used" 18 " Not Used" 17 " Not Used" 16 " Not Used" 15 " Not Used" 14 " Not Used" 13 " Not Used" 12 " Indonesian" 11 " Thai" 10 " Ukrainian" 9 " Turkish " 8 " Italian " 7 " Spanish   " 6 " Farsi  " 5 " Portuguese" 4 " Arabic " 3 " Russian   " 2 " English " 1 " Chinese" 0 " Not active" ;
VAL_ 1301 OverSpeedValue 63 " Cancel" 62 " Open" 61 " Not Used" 60 " Not Used" 59 " Not Used" 58 " Not Used" 57 " Not Used" 56 " Not Used" 55 " Not Used" 54 " Not Used" 53 " Not Used" 52 " Not Used" 51 " Not Used" 50 " Not Used" 49 " Not Used" 48 " Not Used" 47 " Not Used" 46 " Not Used" 45 " Not Used" 44 " Not Used" 43 " Not Used" 42 " 170km/h" 41 " 165km/h" 40 " 160km/h" 39 " 155km/h" 38 " 150km/h" 37 " 145km/h" 36 " 140km/h" 35 " 135km/h" 34 " 80mph" 33 " 75mph" 32 " 70mph" 31 " 65mph" 30 " 60mph" 29 " 55mph" 28 " 50mph" 27 " 45mph" 26 " 40mph" 25 " 35mph" 24 " 30mph" 23 " 25mph" 22 " 20mph" 21 " 130km/h" 20 " 125km/h" 19 " 120km/h                                                          " 18 " 115km/h" 17 " 110km/h" 16 " 105km/h" 15 " 100km/h" 14 " 95km/h " 13 " 90km/h" 12 " 85km/h" 11 " 80km/h" 10 " 75km/h" 9 " 70km/h" 8 " 65km/h" 7 " 60km/h" 6 " 55km/h" 5 " 50km/h" 4 " 45km/h" 3 " 40km/h" 2 " 35km/h" 1 " 30km/h" 0 " Not active" ;
VAL_ 1039 DMS_1_Atte_Regn 15 " Reserved" 14 " Reserved" 13 " Reserved" 12 " Other" 11 " Passenger Foot well" 10 " Driver Lap" 9 " Passenger  Side Mirror" 8 " Driver Side Mirror" 7 " Passenger Side Window" 6 " Driver Side Window" 5 " Infotainment" 4 " Cluster" 3 " Rear view Mirror" 2 " On-Road Right" 1 " On-Road Left" 0 " Not Determined" ;
VAL_ 1039 DMS_1_DrvrAbnormStAlrm 15 " Reserved" 14 " Reserved" 13 " Reserved" 12 " Reserved" 11 " Reserved" 10 " Reserved" 9 " Reserved" 8 " Seriously distracted" 7 " Blocked" 6 " Unresponsive" 5 " Asleep" 4 " Microsleep " 3 " Drowsycted " 2 " Long Distracted" 1 " Distracted" 0 " Not Active" ;
VAL_ 1039 DMS_1_AlrmSwtSt 3 " Reserved" 2 " Alarm Switch Off    " 1 " Alarm Switch On" 0 " Not Active" ;
VAL_ 1039 DMS_1_DrvUnrspvSt 1 " Unresponsive" 0 " Not Active" ;
VAL_ 1039 DMS_1_DrvrAlertSt 3 " Faulty" 2 " Eyes Off Road" 1 " Eyes On Road" 0 " Not Active" ;
VAL_ 1039 DMS_1_CameraSt 3 " Faulty" 2 " Blocked" 1 " Ok" 0 " Not Active" ;
VAL_ 1039 DMS_1_DrvrFatiLvlCfdec 7 " Reserved" 6 " Reserved" 5 " Reserved" 4 " Reserved" 3 " High" 2 " Medium" 1 " Low" 0 " Not Active" ;
VAL_ 1039 DMS_1_DrvrDistrLvlCfdec 7 " Reserved" 6 " Reserved" 5 " High" 4 " Medium High" 3 " Medium" 2 " Low Medium" 1 " Low" 0 " Not Active" ;
VAL_ 1039 DMS_1_DMSSt 7 " Reserved" 6 " Reserved" 5 " Reserved" 4 " Faulty" 3 " Active " 2 " Standby" 1 " Off" 0 " Not Active" ;
VAL_ 1039 DMS_1_DrvrFatiLvl 7 " Reserved" 6 " Reserved" 5 " Not Determined" 4 " Asleep" 3 " Microsleep" 2 " Drowsycted" 1 " Alert" 0 " Not Active" ;
VAL_ 1039 DMS_1_DrvrDistrLvl 7 " Reserved" 6 " Not Determined" 5 " Seriously distracted" 4 " Long Distracted " 3 " Distracted" 2 " Attentive" 1 " Invalid" 0 " Not Active" ;
VAL_ 1253 OMSMod 1 "ir" 0 "rgb" ;
VAL_ 1253 DVRSts 1 "Warning" 0 "No Warning" ;
VAL_ 1253 RMSSts 1 "Warning" 0 "No Warning" ;
VAL_ 1253 OMSSts 1 "Warning" 0 "No Warning" ;
VAL_ 1253 DMSSts 1 "Warning" 0 "No Warning" ;
VAL_ 1109 CWC_1_ChrgFlt 7 " Reserved" 6 " Reserved" 5 " Reserved" 4 " Foreign_matter_detected" 3 " High_Temp" 2 " High_Volf" 1 " Low_Volf" 0 " Not active" ;
VAL_ 1109 CWC_Phoneforgotten_ON_OFF_Sts 1 "Function ON" 0 "Function OFF" ;
VAL_ 1109 CWC_Phoneforgotten 1 "phone forgotten" 0 "phone not forgotten" ;
VAL_ 1109 CWC_workingSts 1 " CWC ON" 0 " CWC OFF" ;
VAL_ 1109 CWC_ChargingSts 3 " Charging fault" 2 " Charging completed" 1 " Charging" 0 " No charging" ;
VAL_ 1050 AVM_FactoryMode 1 " Factory Mode" 0 " Normal Mode" ;
VAL_ 1050 AVMFeedbackSts_RemoteMode 1 " On" 0 " Off" ;
VAL_ 1050 Reserved_ViewStsRsp 3 " Right" 2 " Left" 1 " Rear" 0 " Front" ;
VAL_ 1050 AVMDisplaySts 1 " On" 0 " Off" ;
VAL_ 1288 AVMStatusFault 1 " Failure" 0 " Normal" ;
VAL_ 1288 AVMFaultStatusCameraRight 1 " Failure" 0 " Normal" ;
VAL_ 1288 AVMFaultStatusCameraRear 1 " Failure" 0 " Normal" ;
VAL_ 1288 AVMFaultStatusCameraLeft 1 " Failure" 0 " Normal" ;
VAL_ 1288 AVMFaultStatusCameraFront 1 " Failure" 0 " Normal" ;
